VERSION ""

NS_ :

BS_:

BU_: L_3HKBD L_FHPTC L_ATCU L_2HKBD L_PCM L_ATCU_vMON L_EVNT L_HKBD L_RHPTC

BO_ 859 L_ATCU_Lib_11: 8 L_ATCU
 SG_ L_ATCU_Lib_Opt2LHModSwTyp : 0|2@1+ (1,0) [0|3] ""  L_ATCU_vMON
 SG_ L_ATCU_Lib_Opt2ndModBtn : 10|2@1+ (1,0) [0|3] ""  L_ATCU_vMON
 SG_ L_ATCU_Lib_Opt2ndOffSwTyp : 12|2@1+ (1,0) [0|3] ""  L_ATCU_vMON
 SG_ L_ATCU_Lib_Opt2ndTmpBtn : 14|2@1+ (1,0) [0|3] ""  L_ATCU_vMON
 SG_ L_ATCU_Lib_OptADS : 16|1@1+ (1,0) [0|1] ""  L_ATCU_vMON
 SG_ L_ATCU_Lib_OptAfterBlow : 17|1@1+ (1,0) [0|1] ""  L_ATCU_vMON
 SG_ L_ATCU_Lib_OptAutoStep : 18|2@1+ (1,0) [0|3] ""  L_ATCU_vMON
 SG_ L_ATCU_Lib_Opt2ndAutoBtn : 2|2@1+ (1,0) [0|3] ""  L_ATCU_vMON
 SG_ L_ATCU_Lib_OptAutoSwTyp : 20|1@1+ (1,0) [0|1] ""  L_ATCU_vMON
 SG_ L_ATCU_Lib_OptBATCoolingTyp : 21|2@1+ (1,0) [0|3] ""  L_ATCU_vMON
 SG_ L_ATCU_Lib_OptBlrSwKnob : 23|1@1+ (1,0) [0|1] ""  L_ATCU_vMON
 SG_ L_ATCU_Lib_OptComp : 24|3@1+ (1,0) [0|7] ""  L_ATCU_vMON
 SG_ L_ATCU_Lib_OptDrvHndSide : 27|1@1+ (1,0) [0|1] ""  L_ATCU_vMON
 SG_ L_ATCU_Lib_OptDrvOnly : 28|1@1+ (1,0) [0|1] ""  L_ATCU_vMON
 SG_ L_ATCU_Lib_OptFineDust : 29|1@1+ (1,0) [0|1] ""  L_ATCU_vMON
 SG_ L_ATCU_Lib_OptCoolHeatSeat : 30|2@1+ (1,0) [0|3] ""  L_ATCU_vMON
 SG_ L_ATCU_Lib_OptPTCTyp : 32|2@1+ (1,0) [0|3] ""  L_ATCU_vMON
 SG_ L_ATCU_Lib_OptLCDDisp : 34|2@1+ (1,0) [0|3] ""  L_ATCU_vMON
 SG_ L_ATCU_Lib_OptModSwTyp : 36|2@1+ (1,0) [0|3] ""  L_ATCU_vMON
 SG_ L_ATCU_Lib_OptOffSwTyp : 38|2@1+ (1,0) [0|3] ""  L_ATCU_vMON
 SG_ L_ATCU_Lib_Opt2ndAutoStep : 4|2@1+ (1,0) [0|3] ""  L_ATCU_vMON
 SG_ L_ATCU_Lib_OptNetworkTyp : 40|3@1+ (1,0) [0|7] ""  L_ATCU_vMON
 SG_ L_ATCU_Lib_OptPTCStep : 43|2@1+ (1,0) [0|3] ""  L_ATCU_vMON
 SG_ L_ATCU_Lib_OptPTG : 45|1@1+ (1,0) [0|1] ""  L_ATCU_vMON
 SG_ L_ATCU_Lib_OptROATyp : 46|1@1+ (1,0) [0|1] ""  L_ATCU_vMON
 SG_ L_ATCU_Lib_OptVRLED : 47|1@1+ (1,0) [0|1] ""  L_ATCU_vMON
 SG_ L_ATCU_Lib_OptRgn : 48|4@1+ (1,0) [0|15] ""  L_ATCU_vMON
 SG_ L_ATCU_Lib_OptSchdldVent : 52|1@1+ (1,0) [0|1] ""  L_ATCU_vMON
 SG_ L_ATCU_Lib_OptIntakeSwTyp : 53|1@1+ (1,0) [0|1] ""  L_ATCU_vMON
 SG_ L_ATCU_Lib_OptStrHeat : 54|2@1+ (1,0) [0|3] ""  L_ATCU_vMON
 SG_ L_ATCU_Lib_OptSync : 56|1@1+ (1,0) [0|1] ""  L_ATCU_vMON
 SG_ L_ATCU_Lib_OptTempSwKnob : 57|1@1+ (1,0) [0|1] ""  L_ATCU_vMON
 SG_ L_ATCU_Lib_OptThermostat : 58|1@1+ (1,0) [0|1] ""  L_ATCU_vMON
 SG_ L_ATCU_Lib_OptVehTyp : 59|3@1+ (1,0) [0|7] ""  L_ATCU_vMON
 SG_ L_ATCU_Lib_Opt2ndAutoSwTyp : 6|1@1+ (1,0) [0|1] ""  L_ATCU_vMON
 SG_ L_ATCU_Lib_OptWheelDrivePos : 62|2@1+ (1,0) [0|3] ""  L_ATCU_vMON
 SG_ L_ATCU_Lib_Opt2ndTempSwKnob : 7|1@1+ (1,0) [0|1] ""  L_ATCU_vMON
 SG_ L_ATCU_Lib_Opt2ndBlrBtn : 8|2@1+ (1,0) [0|3] ""  L_ATCU_vMON

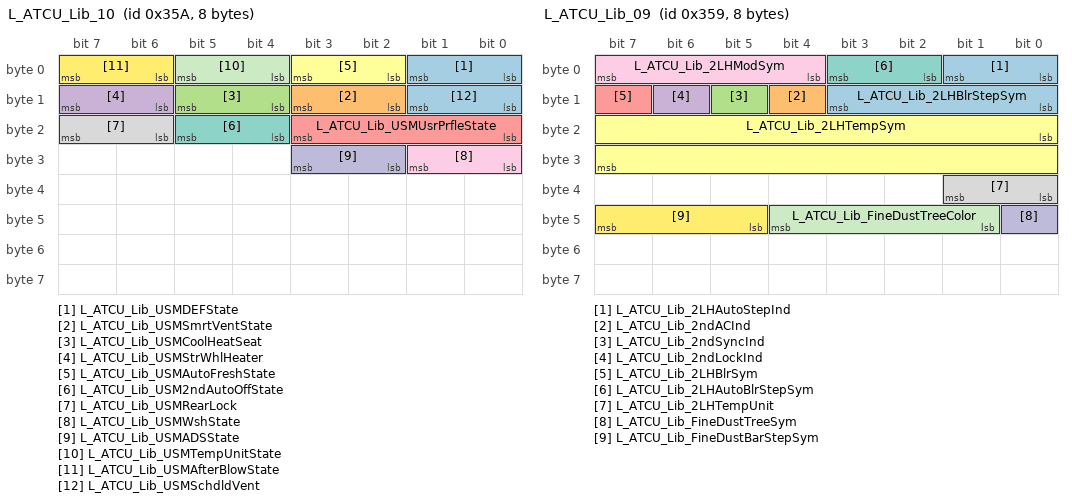
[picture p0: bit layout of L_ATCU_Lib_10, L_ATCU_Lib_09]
BO_ 858 L_ATCU_Lib_10: 8 L_ATCU
 SG_ L_ATCU_Lib_USMDEFState : 0|2@1+ (1,0) [0|1] ""  L_ATCU_vMON
 SG_ L_ATCU_Lib_USMSmrtVentState : 10|2@1+ (1,0) [0|3] ""  L_ATCU_vMON
 SG_ L_ATCU_Lib_USMCoolHeatSeat : 12|2@1+ (1,0) [0|3] ""  L_ATCU_vMON
 SG_ L_ATCU_Lib_USMStrWhlHeater : 14|2@1+ (1,0) [0|3] ""  L_ATCU_vMON
 SG_ L_ATCU_Lib_USMUsrPrfleState : 16|4@1+ (1,0) [0|15] ""  L_ATCU_vMON
 SG_ L_ATCU_Lib_USMAutoFreshState : 2|2@1+ (1,0) [0|1] ""  L_ATCU_vMON
 SG_ L_ATCU_Lib_USM2ndAutoOffState : 20|2@1+ (1,0) [0|3] ""  L_ATCU_vMON
 SG_ L_ATCU_Lib_USMRearLock : 22|2@1+ (1,0) [0|3] ""  L_ATCU_vMON
 SG_ L_ATCU_Lib_USMWshState : 24|2@1+ (1,0) [0|1] ""  L_ATCU_vMON
 SG_ L_ATCU_Lib_USMADSState : 26|2@1+ (1,0) [0|1] ""  L_ATCU_vMON
 SG_ L_ATCU_Lib_USMTempUnitState : 4|2@1+ (1,0) [0|3] ""  L_ATCU_vMON
 SG_ L_ATCU_Lib_USMAfterBlowState : 6|2@1+ (1,0) [0|3] ""  L_ATCU_vMON
 SG_ L_ATCU_Lib_USMSchdldVent : 8|2@1+ (1,0) [0|3] ""  L_ATCU_vMON

BO_ 857 L_ATCU_Lib_09: 8 L_ATCU
 SG_ L_ATCU_Lib_2LHAutoStepInd : 0|2@1+ (1,0) [0|3] ""  L_ATCU_vMON
 SG_ L_ATCU_Lib_2ndACInd : 12|1@1+ (1,0) [0|1] ""  L_ATCU_vMON
 SG_ L_ATCU_Lib_2ndSyncInd : 13|1@1+ (1,0) [0|1] ""  L_ATCU_vMON
 SG_ L_ATCU_Lib_2ndLockInd : 14|1@1+ (1,0) [0|1] ""  L_ATCU_vMON
 SG_ L_ATCU_Lib_2LHBlrSym : 15|1@1+ (1,0) [0|1] ""  L_ATCU_vMON
 SG_ L_ATCU_Lib_2LHTempSym : 16|16@1+ (1,0) [0|65535] ""  L_ATCU_vMON
 SG_ L_ATCU_Lib_2LHAutoBlrStepSym : 2|2@1+ (1,0) [0|3] ""  L_ATCU_vMON
 SG_ L_ATCU_Lib_2LHTempUnit : 32|2@1+ (1,0) [0|3] ""  L_ATCU_vMON
 SG_ L_ATCU_Lib_2LHModSym : 4|4@1+ (1,0) [0|15] ""  L_ATCU_vMON
 SG_ L_ATCU_Lib_FineDustTreeSym : 40|1@1+ (1,0) [0|1] ""  L_ATCU_vMON
 SG_ L_ATCU_Lib_FineDustTreeColor : 41|4@1+ (1,0) [0|15] ""  L_ATCU_vMON
 SG_ L_ATCU_Lib_FineDustBarStepSym : 45|3@1+ (1,0) [0|7] ""  L_ATCU_vMON
 SG_ L_ATCU_Lib_2LHBlrStepSym : 8|4@1+ (1,0) [0|15] ""  L_ATCU_vMON

BO_ 856 L_ATCU_Lib_08: 8 L_ATCU
 SG_ L_ATCU_Lib_AutoStepInd : 0|2@1+ (1,0) [0|3] ""  L_ATCU_vMON
 SG_ L_ATCU_Lib_BlrSym : 10|1@1+ (1,0) [0|1] ""  L_ATCU_vMON
 SG_ L_ATCU_Lib_BlrStepSym : 11|4@1+ (1,0) [0|15] ""  L_ATCU_vMON
 SG_ L_ATCU_Lib_IntakeRECInd : 15|1@1+ (1,0) [0|1] ""  L_ATCU_vMON
 SG_ L_ATCU_Lib_IntakeFREInd : 16|1@1+ (1,0) [0|1] ""  L_ATCU_vMON
 SG_ L_ATCU_Lib_ACInd : 17|1@1+ (1,0) [0|1] ""  L_ATCU_vMON
 SG_ L_ATCU_Lib_DEFInd : 18|1@1+ (1,0) [0|1] ""  L_ATCU_vMON
 SG_ L_ATCU_Lib_SyncInd : 19|1@1+ (1,0) [0|1] ""  L_ATCU_vMON
 SG_ L_ATCU_Lib_AutoBlrStepSym : 2|2@1+ (1,0) [0|3] ""  L_ATCU_vMON
 SG_ L_ATCU_Lib_DrvOnly : 20|1@1+ (1,0) [0|1] ""  L_ATCU_vMON
 SG_ L_ATCU_Lib_ADSSym : 21|1@1+ (1,0) [0|1] ""  L_ATCU_vMON
 SG_ L_ATCU_Lib_ModVentInd : 22|1@1+ (1,0) [0|1] ""  L_ATCU_vMON
 SG_ L_ATCU_Lib_DrvTempSym : 24|16@1+ (1,0) [0|65535] ""  L_ATCU_vMON
 SG_ L_ATCU_Lib_ModSym : 4|4@1+ (1,0) [0|15] ""  L_ATCU_vMON
 SG_ L_ATCU_Lib_AstTempSym : 40|16@1+ (1,0) [0|65535] ""  L_ATCU_vMON
 SG_ L_ATCU_Lib_DrvTempUnitSym : 56|2@1+ (1,0) [0|3] ""  L_ATCU_vMON
 SG_ L_ATCU_Lib_ModFloorInd : 8|1@1+ (1,0) [0|1] ""  L_ATCU_vMON
 SG_ L_ATCU_Lib_ModDEFInd : 9|1@1+ (1,0) [0|1] ""  L_ATCU_vMON

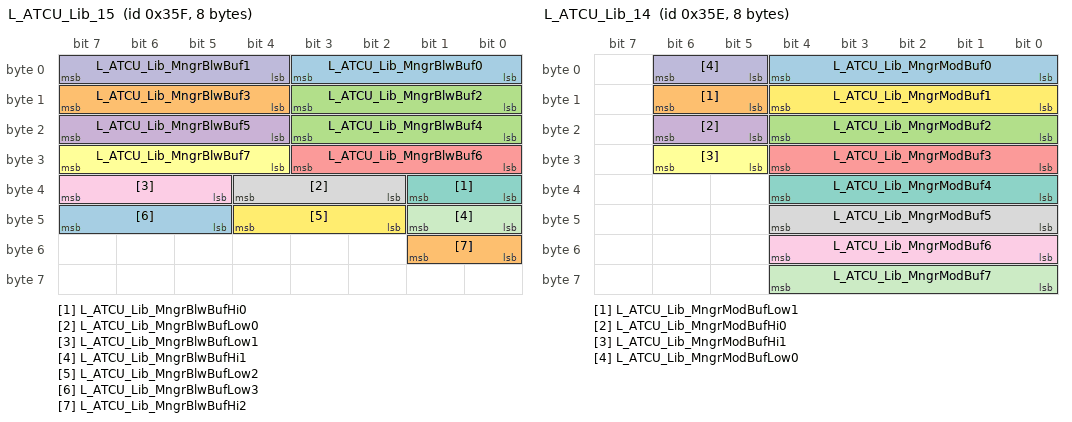
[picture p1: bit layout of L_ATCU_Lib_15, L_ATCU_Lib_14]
BO_ 863 L_ATCU_Lib_15: 8 L_ATCU
 SG_ L_ATCU_Lib_MngrBlwBuf0 : 0|4@1+ (1,0) [0|15] ""  L_ATCU_vMON
 SG_ L_ATCU_Lib_MngrBlwBuf3 : 12|4@1+ (1,0) [0|15] ""  L_ATCU_vMON
 SG_ L_ATCU_Lib_MngrBlwBuf4 : 16|4@1+ (1,0) [0|15] ""  L_ATCU_vMON
 SG_ L_ATCU_Lib_MngrBlwBuf5 : 20|4@1+ (1,0) [0|15] ""  L_ATCU_vMON
 SG_ L_ATCU_Lib_MngrBlwBuf6 : 24|4@1+ (1,0) [0|15] ""  L_ATCU_vMON
 SG_ L_ATCU_Lib_MngrBlwBuf7 : 28|4@1+ (1,0) [0|15] ""  L_ATCU_vMON
 SG_ L_ATCU_Lib_MngrBlwBufHi0 : 32|2@1+ (1,0) [0|3] ""  L_ATCU_vMON
 SG_ L_ATCU_Lib_MngrBlwBufLow0 : 34|3@1+ (1,0) [0|7] ""  L_ATCU_vMON
 SG_ L_ATCU_Lib_MngrBlwBufLow1 : 37|3@1+ (1,0) [0|7] ""  L_ATCU_vMON
 SG_ L_ATCU_Lib_MngrBlwBuf1 : 4|4@1+ (1,0) [0|15] ""  L_ATCU_vMON
 SG_ L_ATCU_Lib_MngrBlwBufHi1 : 40|2@1+ (1,0) [0|3] ""  L_ATCU_vMON
 SG_ L_ATCU_Lib_MngrBlwBufLow2 : 42|3@1+ (1,0) [0|7] ""  L_ATCU_vMON
 SG_ L_ATCU_Lib_MngrBlwBufLow3 : 45|3@1+ (1,0) [0|7] ""  L_ATCU_vMON
 SG_ L_ATCU_Lib_MngrBlwBufHi2 : 48|2@1+ (1,0) [0|3] ""  L_ATCU_vMON
 SG_ L_ATCU_Lib_MngrBlwBuf2 : 8|4@1+ (1,0) [0|15] ""  L_ATCU_vMON

BO_ 862 L_ATCU_Lib_14: 8 L_ATCU
 SG_ L_ATCU_Lib_MngrModBuf0 : 0|5@1+ (1,0) [0|31] ""  L_ATCU_vMON
 SG_ L_ATCU_Lib_MngrModBufLow1 : 13|2@1+ (1,0) [0|3] ""  L_ATCU_vMON
 SG_ L_ATCU_Lib_MngrModBuf2 : 16|5@1+ (1,0) [0|31] ""  L_ATCU_vMON
 SG_ L_ATCU_Lib_MngrModBufHi0 : 21|2@1+ (1,0) [0|3] ""  L_ATCU_vMON
 SG_ L_ATCU_Lib_MngrModBuf3 : 24|5@1+ (1,0) [0|31] ""  L_ATCU_vMON
 SG_ L_ATCU_Lib_MngrModBufHi1 : 29|2@1+ (1,0) [0|3] ""  L_ATCU_vMON
 SG_ L_ATCU_Lib_MngrModBuf4 : 32|5@1+ (1,0) [0|31] ""  L_ATCU_vMON
 SG_ L_ATCU_Lib_MngrModBuf5 : 40|5@1+ (1,0) [0|31] ""  L_ATCU_vMON
 SG_ L_ATCU_Lib_MngrModBuf6 : 48|5@1+ (1,0) [0|31] ""  L_ATCU_vMON
 SG_ L_ATCU_Lib_MngrModBufLow0 : 5|2@1+ (1,0) [0|3] ""  L_ATCU_vMON
 SG_ L_ATCU_Lib_MngrModBuf7 : 56|5@1+ (1,0) [0|31] ""  L_ATCU_vMON
 SG_ L_ATCU_Lib_MngrModBuf1 : 8|5@1+ (1,0) [0|31] ""  L_ATCU_vMON

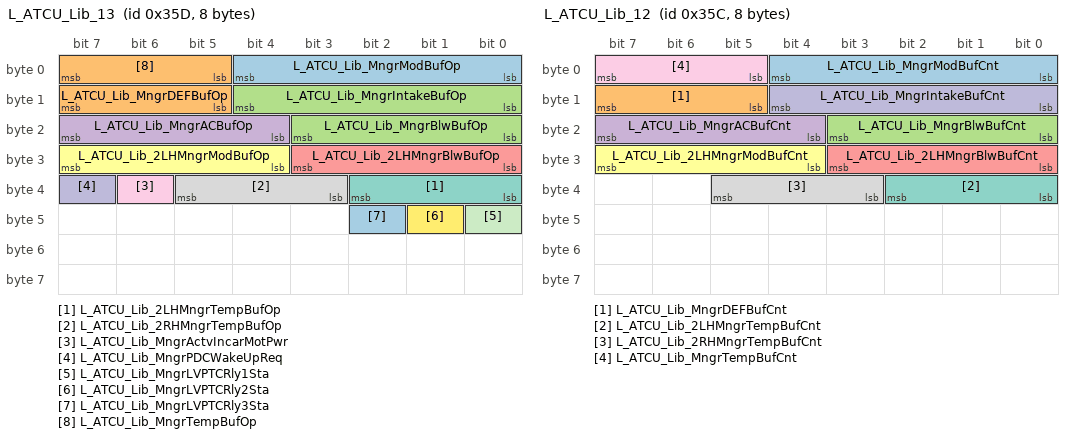
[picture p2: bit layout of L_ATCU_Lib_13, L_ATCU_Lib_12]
BO_ 861 L_ATCU_Lib_13: 8 L_ATCU
 SG_ L_ATCU_Lib_MngrModBufOp : 0|5@1+ (1,0) [0|31] ""  L_ATCU_vMON
 SG_ L_ATCU_Lib_MngrDEFBufOp : 13|3@1+ (1,0) [0|7] ""  L_ATCU_vMON
 SG_ L_ATCU_Lib_MngrBlwBufOp : 16|4@1+ (1,0) [0|15] ""  L_ATCU_vMON
 SG_ L_ATCU_Lib_MngrACBufOp : 20|4@1+ (1,0) [0|15] ""  L_ATCU_vMON
 SG_ L_ATCU_Lib_2LHMngrBlwBufOp : 24|4@1+ (1,0) [0|15] ""  L_ATCU_vMON
 SG_ L_ATCU_Lib_2LHMngrModBufOp : 28|4@1+ (1,0) [0|15] ""  L_ATCU_vMON
 SG_ L_ATCU_Lib_2LHMngrTempBufOp : 32|3@1+ (1,0) [0|7] ""  L_ATCU_vMON
 SG_ L_ATCU_Lib_2RHMngrTempBufOp : 35|3@1+ (1,0) [0|7] ""  L_ATCU_vMON
 SG_ L_ATCU_Lib_MngrActvIncarMotPwr : 38|1@1+ (1,0) [0|1] ""  L_ATCU_vMON
 SG_ L_ATCU_Lib_MngrPDCWakeUpReq : 39|1@1+ (1,0) [0|1] ""  L_ATCU_vMON
 SG_ L_ATCU_Lib_MngrLVPTCRly1Sta : 40|1@1+ (1,0) [0|1] ""  L_ATCU_vMON
 SG_ L_ATCU_Lib_MngrLVPTCRly2Sta : 41|1@1+ (1,0) [0|1] ""  L_ATCU_vMON
 SG_ L_ATCU_Lib_MngrLVPTCRly3Sta : 42|1@1+ (1,0) [0|1] ""  L_ATCU_vMON
 SG_ L_ATCU_Lib_MngrTempBufOp : 5|3@1+ (1,0) [0|7] ""  L_ATCU_vMON
 SG_ L_ATCU_Lib_MngrIntakeBufOp : 8|5@1+ (1,0) [0|31] ""  L_ATCU_vMON

BO_ 860 L_ATCU_Lib_12: 8 L_ATCU
 SG_ L_ATCU_Lib_MngrModBufCnt : 0|5@1+ (1,0) [0|31] ""  L_ATCU_vMON
 SG_ L_ATCU_Lib_MngrDEFBufCnt : 13|3@1+ (1,0) [0|7] ""  L_ATCU_vMON
 SG_ L_ATCU_Lib_MngrBlwBufCnt : 16|4@1+ (1,0) [0|15] ""  L_ATCU_vMON
 SG_ L_ATCU_Lib_MngrACBufCnt : 20|4@1+ (1,0) [0|15] ""  L_ATCU_vMON
 SG_ L_ATCU_Lib_2LHMngrBlwBufCnt : 24|4@1+ (1,0) [0|15] ""  L_ATCU_vMON
 SG_ L_ATCU_Lib_2LHMngrModBufCnt : 28|4@1+ (1,0) [0|15] ""  L_ATCU_vMON
 SG_ L_ATCU_Lib_2LHMngrTempBufCnt : 32|3@1+ (1,0) [0|7] ""  L_ATCU_vMON
 SG_ L_ATCU_Lib_2RHMngrTempBufCnt : 35|3@1+ (1,0) [0|7] ""  L_ATCU_vMON
 SG_ L_ATCU_Lib_MngrTempBufCnt : 5|3@1+ (1,0) [0|7] ""  L_ATCU_vMON
 SG_ L_ATCU_Lib_MngrIntakeBufCnt : 8|5@1+ (1,0) [0|31] ""  L_ATCU_vMON

BO_ 834 L_ATCU_MON_49: 8 L_ATCU_vMON
 SG_ MON_DiagCOM_AcnOpPerm : 0|2@1+ (1,0) [0|0] ""  L_ATCU
 SG_ MON_DiagCOM_BMSTmout : 10|2@1+ (1,0) [0|0] ""  L_ATCU
 SG_ MON_DiagCOM_DrvClHtStOpt : 12|2@1+ (1,0) [0|0] ""  L_ATCU
 SG_ MON_DiagCOM_AstClHtStOpt : 14|2@1+ (1,0) [0|0] ""  L_ATCU
 SG_ MON_DiagCOM_EcoModSw : 16|2@1+ (1,0) [0|0] ""  L_ATCU
 SG_ MON_DiagCOM_EcompTmout : 18|2@1+ (1,0) [0|0] ""  L_ATCU
 SG_ MON_DiagCOM_APT : 2|2@1+ (1,0) [0|0] ""  L_ATCU
 SG_ MON_DiagCOM_EMSVehSpd : 20|2@1+ (1,0) [0|0] ""  L_ATCU
 SG_ MON_DiagCOM_EngCool : 22|2@1+ (1,0) [0|0] ""  L_ATCU
 SG_ MON_DiagCOM_EngOpMod : 24|2@1+ (1,0) [0|0] ""  L_ATCU
 SG_ MON_DiagCOM_HEVRdy : 26|2@1+ (1,0) [0|0] ""  L_ATCU
 SG_ MON_DiagCOM_HVPTCTmout : 28|2@1+ (1,0) [0|0] ""  L_ATCU
 SG_ MON_DiagCOM_LDCWatt : 30|2@1+ (1,0) [0|0] ""  L_ATCU
 SG_ MON_DiagCOM_LHPhoto : 32|2@1+ (1,0) [0|0] ""  L_ATCU
 SG_ MON_DiagCOM_MainRlyOnSta : 34|2@1+ (1,0) [0|0] ""  L_ATCU
 SG_ MON_DiagCOM_MCUTmout : 36|2@1+ (1,0) [0|0] ""  L_ATCU
 SG_ MON_DiagCOM_PMSnsr : 38|2@1+ (1,0) [0|0] ""  L_ATCU
 SG_ MON_DiagCOM_BatChlrEXVDiag : 4|2@1+ (1,0) [0|0] ""  L_ATCU
 SG_ MON_DiagCOM_PnlBusOff : 40|2@1+ (1,0) [0|0] ""  L_ATCU
 SG_ MON_DiagCOM_PTGOpt : 42|2@1+ (1,0) [0|0] ""  L_ATCU
 SG_ MON_DiagCOM_RHPhoto : 44|2@1+ (1,0) [0|0] ""  L_ATCU
 SG_ MON_DiagCOM_RPM : 46|2@1+ (1,0) [0|0] ""  L_ATCU
 SG_ MON_DiagCOM_SideMirAmb : 48|2@1+ (1,0) [0|0] ""  L_ATCU
 SG_ MON_DiagCOM_ServiceMod : 50|2@1+ (1,0) [0|0] ""  L_ATCU
 SG_ MON_DiagCOM_StrHtOpt : 52|2@1+ (1,0) [0|0] ""  L_ATCU
 SG_ MON_DiagCOM_TCUVehSpd : 54|2@1+ (1,0) [0|0] ""  L_ATCU
 SG_ MON_DiagCOM_Torque : 56|2@1+ (1,0) [0|0] ""  L_ATCU
 SG_ MON_DiagCOM_VehBusOff : 58|2@1+ (1,0) [0|0] ""  L_ATCU
 SG_ MON_DiagCOM_BATSoc : 6|2@1+ (1,0) [0|0] ""  L_ATCU
 SG_ MON_DiagCOM_WhlSpd : 60|2@1+ (1,0) [0|0] ""  L_ATCU
 SG_ MON_DiagCOM_ClmtBusOff : 62|2@1+ (1,0) [0|0] ""  L_ATCU
 SG_ MON_DiagCOM_BMSIntakeReq : 8|2@1+ (1,0) [0|0] ""  L_ATCU

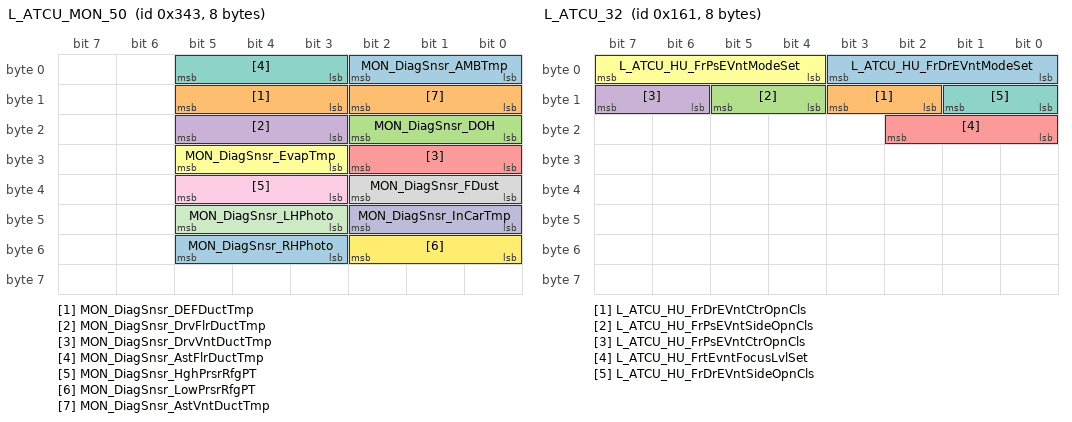
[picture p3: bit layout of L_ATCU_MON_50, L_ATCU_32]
BO_ 835 L_ATCU_MON_50: 8 L_ATCU_vMON
 SG_ MON_DiagSnsr_AMBTmp : 0|3@1+ (1,0) [0|0] ""  L_ATCU
 SG_ MON_DiagSnsr_DEFDuctTmp : 11|3@1+ (1,0) [0|0] ""  L_ATCU
 SG_ MON_DiagSnsr_DOH : 16|3@1+ (1,0) [0|0] ""  L_ATCU
 SG_ MON_DiagSnsr_DrvFlrDuctTmp : 19|3@1+ (1,0) [0|0] ""  L_ATCU
 SG_ MON_DiagSnsr_DrvVntDuctTmp : 24|3@1+ (1,0) [0|0] ""  L_ATCU
 SG_ MON_DiagSnsr_EvapTmp : 27|3@1+ (1,0) [0|0] ""  L_ATCU
 SG_ MON_DiagSnsr_AstFlrDuctTmp : 3|3@1+ (1,0) [0|0] ""  L_ATCU
 SG_ MON_DiagSnsr_FDust : 32|3@1+ (1,0) [0|0] ""  L_ATCU
 SG_ MON_DiagSnsr_HghPrsrRfgPT : 35|3@1+ (1,0) [0|0] ""  L_ATCU
 SG_ MON_DiagSnsr_InCarTmp : 40|3@1+ (1,0) [0|0] ""  L_ATCU
 SG_ MON_DiagSnsr_LHPhoto : 43|3@1+ (1,0) [0|0] ""  L_ATCU
 SG_ MON_DiagSnsr_LowPrsrRfgPT : 48|3@1+ (1,0) [0|0] ""  L_ATCU
 SG_ MON_DiagSnsr_RHPhoto : 51|3@1+ (1,0) [0|0] ""  L_ATCU
 SG_ MON_DiagSnsr_AstVntDuctTmp : 8|3@1+ (1,0) [0|0] ""  L_ATCU

BO_ 833 L_ATCU_MON_48: 8 L_ATCU_vMON
 SG_ MON_DiagAct_DrvModDrLck : 0|2@1+ (1,0) [0|0] ""  L_ATCU
 SG_ MON_DiagAct_AstModDrOpnSrt : 10|3@1+ (1,0) [0|0] ""  L_ATCU
 SG_ MON_DiagAct_AstTmpDrOpnSrt : 13|3@1+ (1,0) [0|0] ""  L_ATCU
 SG_ MON_DiagAct_DrvTmpDrLck : 16|2@1+ (1,0) [0|0] ""  L_ATCU
 SG_ MON_DiagAct_AstTmpDrLck : 18|2@1+ (1,0) [0|0] ""  L_ATCU
 SG_ MON_DiagAct_DrvModDrOpnSrt : 2|3@1+ (1,0) [0|0] ""  L_ATCU
 SG_ MON_DiagAct_DEFDrLck : 20|2@1+ (1,0) [0|0] ""  L_ATCU
 SG_ MON_DiagAct_IntakeDrLck : 22|2@1+ (1,0) [0|0] ""  L_ATCU
 SG_ MON_DiagAct_IntakeDrOpnSrt : 24|3@1+ (1,0) [0|0] ""  L_ATCU
 SG_ MON_DiagAct_DEFDrOpnSrt : 27|3@1+ (1,0) [0|0] ""  L_ATCU
 SG_ MON_DiagAct_ECompIntlck : 30|2@1+ (1,0) [0|0] ""  L_ATCU
 SG_ MON_DiagAct_HVPTCIntlck : 32|2@1+ (1,0) [0|0] ""  L_ATCU
 SG_ MON_DiagAct_BatChlrEXVOpnSrt : 34|3@1+ (1,0) [0|0] ""  L_ATCU
 SG_ MON_DiagAct_EvapTXVOpnSrt : 37|3@1+ (1,0) [0|0] ""  L_ATCU
 SG_ MON_DiagAct_FrtPWMBlr : 40|4@1+ (1,0) [0|0] ""  L_ATCU
 SG_ MON_DiagAct_ECV : 44|3@1+ (1,0) [0|0] ""  L_ATCU
 SG_ MON_DiagAct_Rfgrant : 48|3@1+ (1,0) [0|0] ""  L_ATCU
 SG_ MON_DiagAct_DrvTmpDrOpnSrt : 5|3@1+ (1,0) [0|0] ""  L_ATCU
 SG_ MON_DiagAct_VRLed : 52|3@1+ (1,0) [0|0] ""  L_ATCU
 SG_ MON_DiagAct_AstModDrLck : 8|2@1+ (1,0) [0|0] ""  L_ATCU

BO_ 353 L_ATCU_32: 8 L_ATCU
 SG_ L_ATCU_HU_FrDrEVntModeSet : 0|4@1+ (1,0) [0|0] ""  L_EVNT
 SG_ L_ATCU_HU_FrDrEVntCtrOpnCls : 10|2@1+ (1,0) [0|0] ""  L_EVNT
 SG_ L_ATCU_HU_FrPsEVntSideOpnCls : 12|2@1+ (1,0) [0|0] ""  L_EVNT
 SG_ L_ATCU_HU_FrPsEVntCtrOpnCls : 14|2@1+ (1,0) [0|0] ""  L_EVNT
 SG_ L_ATCU_HU_FrtEvntFocusLvlSet : 16|3@1+ (1,0) [0|0] ""  L_EVNT
 SG_ L_ATCU_HU_FrPsEVntModeSet : 4|4@1+ (1,0) [0|0] ""  L_EVNT
 SG_ L_ATCU_HU_FrDrEVntSideOpnCls : 8|2@1+ (1,0) [0|0] ""  L_EVNT

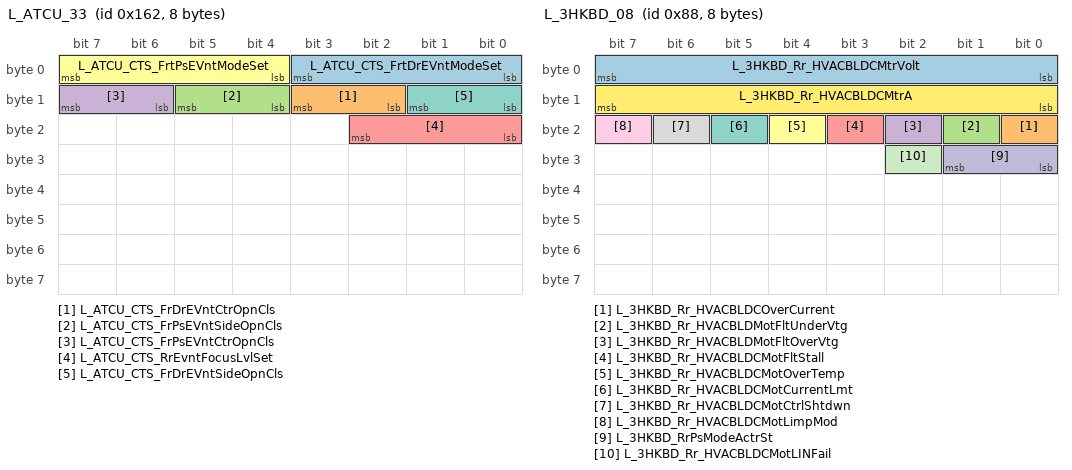
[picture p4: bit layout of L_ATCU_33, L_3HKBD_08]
BO_ 354 L_ATCU_33: 8 L_ATCU
 SG_ L_ATCU_CTS_FrtDrEVntModeSet : 0|4@1+ (1,0) [0|0] ""  L_EVNT
 SG_ L_ATCU_CTS_FrDrEVntCtrOpnCls : 10|2@1+ (1,0) [0|0] ""  L_EVNT
 SG_ L_ATCU_CTS_FrPsEVntSideOpnCls : 12|2@1+ (1,0) [0|0] ""  L_EVNT
 SG_ L_ATCU_CTS_FrPsEVntCtrOpnCls : 14|2@1+ (1,0) [0|0] ""  L_EVNT
 SG_ L_ATCU_CTS_RrEvntFocusLvlSet : 16|3@1+ (1,0) [0|0] ""  L_EVNT
 SG_ L_ATCU_CTS_FrtPsEVntModeSet : 4|4@1+ (1,0) [0|0] ""  L_EVNT
 SG_ L_ATCU_CTS_FrDrEVntSideOpnCls : 8|2@1+ (1,0) [0|0] ""  L_EVNT

BO_ 136 L_3HKBD_08: 8 L_3HKBD
 SG_ L_3HKBD_Rr_HVACBLDCMtrVolt : 0|8@1+ (0.1,0) [0|0] "V"  L_ATCU
 SG_ L_3HKBD_Rr_HVACBLDCOverCurrent : 16|1@1+ (1,0) [0|0] ""  L_ATCU
 SG_ L_3HKBD_Rr_HVACBLDMotFltUnderVtg : 17|1@1+ (1,0) [0|0] ""  L_ATCU
 SG_ L_3HKBD_Rr_HVACBLDMotFltOverVtg : 18|1@1+ (1,0) [0|0] ""  L_ATCU
 SG_ L_3HKBD_Rr_HVACBLDCMotFltStall : 19|1@1+ (1,0) [0|0] ""  L_ATCU
 SG_ L_3HKBD_Rr_HVACBLDCMotOverTemp : 20|1@1+ (1,0) [0|0] ""  L_ATCU
 SG_ L_3HKBD_Rr_HVACBLDCMotCurrentLmt : 21|1@1+ (1,0) [0|0] ""  L_ATCU
 SG_ L_3HKBD_Rr_HVACBLDCMotCtrlShtdwn : 22|1@1+ (1,0) [0|0] ""  L_ATCU
 SG_ L_3HKBD_Rr_HVACBLDCMotLimpMod : 23|1@1+ (1,0) [0|0] ""  L_ATCU
 SG_ L_3HKBD_RrPsModeActrSt : 24|2@1+ (1,0) [0|0] ""  L_ATCU
 SG_ L_3HKBD_Rr_HVACBLDCMotLINFail : 26|1@1+ (1,0) [0|0] ""  L_ATCU
 SG_ L_3HKBD_Rr_HVACBLDCMtrA : 8|8@1+ (0.2,0) [0|0] "A"  L_ATCU

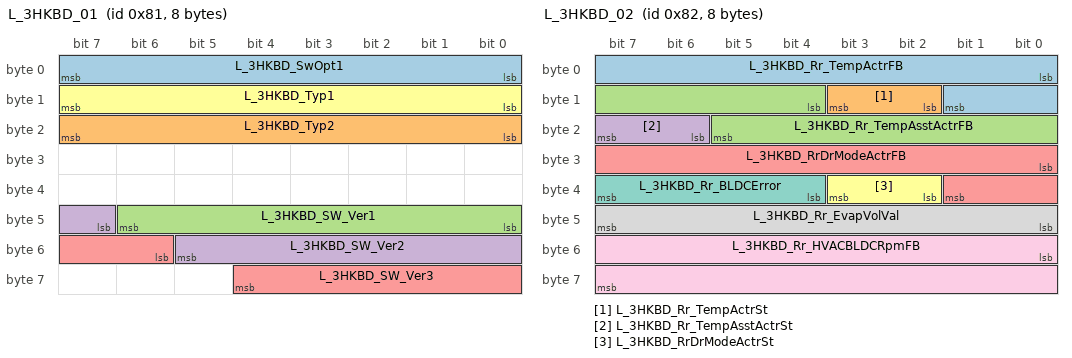
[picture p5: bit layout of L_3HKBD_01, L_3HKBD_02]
BO_ 129 L_3HKBD_01: 8 L_3HKBD
 SG_ L_3HKBD_SwOpt1 : 0|8@1+ (1,1) [0|0] ""  L_ATCU
 SG_ L_3HKBD_Typ2 : 16|8@1+ (1,0) [0|0] ""  L_ATCU
 SG_ L_3HKBD_SW_Ver1 : 40|7@1+ (1,0) [0|0] ""  L_ATCU_vMON
 SG_ L_3HKBD_SW_Ver2 : 47|7@1+ (1,0) [0|0] ""  L_ATCU_vMON
 SG_ L_3HKBD_SW_Ver3 : 54|7@1+ (1,0) [0|0] ""  L_ATCU_vMON
 SG_ L_3HKBD_Typ1 : 8|8@1+ (1,0) [0|0] ""  L_ATCU

BO_ 131 L_3HKBD_03: 8 L_3HKBD
 SG_ L_3HKBD_SwBtnTyp : 0|40@1+ (1,0) [0|0] ""  L_ATCU
 SG_ L_3HKBD_ResetOpSta : 62|2@1+ (1,0) [0|0] ""  L_ATCU

BO_ 130 L_3HKBD_02: 8 L_3HKBD
 SG_ L_3HKBD_Rr_TempActrFB : 0|10@1+ (1,0) [0|0] "AD"  L_ATCU
 SG_ L_3HKBD_Rr_TempActrSt : 10|2@1+ (1,0) [0|0] ""  L_ATCU
 SG_ L_3HKBD_Rr_TempAsstActrFB : 12|10@1+ (1,0) [0|0] "AD"  L_ATCU
 SG_ L_3HKBD_Rr_TempAsstActrSt : 22|2@1+ (1,0) [0|0] ""  L_ATCU
 SG_ L_3HKBD_RrDrModeActrFB : 24|10@1+ (1,0) [0|0] "AD"  L_ATCU
 SG_ L_3HKBD_RrDrModeActrSt : 34|2@1+ (1,0) [0|0] ""  L_ATCU
 SG_ L_3HKBD_Rr_BLDCError : 36|4@1+ (1,0) [0|0] ""  L_ATCU
 SG_ L_3HKBD_Rr_EvapVolVal : 40|8@1+ (0.02,0) [0|0] "V"  L_ATCU
 SG_ L_3HKBD_Rr_HVACBLDCRpmFB : 48|16@1+ (5,0) [0|0] "RPM"  L_ATCU

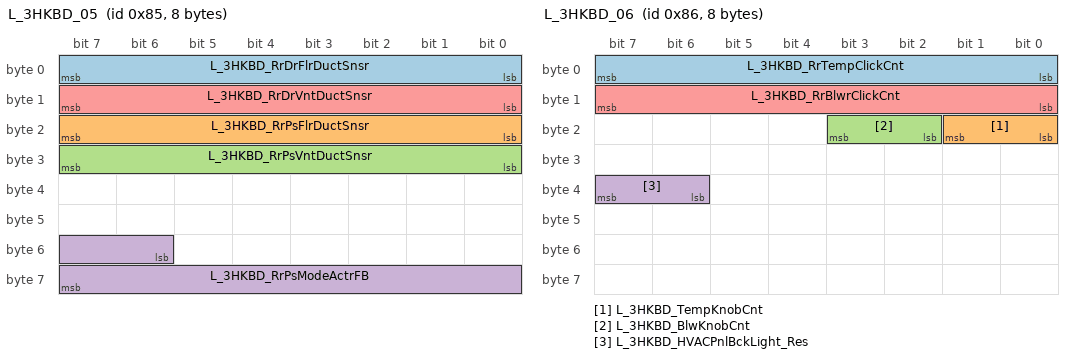
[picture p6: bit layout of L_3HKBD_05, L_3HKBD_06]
BO_ 133 L_3HKBD_05: 8 L_3HKBD
 SG_ L_3HKBD_RrDrFlrDuctSnsr : 0|8@1+ (0.02,0) [0|0] "V"  L_ATCU
 SG_ L_3HKBD_RrPsFlrDuctSnsr : 16|8@1+ (0.02,0) [0|0] ""  L_ATCU
 SG_ L_3HKBD_RrPsVntDuctSnsr : 24|8@1+ (0.02,0) [0|0] ""  L_ATCU
 SG_ L_3HKBD_RrPsModeActrFB : 54|10@1+ (1,0) [0|0] ""  L_ATCU
 SG_ L_3HKBD_RrDrVntDuctSnsr : 8|8@1+ (0.02,0) [0|0] "V"  L_ATCU

BO_ 132 L_3HKBD_04: 8 L_3HKBD
 SG_ L_3HKBD_RrTempDnSw : 0|1@1+ (1,1) [0|0] ""  L_ATCU
 SG_ L_3HKBD_RrTempUpSw : 1|1@1+ (1,1) [0|0] ""  L_ATCU
 SG_ L_3HKBD_RrAutoSw : 10|1@1+ (1,0) [0|0] ""  L_ATCU
 SG_ L_3HKBD_RrOffSw : 11|1@1+ (1,0) [0|0] ""  L_ATCU
 SG_ L_3HKBD_RrSyncSw : 12|1@1+ (1,0) [0|0] ""  L_ATCU
 SG_ L_3HKBD_RLStHtrSwReq : 13|1@1+ (1,0) [0|0] ""  L_ATCU
 SG_ L_3HKBD_RLStVentSwReq : 14|1@1+ (1,0) [0|0] ""  L_ATCU
 SG_ L_3HKBD_RRStHtrSwReq : 15|1@1+ (1,0) [0|0] ""  L_ATCU
 SG_ L_3HKBD_RRStVentSwReq : 16|1@1+ (1,0) [0|0] ""  L_ATCU
 SG_ L_3HKBD_RrBlwDnOffSw : 17|1@1+ (1,0) [0|0] ""  L_ATCU
 SG_ L_3HKBD_RrOnOffSet : 18|2@1+ (1,0) [0|0] ""  L_ATCU
 SG_ L_3HKBD_RrBlwDnSw : 2|1@1+ (1,0) [0|0] ""  L_ATCU
 SG_ L_3HKBD_RrblwUpMaxSw : 20|1@1+ (1,0) [0|0] ""  L_ATCU
 SG_ L_3HKBD_RrBlwUpSw : 3|1@1+ (1,0) [0|0] ""  L_ATCU
 SG_ L_3HKBD_RrModeDnSw : 4|1@1+ (1,0) [0|0] ""  L_ATCU
 SG_ L_3HKBD_RrModeUpSw : 5|1@1+ (1,0) [0|0] ""  L_ATCU
 SG_ L_3HKBD_RrModeSw : 6|1@1+ (1,0) [0|0] ""  L_ATCU
 SG_ L_3HKBD_RrModeVentSw : 7|1@1+ (1,0) [0|0] ""  L_ATCU
 SG_ L_3HKBD_RrModeFloorSw : 8|1@1+ (1,0) [0|0] ""  L_ATCU
 SG_ L_3HKBD_RrModeBiLvlSw : 9|1@1+ (1,0) [0|0] ""  L_ATCU

BO_ 134 L_3HKBD_06: 8 L_3HKBD
 SG_ L_3HKBD_RrTempClickCnt : 0|8@1+ (1,1) [0|0] ""  L_ATCU
 SG_ L_3HKBD_TempKnobCnt : 16|2@1+ (1,1) [0|0] ""  L_ATCU
 SG_ L_3HKBD_BlwKnobCnt : 18|2@1+ (1,1) [0|0] ""  L_ATCU
 SG_ L_3HKBD_HVACPnlBckLight_Res : 38|2@1+ (1,0) [0|0] ""  L_ATCU
 SG_ L_3HKBD_RrBlwrClickCnt : 8|8@1+ (1,1) [0|0] ""  L_ATCU

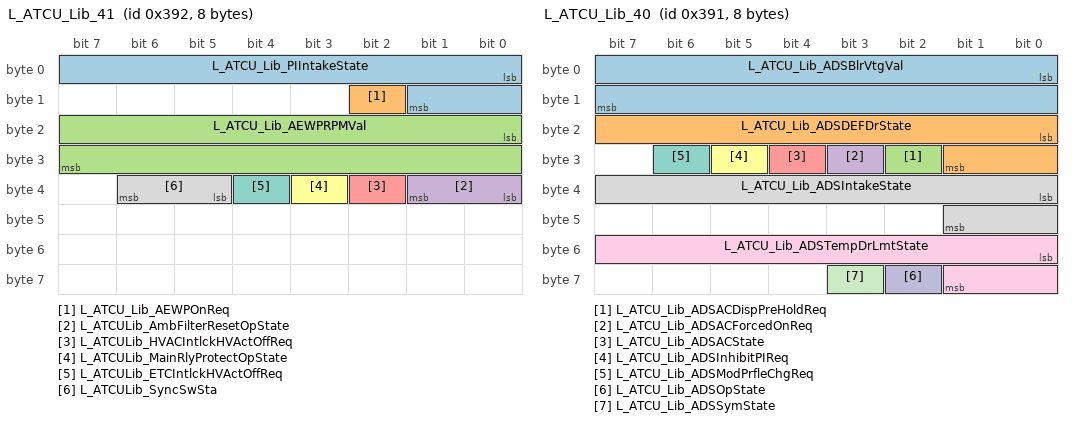
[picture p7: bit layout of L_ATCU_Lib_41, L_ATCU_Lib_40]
BO_ 914 L_ATCU_Lib_41: 8 L_ATCU
 SG_ L_ATCU_Lib_PIIntakeState : 0|10@1+ (1,0) [0|1023] ""  L_ATCU_vMON
 SG_ L_ATCU_Lib_AEWPOnReq : 10|1@1+ (1,0) [0|1] ""  L_ATCU_vMON
 SG_ L_ATCU_Lib_AEWPRPMVal : 16|16@1+ (1,0) [0|65535] ""  L_ATCU_vMON
 SG_ L_ATCULib_AmbFilterResetOpState : 32|2@1+ (1,0) [0|0] ""  L_ATCU_vMON
 SG_ L_ATCULib_HVACIntlckHVActOffReq : 34|1@1+ (1,0) [0|0] ""  L_ATCU_vMON
 SG_ L_ATCULib_MainRlyProtectOpState : 35|1@1+ (1,0) [0|0] ""  L_ATCU_vMON
 SG_ L_ATCULib_ETCIntlckHVActOffReq : 36|1@1+ (1,0) [0|0] ""  L_ATCU_vMON
 SG_ L_ATCULib_SyncSwSta : 37|2@1+ (1,0) [0|0] ""  L_ATCU_vMON

BO_ 913 L_ATCU_Lib_40: 8 L_ATCU
 SG_ L_ATCU_Lib_ADSBlrVtgVal : 0|16@1+ (1,0) [0|65535] ""  L_ATCU_vMON
 SG_ L_ATCU_Lib_ADSDEFDrState : 16|10@1+ (1,0) [0|1023] ""  L_ATCU_vMON
 SG_ L_ATCU_Lib_ADSACDispPreHoldReq : 26|1@1+ (1,0) [0|1] ""  L_ATCU_vMON
 SG_ L_ATCU_Lib_ADSACForcedOnReq : 27|1@1+ (1,0) [0|1] ""  L_ATCU_vMON
 SG_ L_ATCU_Lib_ADSACState : 28|1@1+ (1,0) [0|1] ""  L_ATCU_vMON
 SG_ L_ATCU_Lib_ADSInhibitPIReq : 29|1@1+ (1,0) [0|1] ""  L_ATCU_vMON
 SG_ L_ATCU_Lib_ADSModPrfleChgReq : 30|1@1+ (1,0) [0|1] ""  L_ATCU_vMON
 SG_ L_ATCU_Lib_ADSIntakeState : 32|10@1+ (1,0) [0|1023] ""  L_ATCU_vMON
 SG_ L_ATCU_Lib_ADSTempDrLmtState : 48|10@1+ (1,0) [0|1023] ""  L_ATCU_vMON
 SG_ L_ATCU_Lib_ADSOpState : 58|1@1+ (1,0) [0|1] ""  L_ATCU_vMON
 SG_ L_ATCU_Lib_ADSSymState : 59|1@1+ (1,0) [0|1] ""  L_ATCU_vMON

CM_ BO_ 129 "[PE] Periodic and On Event";
CM_ SG_ 129 L_3HKBD_SwOpt1 "3HKBD_SwitchOption1";
CM_ SG_ 129 L_3HKBD_Typ2 "3HKBD_Type2";
CM_ SG_ 129 L_3HKBD_SW_Ver1 "3HKBD_SoftWare_Version1";
CM_ SG_ 129 L_3HKBD_SW_Ver2 "3HKBD_SoftWare_Version2";
CM_ SG_ 129 L_3HKBD_SW_Ver3 "3HKBD_SoftWare_Version3";
CM_ SG_ 129 L_3HKBD_Typ1 "3HKBD_Type1";
CM_ BO_ 130 "[P] Periodic";
CM_ SG_ 130 L_3HKBD_Rr_TempActrFB "3HKBD_Rear_TempActuatorFeedback";
CM_ SG_ 130 L_3HKBD_Rr_TempActrSt "3HKBD_Rear_TempActuatorStatus";
CM_ SG_ 130 L_3HKBD_Rr_TempAsstActrFB "3HKBD_Rear_TempAssistActuatorFeedback";
CM_ SG_ 130 L_3HKBD_Rr_TempAsstActrSt "3HKBD_Rear_TempAssistActuatorStatus";
CM_ SG_ 130 L_3HKBD_RrDrModeActrFB "3HKBD_RearDriverModeActuatorFeedback";
CM_ SG_ 130 L_3HKBD_RrDrModeActrSt "3HKBD_RearDriverModeActuatorStatus";
CM_ SG_ 130 L_3HKBD_Rr_BLDCError "3HKBD_Rear_BLDCError";
CM_ SG_ 130 L_3HKBD_Rr_EvapVolVal "3HKBD_Rear_EvaporatorVoltageValue";
CM_ SG_ 130 L_3HKBD_Rr_HVACBLDCRpmFB "3HKBD_Rear_HVACBLDCRpmFeedBack";
CM_ BO_ 131 "[PE] Periodic and On Event";
CM_ SG_ 131 L_3HKBD_SwBtnTyp "3HKBD_SwitchButtonType";
CM_ SG_ 131 L_3HKBD_ResetOpSta "This signal indicates whether the reset operation has been completed or not";
CM_ BO_ 132 "[PE] Periodic and On Event";
CM_ SG_ 132 L_3HKBD_RrTempDnSw "3HKBD_RearTemperatureDownSwitch";
CM_ SG_ 132 L_3HKBD_RrTempUpSw "3HKBD_RearTemperatureUpSwitch";
CM_ SG_ 132 L_3HKBD_RrAutoSw "3HKBD_RearAutoSwitch";
CM_ SG_ 132 L_3HKBD_RrOffSw "3HKBD_RearOffSwitch";
CM_ SG_ 132 L_3HKBD_RrSyncSw "3HKBD_RearSyncSwitch";
CM_ SG_ 132 L_3HKBD_RLStHtrSwReq "3HKBD_RearLeftSeatHeaterSwitchRequest";
CM_ SG_ 132 L_3HKBD_RLStVentSwReq "3HKBD_RearLeftSeatVentSwitchRequest";
CM_ SG_ 132 L_3HKBD_RRStHtrSwReq "3HKBD_RearRightSeatHeaterSwitchRequest";
CM_ SG_ 132 L_3HKBD_RRStVentSwReq "3HKBD_RearRightSeatVentSwitchRequest";
CM_ SG_ 132 L_3HKBD_RrBlwDnOffSw "3HKBD_RearBlowerDownOffSwitch";
CM_ SG_ 132 L_3HKBD_RrOnOffSet "3HKBD_RearOnOffSet";
CM_ SG_ 132 L_3HKBD_RrBlwDnSw "3HKBD_RearBlowerDownSwitch";
CM_ SG_ 132 L_3HKBD_RrblwUpMaxSw "L_3HKBD_RrblwUpMaxSw";
CM_ SG_ 132 L_3HKBD_RrBlwUpSw "3HKBD_RearBlowerUpSwitch";
CM_ SG_ 132 L_3HKBD_RrModeDnSw "3HKBD_RearModeDownSwitch";
CM_ SG_ 132 L_3HKBD_RrModeUpSw "3HKBD_RearModeUpSwitch";
CM_ SG_ 132 L_3HKBD_RrModeSw "3HKBD_RearModeSwitch";
CM_ SG_ 132 L_3HKBD_RrModeVentSw "3HKBD_RearModeVentSwitch";
CM_ SG_ 132 L_3HKBD_RrModeFloorSw "3HKBD_RearModeFloorSwitch";
CM_ SG_ 132 L_3HKBD_RrModeBiLvlSw "3HKBD_RearModeBiLevelSwitch";
CM_ BO_ 133 "[PE] Periodic and On Event";
CM_ SG_ 133 L_3HKBD_RrDrFlrDuctSnsr "3HKBD_RearDriverFloorDuctSensor";
CM_ SG_ 133 L_3HKBD_RrPsFlrDuctSnsr "L_3HKBD_RearPassengerFloorDuctSensor";
CM_ SG_ 133 L_3HKBD_RrPsVntDuctSnsr "L_3HKBD_RearPassengerVentDuctSensor";
CM_ SG_ 133 L_3HKBD_RrPsModeActrFB "L_3HKBD_RearPassengerModeActuatorFeedback";
CM_ SG_ 133 L_3HKBD_RrDrVntDuctSnsr "3HKBD_RearDriverVentDuctSensor";
CM_ BO_ 134 "[EC] On Event and On Change";
CM_ SG_ 134 L_3HKBD_RrTempClickCnt "3HKBD_RearTemperatureClickCount";
CM_ SG_ 134 L_3HKBD_TempKnobCnt "3HKBD_TempKnobCount (for knobs rotate count)";
CM_ SG_ 134 L_3HKBD_BlwKnobCnt "3HKBD_BlowerKnobCount (for knobs rotate count)";
CM_ SG_ 134 L_3HKBD_HVACPnlBckLight_Res "Vehicle API HVAC Control Panel BackLight Response";
CM_ SG_ 134 L_3HKBD_RrBlwrClickCnt "3HKBD_RearBlowerClickCount";
CM_ BO_ 136 "[P] Periodic";
CM_ SG_ 136 L_3HKBD_Rr_HVACBLDCMtrVolt "3HKBD Rear HVAC BLDC Motor Voltage";
CM_ SG_ 136 L_3HKBD_Rr_HVACBLDCOverCurrent "3HKBD Rear HVAC BLDC Motor Over Current";
CM_ SG_ 136 L_3HKBD_Rr_HVACBLDMotFltUnderVtg "3HKBD Rear HVAC BLDC Motor Fault Under Voltage";
CM_ SG_ 136 L_3HKBD_Rr_HVACBLDMotFltOverVtg "3HKBD Rear HVAC BLDC Motor Fault Over Voltage";
CM_ SG_ 136 L_3HKBD_Rr_HVACBLDCMotFltStall "3HKBD Rear HVAC BLDC Motor Fault Stall";
CM_ SG_ 136 L_3HKBD_Rr_HVACBLDCMotOverTemp "3HKBD Rear HVAC BLDC Motor Over Temperature";
CM_ SG_ 136 L_3HKBD_Rr_HVACBLDCMotCurrentLmt "3HKBD Rear HVAC BLDC Motor Current Limitation";
CM_ SG_ 136 L_3HKBD_Rr_HVACBLDCMotCtrlShtdwn "3HKBD Rear HVAC BLDC Motor Control Shut Down";
CM_ SG_ 136 L_3HKBD_Rr_HVACBLDCMotLimpMod "3HKBD Rear HVAC BLDC Motor Limit Mod";
CM_ SG_ 136 L_3HKBD_RrPsModeActrSt "3HKBD_RearPassengerModeActuatorStatus";
CM_ SG_ 136 L_3HKBD_Rr_HVACBLDCMotLINFail "3HKBD Rear HVAC BLDC Motor LIN Communication Fail";
CM_ SG_ 136 L_3HKBD_Rr_HVACBLDCMtrA "3HKBD Rear HVAC BLDC Motor Ampere";
CM_ BO_ 353 "[EC] On Event and On Change";
CM_ SG_ 353 L_ATCU_HU_FrDrEVntModeSet "Front Driver Electric Vent Mode Set";
CM_ SG_ 353 L_ATCU_HU_FrDrEVntCtrOpnCls "Front Driver Electric Vent Center Open Close Signal";
CM_ SG_ 353 L_ATCU_HU_FrPsEVntSideOpnCls "Front Passenger Electric Vent Side Open Close Signal";
CM_ SG_ 353 L_ATCU_HU_FrPsEVntCtrOpnCls "Front Passenger Electric Vent Center Open Close Signal";
CM_ SG_ 353 L_ATCU_HU_FrtEvntFocusLvlSet "status setting of front Electric Vent focus mode height level";
CM_ SG_ 353 L_ATCU_HU_FrPsEVntModeSet "Front Passenger Electric Vent Mode Set";
CM_ SG_ 353 L_ATCU_HU_FrDrEVntSideOpnCls "Front Driver Electric Vent Side Open Close Signal";
CM_ BO_ 354 "[EC] On Event and On Change";
CM_ SG_ 354 L_ATCU_CTS_FrtDrEVntModeSet "Front Driver Electric Vent Mode Set";
CM_ SG_ 354 L_ATCU_CTS_FrDrEVntCtrOpnCls "Front Driver Electric Vent Center Open Close Signal";
CM_ SG_ 354 L_ATCU_CTS_FrPsEVntSideOpnCls "Front Passenger Electric Vent Side Open Close Signal";
CM_ SG_ 354 L_ATCU_CTS_FrPsEVntCtrOpnCls "Front Passenger Electric Vent Center Open Close Signal";
CM_ SG_ 354 L_ATCU_CTS_RrEvntFocusLvlSet "status setting of Rear Electric Vent focus mode height level";
CM_ SG_ 354 L_ATCU_CTS_FrtPsEVntModeSet "Front Passenger Electric Vent Mode Set";
CM_ SG_ 354 L_ATCU_CTS_FrDrEVntSideOpnCls "Front Driver Electric Vent Side Open Close Signal";
CM_ BO_ 856 "[PE] Periodic and On Event";
CM_ SG_ 856 L_ATCU_Lib_AutoStepInd "ATCU Library Auto Step Indicator";
CM_ SG_ 856 L_ATCU_Lib_BlrSym "ATCU Library Blower Symbol";
CM_ SG_ 856 L_ATCU_Lib_BlrStepSym "ATCU Library Blower Step Symbol";
CM_ SG_ 856 L_ATCU_Lib_IntakeRECInd "ATCU Library Intake REC Indicator";
CM_ SG_ 856 L_ATCU_Lib_IntakeFREInd "ATCU Library Intake FRE Indicator";
CM_ SG_ 856 L_ATCU_Lib_ACInd "ATCU Library AC Indicator";
CM_ SG_ 856 L_ATCU_Lib_DEFInd "ATCU Library DEF Indicator";
CM_ SG_ 856 L_ATCU_Lib_SyncInd "ATCU Library Sync Indicator";
CM_ SG_ 856 L_ATCU_Lib_AutoBlrStepSym "ATCU Library Auto Blower Step Text Symbol";
CM_ SG_ 856 L_ATCU_Lib_DrvOnly "ATCU Library DriverOnly Indicator";
CM_ SG_ 856 L_ATCU_Lib_ADSSym "ATCU Library ADS Symbol";
CM_ SG_ 856 L_ATCU_Lib_ModVentInd "ATCU Library Mode Vent Indicator";
CM_ SG_ 856 L_ATCU_Lib_DrvTempSym "ATCU Library Driverside Temp Symbol";
CM_ SG_ 856 L_ATCU_Lib_ModSym "ATCU Library Mode Symbol";
CM_ SG_ 856 L_ATCU_Lib_AstTempSym "ATCU Library Assistside Temp Symbol";
CM_ SG_ 856 L_ATCU_Lib_DrvTempUnitSym "ATCU Library TempUnit Symbol";
CM_ SG_ 856 L_ATCU_Lib_ModFloorInd "ATCU Library Mode Floor Indicator";
CM_ SG_ 856 L_ATCU_Lib_ModDEFInd "ATCU Library Mode DEF Indicator";
CM_ BO_ 857 "[PE] Periodic and On Event";
CM_ SG_ 857 L_ATCU_Lib_2LHAutoStepInd "ATCU Library 2nd Auto Step Indicator";
CM_ SG_ 857 L_ATCU_Lib_2ndACInd "ATCU Library 2nd AC Indicator";
CM_ SG_ 857 L_ATCU_Lib_2ndSyncInd "ATCU Library 2nd Sync Indicator";
CM_ SG_ 857 L_ATCU_Lib_2ndLockInd "ATCU Library 2nd Lock Indicator";
CM_ SG_ 857 L_ATCU_Lib_2LHBlrSym "ATCU Library 2nd Blower Symbol";
CM_ SG_ 857 L_ATCU_Lib_2LHTempSym "ATCU Library 2nd Leftside Temp Symbol";
CM_ SG_ 857 L_ATCU_Lib_2LHAutoBlrStepSym "ATCU Library 2nd Auto Blower Step Text Symbol";
CM_ SG_ 857 L_ATCU_Lib_2LHTempUnit "ATCU Library 2nd TempUnit Symbol";
CM_ SG_ 857 L_ATCU_Lib_2LHModSym "ATCU Library 2nd Mode Symbol";
CM_ SG_ 857 L_ATCU_Lib_FineDustTreeSym "ATCU Library FineDust Tree Symbol";
CM_ SG_ 857 L_ATCU_Lib_FineDustTreeColor "ATCU Library FineDust Tree Color";
CM_ SG_ 857 L_ATCU_Lib_FineDustBarStepSym "ATCU Library FineDust Bar Step";
CM_ SG_ 857 L_ATCU_Lib_2LHBlrStepSym "ATCU Library 2nd Blower Step Symbol";
CM_ BO_ 858 "[PE] Periodic and On Event";
CM_ SG_ 858 L_ATCU_Lib_USMDEFState "ATCU Library DEF USM";
CM_ SG_ 858 L_ATCU_Lib_USMSmrtVentState "ATCU Library SmartVent USM";
CM_ SG_ 858 L_ATCU_Lib_USMCoolHeatSeat "ATCU Library CoolHeatSeat USM";
CM_ SG_ 858 L_ATCU_Lib_USMStrWhlHeater "ATCU Library SteeringWheel Heater USM";
CM_ SG_ 858 L_ATCU_Lib_USMUsrPrfleState "ATCU Library UserProfile USM";
CM_ SG_ 858 L_ATCU_Lib_USMAutoFreshState "ATCU Library AutoFresh USM";
CM_ SG_ 858 L_ATCU_Lib_USM2ndAutoOffState "ATCU Library 2nd AutoOff USM";
CM_ SG_ 858 L_ATCU_Lib_USMRearLock "ATCU Library RearLock USM";
CM_ SG_ 858 L_ATCU_Lib_USMWshState "ATCU Library Washer USM";
CM_ SG_ 858 L_ATCU_Lib_USMADSState "ATCU Library ADS USM";
CM_ SG_ 858 L_ATCU_Lib_USMTempUnitState "ATCU Library TempUnit USM";
CM_ SG_ 858 L_ATCU_Lib_USMAfterBlowState "ATCU Library AfterBlow USM";
CM_ SG_ 858 L_ATCU_Lib_USMSchdldVent "ATCU Library SchdldVent USM";
CM_ BO_ 859 "[PE] Periodic and On Event";
CM_ SG_ 859 L_ATCU_Lib_Opt2LHModSwTyp "ATCU Library 2nd Leftside Mode Switch Type(1/2/3 button)";
CM_ SG_ 859 L_ATCU_Lib_Opt2ndModBtn "ATCU Library 2nd Mode Type (Single/Dual)";
CM_ SG_ 859 L_ATCU_Lib_Opt2ndOffSwTyp "ATCU Library 2nd Off Switch Type(Off/DownOff)";
CM_ SG_ 859 L_ATCU_Lib_Opt2ndTmpBtn "ATCU Library 2nd Temp Type (Single/Dual)";
CM_ SG_ 859 L_ATCU_Lib_OptADS "ATCU Library ADS Option";
CM_ SG_ 859 L_ATCU_Lib_OptAfterBlow "ATCU Library AfterBlow Option";
CM_ SG_ 859 L_ATCU_Lib_OptAutoStep "ATCU Library Auto Step Option";
CM_ SG_ 859 L_ATCU_Lib_Opt2ndAutoBtn "ATCU Library 2nd Auto Type (Single/Dual)";
CM_ SG_ 859 L_ATCU_Lib_OptAutoSwTyp "ATCU Library Auto Switch Type(1/2 button)";
CM_ SG_ 859 L_ATCU_Lib_OptBATCoolingTyp "ATCU Library Battery Cooling Type";
CM_ SG_ 859 L_ATCU_Lib_OptBlrSwKnob "ATCU Library Blower Knob Option";
CM_ SG_ 859 L_ATCU_Lib_OptComp "ATCU Library Compressor Type";
CM_ SG_ 859 L_ATCU_Lib_OptDrvHndSide "ATCU Library Driver Handel Side Type";
CM_ SG_ 859 L_ATCU_Lib_OptDrvOnly "ATCU Library DriverOnly Option";
CM_ SG_ 859 L_ATCU_Lib_OptFineDust "ATCU Library FineDust Option";
CM_ SG_ 859 L_ATCU_Lib_OptCoolHeatSeat "ATCU Library CoolHeatSeat Option";
CM_ SG_ 859 L_ATCU_Lib_OptPTCTyp "ATCU Library PTC Type";
CM_ SG_ 859 L_ATCU_Lib_OptLCDDisp "ATCU Library LCD Display Type";
CM_ SG_ 859 L_ATCU_Lib_OptModSwTyp "ATCU Library Mode Switch Type(1/2/3 button) Option";
CM_ SG_ 859 L_ATCU_Lib_OptOffSwTyp "ATCU Library Off Switch Type(Off/DownOff) Option";
CM_ SG_ 859 L_ATCU_Lib_Opt2ndAutoStep "ATCU Library 2nd Auto Step Option";
CM_ SG_ 859 L_ATCU_Lib_OptNetworkTyp "ATCU Library Network Type";
CM_ SG_ 859 L_ATCU_Lib_OptPTCStep "ATCU Library PTC Step Option";
CM_ SG_ 859 L_ATCU_Lib_OptPTG "ATCU Library PTG Option";
CM_ SG_ 859 L_ATCU_Lib_OptROATyp "ATCU Library ROA Option";
CM_ SG_ 859 L_ATCU_Lib_OptVRLED "ATCU Library VRLED Option";
CM_ SG_ 859 L_ATCU_Lib_OptRgn "ATCU Library Region Type";
CM_ SG_ 859 L_ATCU_Lib_OptSchdldVent "ATCU Library Schduled Ventilation Option";
CM_ SG_ 859 L_ATCU_Lib_OptIntakeSwTyp "ATCU Library Intake Switch Type(1/2 button) Option";
CM_ SG_ 859 L_ATCU_Lib_OptStrHeat "ATCU Library SteeringWheel Heater Option";
CM_ SG_ 859 L_ATCU_Lib_OptSync "ATCU Library Sync Option";
CM_ SG_ 859 L_ATCU_Lib_OptTempSwKnob "ATCU Library Temp Knob Option";
CM_ SG_ 859 L_ATCU_Lib_OptThermostat "ATCU Library Thermostat Option";
CM_ SG_ 859 L_ATCU_Lib_OptVehTyp "ATCU Library Vehicle Type (ICE/HEV/EV)";
CM_ SG_ 859 L_ATCU_Lib_Opt2ndAutoSwTyp "ATCU Library 2nd Auto Switch Type(1/2 button)";
CM_ SG_ 859 L_ATCU_Lib_OptWheelDrivePos "ATCU Library Drive Wheel Position Type";
CM_ SG_ 859 L_ATCU_Lib_Opt2ndTempSwKnob "ATCU Library 2nd Temp Knob Option";
CM_ SG_ 859 L_ATCU_Lib_Opt2ndBlrBtn "ATCU Library 2nd Blower Type (Single/Dual)";
CM_ BO_ 860 "[PE] Periodic and On Event";
CM_ SG_ 860 L_ATCU_Lib_MngrModBufCnt "ATCU Library Mode Manager Buffer Count";
CM_ SG_ 860 L_ATCU_Lib_MngrDEFBufCnt "ATCU Library DEF Manager Buffer Count";
CM_ SG_ 860 L_ATCU_Lib_MngrBlwBufCnt "ATCU Library Blower Manager Buffer Count";
CM_ SG_ 860 L_ATCU_Lib_MngrACBufCnt "ATCU Library AC Manager Buffer Count";
CM_ SG_ 860 L_ATCU_Lib_2LHMngrBlwBufCnt "ATCU Library 2nd Leftside Blower Manager Buffer Count";
CM_ SG_ 860 L_ATCU_Lib_2LHMngrModBufCnt "ATCU Library 2nd Leftside Mode Manager Buffer Count";
CM_ SG_ 860 L_ATCU_Lib_2LHMngrTempBufCnt "ATCU Library 2nd Leftside Temp Manager Buffer Count";
CM_ SG_ 860 L_ATCU_Lib_2RHMngrTempBufCnt "ATCU Library 2nd Rightside Temp Manager Buffer Count";
CM_ SG_ 860 L_ATCU_Lib_MngrTempBufCnt "ATCU Library Temp Manager Buffer Count";
CM_ SG_ 860 L_ATCU_Lib_MngrIntakeBufCnt "ATCU Library Intake Manager Buffer Count";
CM_ BO_ 861 "[PE] Periodic and On Event";
CM_ SG_ 861 L_ATCU_Lib_MngrModBufOp "ATCU Library Mode Manager Buffer Operating Function";
CM_ SG_ 861 L_ATCU_Lib_MngrDEFBufOp "ATCU Library DEF Manager Buffer Operating Function";
CM_ SG_ 861 L_ATCU_Lib_MngrBlwBufOp "ATCU Library Blower Manager Buffer Operating Function";
CM_ SG_ 861 L_ATCU_Lib_MngrACBufOp "ATCU Library AC Manager Buffer Operating Function";
CM_ SG_ 861 L_ATCU_Lib_2LHMngrBlwBufOp "ATCU Library 2nd Leftside Blower Manager Buffer Operating Function";
CM_ SG_ 861 L_ATCU_Lib_2LHMngrModBufOp "ATCU Library 2nd Leftside Mode Manager Buffer Operating Function";
CM_ SG_ 861 L_ATCU_Lib_2LHMngrTempBufOp "ATCU Library 2nd Leftside Temp Manager Buffer Operating Function";
CM_ SG_ 861 L_ATCU_Lib_2RHMngrTempBufOp "ATCU Library 2nd Rightside Temp Manager Buffer Operating Function";
CM_ SG_ 861 L_ATCU_Lib_MngrActvIncarMotPwr "ATCU Library Other Manager Active Type Incar Sensor Motor On Req";
CM_ SG_ 861 L_ATCU_Lib_MngrPDCWakeUpReq "ATCU Library Other Manager PDC Wake Up (Active Low) Req";
CM_ SG_ 861 L_ATCU_Lib_MngrLVPTCRly1Sta "ATCU Library Other Manager Low Voltage PTC Rly1 On Req";
CM_ SG_ 861 L_ATCU_Lib_MngrLVPTCRly2Sta "ATCU Library Other Manager Low Voltage PTC Rly2 On Req";
CM_ SG_ 861 L_ATCU_Lib_MngrLVPTCRly3Sta "ATCU Library Other Manager Low Voltage PTC Rly3 On Req";
CM_ SG_ 861 L_ATCU_Lib_MngrTempBufOp "ATCU Library Temp Manager Buffer Operating Function";
CM_ SG_ 861 L_ATCU_Lib_MngrIntakeBufOp "ATCU Library Intake Manager Buffer Operating Function";
CM_ BO_ 862 "[PE] Periodic and On Event";
CM_ SG_ 862 L_ATCU_Lib_MngrModBuf0 "ATCU Library Mode Manager Buffer 0";
CM_ SG_ 862 L_ATCU_Lib_MngrModBufLow1 "ATCU Library Mode Manager Lower Limit Buffer 1";
CM_ SG_ 862 L_ATCU_Lib_MngrModBuf2 "ATCU Library Mode Manager Buffer 2";
CM_ SG_ 862 L_ATCU_Lib_MngrModBufHi0 "ATCU Library Mode Manager Upper Limit Buffer 0";
CM_ SG_ 862 L_ATCU_Lib_MngrModBuf3 "ATCU Library Mode Manager Buffer 3";
CM_ SG_ 862 L_ATCU_Lib_MngrModBufHi1 "ATCU Library Mode Manager Upper Limit Buffer 1";
CM_ SG_ 862 L_ATCU_Lib_MngrModBuf4 "ATCU Library Mode Manager Buffer 4";
CM_ SG_ 862 L_ATCU_Lib_MngrModBuf5 "ATCU Library Mode Manager Buffer 5";
CM_ SG_ 862 L_ATCU_Lib_MngrModBuf6 "ATCU Library Mode Manager Buffer 6";
CM_ SG_ 862 L_ATCU_Lib_MngrModBufLow0 "ATCU Library Mode Manager Lower Limit Buffer 0";
CM_ SG_ 862 L_ATCU_Lib_MngrModBuf7 "ATCU Library Mode Manager Buffer 7";
CM_ SG_ 862 L_ATCU_Lib_MngrModBuf1 "ATCU Library Mode Manager Buffer 1";
CM_ BO_ 863 "[PE] Periodic and On Event";
CM_ SG_ 863 L_ATCU_Lib_MngrBlwBuf0 "ATCU Library Blower Manager Buffer 0";
CM_ SG_ 863 L_ATCU_Lib_MngrBlwBuf3 "ATCU Library Blower Manager Buffer 3";
CM_ SG_ 863 L_ATCU_Lib_MngrBlwBuf4 "ATCU Library Blower Manager Buffer 4";
CM_ SG_ 863 L_ATCU_Lib_MngrBlwBuf5 "ATCU Library Blower Manager Buffer 5";
CM_ SG_ 863 L_ATCU_Lib_MngrBlwBuf6 "ATCU Library Blower Manager Buffer 6";
CM_ SG_ 863 L_ATCU_Lib_MngrBlwBuf7 "ATCU Library Blower Manager Buffer 7";
CM_ SG_ 863 L_ATCU_Lib_MngrBlwBufHi0 "ATCU Library Blower Manager Upper Limit Buffer 0";
CM_ SG_ 863 L_ATCU_Lib_MngrBlwBufLow0 "ATCU Library Blower Manager Lower Limit Buffer 0";
CM_ SG_ 863 L_ATCU_Lib_MngrBlwBufLow1 "ATCU Library Blower Manager Lower Limit Buffer 1";
CM_ SG_ 863 L_ATCU_Lib_MngrBlwBuf1 "ATCU Library Blower Manager Buffer 1";
CM_ SG_ 863 L_ATCU_Lib_MngrBlwBufHi1 "ATCU Library Blower Manager Upper Limit Buffer 1";
CM_ SG_ 863 L_ATCU_Lib_MngrBlwBufLow2 "ATCU Library Blower Manager Lower Limit Buffer 2";
CM_ SG_ 863 L_ATCU_Lib_MngrBlwBufLow3 "ATCU Library Blower Manager Lower Limit Buffer 3";
CM_ SG_ 863 L_ATCU_Lib_MngrBlwBufHi2 "ATCU Library Blower Manager Upper Limit Buffer 2";
CM_ SG_ 863 L_ATCU_Lib_MngrBlwBuf2 "ATCU Library Blower Manager Buffer 2";
CM_ BO_ 913 "[PE] Periodic and On Event";
CM_ SG_ 913 L_ATCU_Lib_ADSBlrVtgVal "ATCU Library ADS Function Blower Voltage Value";
CM_ SG_ 913 L_ATCU_Lib_ADSDEFDrState "ATCU Library ADS Function DEF Door";
CM_ SG_ 913 L_ATCU_Lib_ADSACDispPreHoldReq "ATCU Library ADS Function AC Indicator Hold Req";
CM_ SG_ 913 L_ATCU_Lib_ADSACForcedOnReq "ATCU Library ADS Function AC Forced On Req";
CM_ SG_ 913 L_ATCU_Lib_ADSACState "ATCU Library ADS Function AC";
CM_ SG_ 913 L_ATCU_Lib_ADSInhibitPIReq "ATCU Library ADS Function Partial Intake Inhibit";
CM_ SG_ 913 L_ATCU_Lib_ADSModPrfleChgReq "ATCU Library ADS Function Mode Profile Change Req";
CM_ SG_ 913 L_ATCU_Lib_ADSIntakeState "ATCU Library ADS Function Intake";
CM_ SG_ 913 L_ATCU_Lib_ADSTempDrLmtState "ATCU Library ADS Function Temp Door Limit";
CM_ SG_ 913 L_ATCU_Lib_ADSOpState "ATCU Library ADS Function Operating State";
CM_ SG_ 913 L_ATCU_Lib_ADSSymState "ATCU Library ADS Function Symbol";
CM_ BO_ 914 "[PE] Periodic and On Event";
CM_ SG_ 914 L_ATCU_Lib_PIIntakeState "ATCU Library Partial Intake Function";
CM_ SG_ 914 L_ATCU_Lib_AEWPOnReq "ATCU Library AEWP Function AEWP On Req";
CM_ SG_ 914 L_ATCU_Lib_AEWPRPMVal "ATCU Library AEWP Function AEWP RPM";
CM_ SG_ 914 L_ATCULib_AmbFilterResetOpState "ATCU Library Amb FilterReset Operation State";
CM_ SG_ 914 L_ATCULib_HVACIntlckHVActOffReq "ATCU Library HVAC Interlock HVAct Off Request";
CM_ SG_ 914 L_ATCULib_MainRlyProtectOpState "ATCU Library MainRelay Protect Operation State";
CM_ SG_ 914 L_ATCULib_ETCIntlckHVActOffReq "ATCU Library ETC Interlock HVAct Off Request";
CM_ SG_ 914 L_ATCULib_SyncSwSta "ATCU Library SyncSW State";
CM_ BO_ 833 "[PE] Periodic and On Event";
CM_ SG_ 833 MON_DiagAct_DrvModDrLck "ATCU Monitoring Test mode Driver Mode Door Lock Diagnostic";
CM_ SG_ 833 MON_DiagAct_AstModDrOpnSrt "ATCU Monitoring Test mode Assist Mode Door Open Short Diagnostic";
CM_ SG_ 833 MON_DiagAct_AstTmpDrOpnSrt "ATCU Monitoring Test mode Assist Temp Door Open Short  Diagnostic";
CM_ SG_ 833 MON_DiagAct_DrvTmpDrLck "ATCU Monitoring Test mode Driver Temp Door Lock Diagnostic";
CM_ SG_ 833 MON_DiagAct_AstTmpDrLck "ATCU Monitoring Test mode Assist Temp Door Lock Diagnostic";
CM_ SG_ 833 MON_DiagAct_DrvModDrOpnSrt "ATCU Monitoring Test mode Driver Mode Door Open Short Diagnostic";
CM_ SG_ 833 MON_DiagAct_DEFDrLck "ATCU Monitoring Test mode Def Door Lock Diagnostic";
CM_ SG_ 833 MON_DiagAct_IntakeDrLck "ATCU Monitoring Test mode Intake Door Lock Diagnostic";
CM_ SG_ 833 MON_DiagAct_IntakeDrOpnSrt "ATCU Monitoring Test mode Intake Door Open Short Diagnostic";
CM_ SG_ 833 MON_DiagAct_DEFDrOpnSrt "ATCU Monitoring Test mode Def Door Open Short Diagnostic";
CM_ SG_ 833 MON_DiagAct_ECompIntlck "ATCU Monitoring Test mode Electric Comprossor Interlock Diagnostic";
CM_ SG_ 833 MON_DiagAct_HVPTCIntlck "ATCU Monitoring Test mode HVPTC Interlock Diagnostic";
CM_ SG_ 833 MON_DiagAct_BatChlrEXVOpnSrt "ATCU Monitoring Test mode BatChlrEXVOpnSrt Diagnostic";
CM_ SG_ 833 MON_DiagAct_EvapTXVOpnSrt "ATCU Monitoring Test mode EvapTXVOpnSrt Diagnostic";
CM_ SG_ 833 MON_DiagAct_FrtPWMBlr "ATCU Monitoring Test mode FrtPWMBlr Diagnostic";
CM_ SG_ 833 MON_DiagAct_ECV "ATCU Monitoring Test mode ECV Diagnostic";
CM_ SG_ 833 MON_DiagAct_Rfgrant "ATCU Monitoring Test mode Rfgrant Diagnostic";
CM_ SG_ 833 MON_DiagAct_DrvTmpDrOpnSrt "ATCU Monitoring Test mode Driver Temp Door Open Short  Diagnostic";
CM_ SG_ 833 MON_DiagAct_VRLed "ATCU Monitoring Test mode VRLed Diagnostic";
CM_ SG_ 833 MON_DiagAct_AstModDrLck "ATCU Monitoring Test mode Assist Mode Door Lock Diagnostic";
CM_ BO_ 834 "[PE] Periodic and On Event";
CM_ SG_ 834 MON_DiagCOM_AcnOpPerm "ATCU Monitoring Test mode AcnOpPerm Diagnostic";
CM_ SG_ 834 MON_DiagCOM_BMSTmout "ATCU Monitoring Test mode BMSTmout Diagnostic";
CM_ SG_ 834 MON_DiagCOM_DrvClHtStOpt "ATCU Monitoring Test mode DrvClHtStOpt Diagnostic";
CM_ SG_ 834 MON_DiagCOM_AstClHtStOpt "ATCU Monitoring Test mode AstClHtStOpt Diagnostic";
CM_ SG_ 834 MON_DiagCOM_EcoModSw "ATCU Monitoring Test mode EcoModSw Diagnostic";
CM_ SG_ 834 MON_DiagCOM_EcompTmout "ATCU Monitoring Test mode EcompTmout Diagnostic";
CM_ SG_ 834 MON_DiagCOM_APT "ATCU Monitoring Test mode APT Diagnostic";
CM_ SG_ 834 MON_DiagCOM_EMSVehSpd "ATCU Monitoring Test mode EMSVehSpd Diagnostic";
CM_ SG_ 834 MON_DiagCOM_EngCool "ATCU Monitoring Test mode EngCool Diagnostic";
CM_ SG_ 834 MON_DiagCOM_EngOpMod "ATCU Monitoring Test mode EngOpMod Diagnostic";
CM_ SG_ 834 MON_DiagCOM_HEVRdy "ATCU Monitoring Test mode HEVRdy Diagnostic";
CM_ SG_ 834 MON_DiagCOM_HVPTCTmout "ATCU Monitoring Test mode HVPTCTmout Diagnostic";
CM_ SG_ 834 MON_DiagCOM_LDCWatt "ATCU Monitoring Test mode LDCWatt Diagnostic";
CM_ SG_ 834 MON_DiagCOM_LHPhoto "ATCU Monitoring Test mode LHPhoto Diagnostic";
CM_ SG_ 834 MON_DiagCOM_MainRlyOnSta "ATCU Monitoring Test mode MainRlyOnSta Diagnostic";
CM_ SG_ 834 MON_DiagCOM_MCUTmout "ATCU Monitoring Test mode MCUTmout Diagnostic";
CM_ SG_ 834 MON_DiagCOM_PMSnsr "ATCU Monitoring Test mode PMSnsr Diagnostic";
CM_ SG_ 834 MON_DiagCOM_BatChlrEXVDiag "ATCU Monitoring Test mode BatChlrEXVDiag Diagnostic";
CM_ SG_ 834 MON_DiagCOM_PnlBusOff "ATCU Monitoring Test mode PnlBusOff Diagnostic";
CM_ SG_ 834 MON_DiagCOM_PTGOpt "ATCU Monitoring Test mode PTGOpt Diagnostic";
CM_ SG_ 834 MON_DiagCOM_RHPhoto "ATCU Monitoring Test mode RHPhoto Diagnostic";
CM_ SG_ 834 MON_DiagCOM_RPM "ATCU Monitoring Test mode RPM Diagnostic";
CM_ SG_ 834 MON_DiagCOM_SideMirAmb "ATCU Monitoring Test mode SideMirAmb Diagnostic";
CM_ SG_ 834 MON_DiagCOM_ServiceMod "ATCU Monitoring Test mode ServiceMod Diagnostic";
CM_ SG_ 834 MON_DiagCOM_StrHtOpt "ATCU Monitoring Test mode StrHtOpt Diagnostic";
CM_ SG_ 834 MON_DiagCOM_TCUVehSpd "ATCU Monitoring Test mode TCUVehSpd Diagnostic";
CM_ SG_ 834 MON_DiagCOM_Torque "ATCU Monitoring Test mode Torque Diagnostic";
CM_ SG_ 834 MON_DiagCOM_VehBusOff "ATCU Monitoring Test mode VehBusOff Diagnostic";
CM_ SG_ 834 MON_DiagCOM_BATSoc "ATCU Monitoring Test mode BATSoc Diagnostic";
CM_ SG_ 834 MON_DiagCOM_WhlSpd "ATCU Monitoring Test mode WhlSpd Diagnostic";
CM_ SG_ 834 MON_DiagCOM_ClmtBusOff "ATCU Monitoring Test mode lmtBusOff Diagnostic";
CM_ SG_ 834 MON_DiagCOM_BMSIntakeReq "ATCU Monitoring Test mode BMSIntakeReq Diagnostic";
CM_ BO_ 835 "[PE] Periodic and On Event";
CM_ SG_ 835 MON_DiagSnsr_AMBTmp "ATCU Monitoring Test mode AMBTmp Diagnostic";
CM_ SG_ 835 MON_DiagSnsr_DEFDuctTmp "ATCU Monitoring Test mode DEFDuctTmp Diagnostic";
CM_ SG_ 835 MON_DiagSnsr_DOH "ATCU Monitoring Test mode DOH Diagnostic";
CM_ SG_ 835 MON_DiagSnsr_DrvFlrDuctTmp "ATCU Monitoring Test mode DrvFlrDuctTmp Diagnostic";
CM_ SG_ 835 MON_DiagSnsr_DrvVntDuctTmp "ATCU Monitoring Test mode DrvVntDuctTmp Diagnostic";
CM_ SG_ 835 MON_DiagSnsr_EvapTmp "ATCU Monitoring Test mode EvapTmp Diagnostic";
CM_ SG_ 835 MON_DiagSnsr_AstFlrDuctTmp "ATCU Monitoring Test mode AstFlrDuctTmp Diagnostic";
CM_ SG_ 835 MON_DiagSnsr_FDust "ATCU Monitoring Test mode FDust Diagnostic";
CM_ SG_ 835 MON_DiagSnsr_HghPrsrRfgPT "ATCU Monitoring Test mode HghPrsrRfgPT Diagnostic";
CM_ SG_ 835 MON_DiagSnsr_InCarTmp "ATCU Monitoring Test mode InCarTmp Diagnostic";
CM_ SG_ 835 MON_DiagSnsr_LHPhoto "ATCU Monitoring Test mode LHPhoto Diagnostic";
CM_ SG_ 835 MON_DiagSnsr_LowPrsrRfgPT "ATCU Monitoring Test mode LowPrsrRfgPT Diagnostic";
CM_ SG_ 835 MON_DiagSnsr_RHPhoto "ATCU Monitoring Test mode RHPhoto Diagnostic";
CM_ SG_ 835 MON_DiagSnsr_AstVntDuctTmp "ATCU Monitoring Test mode AstVntDuctTmp Diagnostic";
BA_DEF_ BO_ "UsrMsgIDSforwardDeviation" INT 0 100 ;
BA_DEF_ BO_ "UsrMsgIDSbackwardDeviation" INT 50 1000 ;
BA_DEF_ BO_ "GenMsgCycleTime" INT 0 2000 ;
BA_DEF_ BO_ "GenMsgStartDelayTime" INT 0 2000 ;
BA_DEF_ BO_ "GenMsgSendType" ENUM "Cyclic","NoMsgSendType" ;
BA_DEF_ BO_ "GenMsgCycleTimeFast" INT 0 500 ;
BA_DEF_ BO_ "GenMsgDelayTime" INT 0 20 ;
BA_DEF_ BO_ "GenMsgILSupport" ENUM "No","Yes" ;
BA_DEF_ BO_ "GenMsgNrOfRepetition" INT 0 3 ;
BA_DEF_ BO_ "VFrameFormat" ENUM "StandardCAN","ExtendedCAN","reserved","reserved","reserved","reserved","reserved","reserved","reserved","reserved","reserved","reserved","reserved","reserved","StandardCAN_FD","ExtendedCAN_FD" ;
BA_DEF_ SG_ "UserSigValidity" ENUM "B+","ACC","IG","IG1","IG2","IG3","IG1 or IG2","IG1 or IG3","Undef" ;
BA_DEF_ SG_ "UsrSigPurpose" ENUM "Undef","FN","DIAG","DIAG(Req)","DIAG(Res)","DIAG(Phy)","DEV","CCP(Req)","CCP(Res)","NM","TP" ;
BA_DEF_ SG_ "GenSigStartValue" INT 0 1215752192 ;
BA_DEF_ SG_ "NetworkRequestHoldingTime" INT 0 65535 ;
BA_DEF_ SG_ "Description" STRING ;
BA_DEF_ SG_ "Version" STRING ;
BA_DEF_ SG_ "GenSigEnvVarType" ENUM "Int","Float","Undef" ;
BA_DEF_ SG_ "GenSigSendType" ENUM "Cyclic","OnWrite","OnWriteWithRepetition","OnChange","OnChangeWithRepetition","IfActive","IfActiveWithRepetition","NoSigSendType","OnChangeAndIfActive","OnChangeAndIfActiveWithRepetition" ;
BA_DEF_ SG_ "GwSigLatencyTime" INT 0 65536 ;
BA_DEF_ SG_ "GwSigMissingSourceType" ENUM "Undef","OldValue","DefaultValue","InitialValue" ;
BA_DEF_ SG_ "NWM-WakeupAllowed" ENUM "<n.a.>" ;
BA_DEF_ SG_ "RoutingFactor" INT 1 1215752192 ;
BA_DEF_REL_ BU_SG_REL_ "GenSigTimeoutTime" INT 0 7000 ;
BA_DEF_DEF_ "UsrMsgIDSforwardDeviation" 10 ;
BA_DEF_DEF_ "UsrMsgIDSbackwardDeviation" 100 ;
BA_DEF_DEF_ "GenMsgCycleTime" 200 ;
BA_DEF_DEF_ "GenMsgStartDelayTime" 0 ;
BA_DEF_DEF_ "GenMsgSendType" "NoMsgSendType" ;
BA_DEF_DEF_ "GenMsgCycleTimeFast" 40 ;
BA_DEF_DEF_ "GenMsgDelayTime" 20 ;
BA_DEF_DEF_ "GenMsgILSupport" "Yes" ;
BA_DEF_DEF_ "GenMsgNrOfRepetition" 3 ;
BA_DEF_DEF_ "VFrameFormat" "StandardCAN" ;
BA_DEF_DEF_ "UserSigValidity" "IG" ;
BA_DEF_DEF_ "UsrSigPurpose" "FN" ;
BA_DEF_DEF_ "GenSigStartValue" 0 ;
BA_DEF_DEF_ "NetworkRequestHoldingTime" 0 ;
BA_DEF_DEF_ "Description" "" ;
BA_DEF_DEF_ "Version" "" ;
BA_DEF_DEF_ "GenSigEnvVarType" "Undef" ;
BA_DEF_DEF_ "GenSigSendType" "NoSigSendType" ;
BA_DEF_DEF_ "GwSigLatencyTime" 40 ;
BA_DEF_DEF_ "GwSigMissingSourceType" "Undef" ;
BA_DEF_DEF_ "NWM-WakeupAllowed" "<n.a.>" ;
BA_DEF_DEF_ "RoutingFactor" 1 ;
BA_DEF_DEF_REL_ "GenSigTimeoutTime" 500 ;
BA_ "GenMsgSendType" BO_ 129 0;
BA_ "GenMsgCycleTime" BO_ 129 500;
BA_ "Description" SG_ 129 L_3HKBD_SwOpt1 "Bit0~2:RESERVED

Bit3~4:(Type):0 - None/1 - ATC/2 - MTC 

Bit5~7:RESERVED";
BA_ "GenSigSendType" SG_ 129 L_3HKBD_SwOpt1 4;
BA_ "UserSigValidity" SG_ 129 L_3HKBD_SwOpt1 7;
BA_REL_ "GenSigTimeoutTime" BU_SG_REL_ L_ATCU SG_ 129 L_3HKBD_SwOpt1 5000;
BA_ "Version" SG_ 129 L_3HKBD_SwOpt1 "23.11.09";
BA_ "Description" SG_ 129 L_3HKBD_Typ2 "Bit 0 : 3rd ROOF DR DUCT Snsr : 0 ? Not Apply / 1 ? Apply

Bit 1 : 3rd ROOF Ast DUCT Snsr : 0 ? Not Apply / 1 ? Apply

Bit 2 : 3rd FLOOR DR DUCT Snsr : 0 ? Not Apply / 1 ? Apply

Bit 3 : 3rd FLOOR Ast DUCT Snsr : 0 ? Not Apply / 1 - Apply

Bit 4 : RESERVED

Bit 5~6 (3rd Multi Auto Text):0 - Multi Auto State Text Not Applied/1 - Multi Auto State Text Display Only Applied/2 - Multi Auto State Text Display & Control Applied/3 ? RESERVED

Bit7:(3rd REAR LOCK):0 ? NON REAR LOCK/1 ? REAR LOCK";
BA_ "GenSigSendType" SG_ 129 L_3HKBD_Typ2 4;
BA_ "UserSigValidity" SG_ 129 L_3HKBD_Typ2 7;
BA_REL_ "GenSigTimeoutTime" BU_SG_REL_ L_ATCU SG_ 129 L_3HKBD_Typ2 5000;
BA_ "Version" SG_ 129 L_3HKBD_Typ2 "24.11.00";
BA_ "GenSigSendType" SG_ 129 L_3HKBD_SW_Ver1 4;
BA_ "UserSigValidity" SG_ 129 L_3HKBD_SW_Ver1 7;
BA_REL_ "GenSigTimeoutTime" BU_SG_REL_ L_ATCU_vMON SG_ 129 L_3HKBD_SW_Ver1 5000;
BA_ "Version" SG_ 129 L_3HKBD_SW_Ver1 "25.05.04";
BA_ "GenSigSendType" SG_ 129 L_3HKBD_SW_Ver2 4;
BA_ "UserSigValidity" SG_ 129 L_3HKBD_SW_Ver2 7;
BA_REL_ "GenSigTimeoutTime" BU_SG_REL_ L_ATCU_vMON SG_ 129 L_3HKBD_SW_Ver2 5000;
BA_ "Version" SG_ 129 L_3HKBD_SW_Ver2 "25.05.04";
BA_ "GenSigSendType" SG_ 129 L_3HKBD_SW_Ver3 4;
BA_ "UserSigValidity" SG_ 129 L_3HKBD_SW_Ver3 7;
BA_REL_ "GenSigTimeoutTime" BU_SG_REL_ L_ATCU_vMON SG_ 129 L_3HKBD_SW_Ver3 5000;
BA_ "Version" SG_ 129 L_3HKBD_SW_Ver3 "25.05.04";
BA_ "Description" SG_ 129 L_3HKBD_Typ1 "Bit 0~7 : RESERVED";
BA_ "GenSigSendType" SG_ 129 L_3HKBD_Typ1 4;
BA_ "UserSigValidity" SG_ 129 L_3HKBD_Typ1 7;
BA_REL_ "GenSigTimeoutTime" BU_SG_REL_ L_ATCU SG_ 129 L_3HKBD_Typ1 5000;
BA_ "Version" SG_ 129 L_3HKBD_Typ1 "24.02.01";
BA_ "GenMsgSendType" BO_ 130 0;
BA_ "GenMsgCycleTime" BO_ 130 20;
BA_ "GenMsgCycleTimeFast" BO_ 130 0;
BA_ "GenMsgNrOfRepetition" BO_ 130 0;
BA_ "GenMsgDelayTime" BO_ 130 0;
BA_ "UserSigValidity" SG_ 130 L_3HKBD_Rr_TempActrFB 7;
BA_ "Version" SG_ 130 L_3HKBD_Rr_TempActrFB "23.09.05";
BA_ "UserSigValidity" SG_ 130 L_3HKBD_Rr_TempActrSt 7;
BA_ "Version" SG_ 130 L_3HKBD_Rr_TempActrSt "23.09.01";
BA_ "UserSigValidity" SG_ 130 L_3HKBD_Rr_TempAsstActrFB 7;
BA_ "Version" SG_ 130 L_3HKBD_Rr_TempAsstActrFB "23.09.05";
BA_ "UserSigValidity" SG_ 130 L_3HKBD_Rr_TempAsstActrSt 7;
BA_ "Version" SG_ 130 L_3HKBD_Rr_TempAsstActrSt "23.09.01";
BA_ "UserSigValidity" SG_ 130 L_3HKBD_RrDrModeActrFB 7;
BA_ "Version" SG_ 130 L_3HKBD_RrDrModeActrFB "24.02.08";
BA_ "UserSigValidity" SG_ 130 L_3HKBD_RrDrModeActrSt 7;
BA_ "Version" SG_ 130 L_3HKBD_RrDrModeActrSt "24.02.08";
BA_ "UserSigValidity" SG_ 130 L_3HKBD_Rr_BLDCError 7;
BA_ "Version" SG_ 130 L_3HKBD_Rr_BLDCError "23.09.01";
BA_ "UserSigValidity" SG_ 130 L_3HKBD_Rr_EvapVolVal 7;
BA_ "Version" SG_ 130 L_3HKBD_Rr_EvapVolVal "23.09.05";
BA_ "Description" SG_ 130 L_3HKBD_Rr_HVACBLDCRpmFB "00H~3E8H:RPM = Factor * Hex + Offset/3E9H ~ FFFFH:RESERVED";
BA_ "UserSigValidity" SG_ 130 L_3HKBD_Rr_HVACBLDCRpmFB 7;
BA_ "Version" SG_ 130 L_3HKBD_Rr_HVACBLDCRpmFB "23.09.05";
BA_ "GenMsgSendType" BO_ 131 0;
BA_ "GenMsgCycleTime" BO_ 131 500;
BA_ "Description" SG_ 131 L_3HKBD_SwBtnTyp "Each bit for button type is defined as

0-None/1-Hardkey/2-Touch(Used Beep)/3-Touch(Not Used Beep)

Bit 0~1 : 3rd Temp Button / Bit 2~3 : 3rd Blower Button / Bit 4~5 : 3rd Mode Button / Bit 6~7 : 3rd Auto Button / Bit 8~9 : 3rd A/C Button / Bit 10~11 : 3rd Sync Button / Bit 12~13 : 3rd StHeatVnt Button / Bit 14~15 : OFF / 16~19 : Reserved";
BA_ "GenSigSendType" SG_ 131 L_3HKBD_SwBtnTyp 4;
BA_ "UserSigValidity" SG_ 131 L_3HKBD_SwBtnTyp 7;
BA_REL_ "GenSigTimeoutTime" BU_SG_REL_ L_ATCU SG_ 131 L_3HKBD_SwBtnTyp 5000;
BA_ "Version" SG_ 131 L_3HKBD_SwBtnTyp "23.11.09";
BA_ "Description" SG_ 131 L_3HKBD_ResetOpSta "This signal indicates whether the reset operation has been completed or not";
BA_ "GenSigSendType" SG_ 131 L_3HKBD_ResetOpSta 4;
BA_ "UserSigValidity" SG_ 131 L_3HKBD_ResetOpSta 0;
BA_REL_ "GenSigTimeoutTime" BU_SG_REL_ L_ATCU SG_ 131 L_3HKBD_ResetOpSta 1000;
BA_ "Version" SG_ 131 L_3HKBD_ResetOpSta "24.10.05";
BA_ "GenMsgSendType" BO_ 132 0;
BA_ "GenSigSendType" SG_ 132 L_3HKBD_RrTempDnSw 4;
BA_ "UserSigValidity" SG_ 132 L_3HKBD_RrTempDnSw 7;
BA_REL_ "GenSigTimeoutTime" BU_SG_REL_ L_ATCU SG_ 132 L_3HKBD_RrTempDnSw 1500;
BA_ "Version" SG_ 132 L_3HKBD_RrTempDnSw "23.09.01";
BA_ "GenSigSendType" SG_ 132 L_3HKBD_RrTempUpSw 4;
BA_ "UserSigValidity" SG_ 132 L_3HKBD_RrTempUpSw 7;
BA_REL_ "GenSigTimeoutTime" BU_SG_REL_ L_ATCU SG_ 132 L_3HKBD_RrTempUpSw 1500;
BA_ "Version" SG_ 132 L_3HKBD_RrTempUpSw "23.09.01";
BA_ "GenSigSendType" SG_ 132 L_3HKBD_RrAutoSw 4;
BA_ "UserSigValidity" SG_ 132 L_3HKBD_RrAutoSw 7;
BA_REL_ "GenSigTimeoutTime" BU_SG_REL_ L_ATCU SG_ 132 L_3HKBD_RrAutoSw 1500;
BA_ "Version" SG_ 132 L_3HKBD_RrAutoSw "23.09.01";
BA_ "GenSigSendType" SG_ 132 L_3HKBD_RrOffSw 4;
BA_ "UserSigValidity" SG_ 132 L_3HKBD_RrOffSw 7;
BA_REL_ "GenSigTimeoutTime" BU_SG_REL_ L_ATCU SG_ 132 L_3HKBD_RrOffSw 1500;
BA_ "Version" SG_ 132 L_3HKBD_RrOffSw "23.09.01";
BA_ "GenSigSendType" SG_ 132 L_3HKBD_RrSyncSw 4;
BA_ "UserSigValidity" SG_ 132 L_3HKBD_RrSyncSw 7;
BA_REL_ "GenSigTimeoutTime" BU_SG_REL_ L_ATCU SG_ 132 L_3HKBD_RrSyncSw 1500;
BA_ "Version" SG_ 132 L_3HKBD_RrSyncSw "23.09.01";
BA_ "GenSigSendType" SG_ 132 L_3HKBD_RLStHtrSwReq 4;
BA_ "UserSigValidity" SG_ 132 L_3HKBD_RLStHtrSwReq 7;
BA_REL_ "GenSigTimeoutTime" BU_SG_REL_ L_ATCU SG_ 132 L_3HKBD_RLStHtrSwReq 1500;
BA_ "Version" SG_ 132 L_3HKBD_RLStHtrSwReq "23.09.01";
BA_ "GenSigSendType" SG_ 132 L_3HKBD_RLStVentSwReq 4;
BA_ "UserSigValidity" SG_ 132 L_3HKBD_RLStVentSwReq 7;
BA_REL_ "GenSigTimeoutTime" BU_SG_REL_ L_ATCU SG_ 132 L_3HKBD_RLStVentSwReq 1500;
BA_ "Version" SG_ 132 L_3HKBD_RLStVentSwReq "23.09.01";
BA_ "GenSigSendType" SG_ 132 L_3HKBD_RRStHtrSwReq 4;
BA_ "UserSigValidity" SG_ 132 L_3HKBD_RRStHtrSwReq 7;
BA_REL_ "GenSigTimeoutTime" BU_SG_REL_ L_ATCU SG_ 132 L_3HKBD_RRStHtrSwReq 1500;
BA_ "Version" SG_ 132 L_3HKBD_RRStHtrSwReq "23.09.01";
BA_ "GenSigSendType" SG_ 132 L_3HKBD_RRStVentSwReq 4;
BA_ "UserSigValidity" SG_ 132 L_3HKBD_RRStVentSwReq 7;
BA_REL_ "GenSigTimeoutTime" BU_SG_REL_ L_ATCU SG_ 132 L_3HKBD_RRStVentSwReq 1500;
BA_ "Version" SG_ 132 L_3HKBD_RRStVentSwReq "23.09.01";
BA_ "GenSigSendType" SG_ 132 L_3HKBD_RrBlwDnOffSw 4;
BA_ "UserSigValidity" SG_ 132 L_3HKBD_RrBlwDnOffSw 7;
BA_REL_ "GenSigTimeoutTime" BU_SG_REL_ L_ATCU SG_ 132 L_3HKBD_RrBlwDnOffSw 1500;
BA_ "Version" SG_ 132 L_3HKBD_RrBlwDnOffSw "23.09.01";
BA_ "GenSigSendType" SG_ 132 L_3HKBD_RrOnOffSet 4;
BA_ "GenSigStartValue" SG_ 132 L_3HKBD_RrOnOffSet 3;
BA_ "UserSigValidity" SG_ 132 L_3HKBD_RrOnOffSet 7;
BA_REL_ "GenSigTimeoutTime" BU_SG_REL_ L_ATCU SG_ 132 L_3HKBD_RrOnOffSet 1500;
BA_ "Version" SG_ 132 L_3HKBD_RrOnOffSet "24.01.00";
BA_ "GenSigSendType" SG_ 132 L_3HKBD_RrBlwDnSw 4;
BA_ "UserSigValidity" SG_ 132 L_3HKBD_RrBlwDnSw 7;
BA_REL_ "GenSigTimeoutTime" BU_SG_REL_ L_ATCU SG_ 132 L_3HKBD_RrBlwDnSw 1500;
BA_ "Version" SG_ 132 L_3HKBD_RrBlwDnSw "23.09.01";
BA_ "GenSigSendType" SG_ 132 L_3HKBD_RrblwUpMaxSw 4;
BA_ "UserSigValidity" SG_ 132 L_3HKBD_RrblwUpMaxSw 7;
BA_REL_ "GenSigTimeoutTime" BU_SG_REL_ L_ATCU SG_ 132 L_3HKBD_RrblwUpMaxSw 1500;
BA_ "Version" SG_ 132 L_3HKBD_RrblwUpMaxSw "25.05.04";
BA_ "GenSigSendType" SG_ 132 L_3HKBD_RrBlwUpSw 4;
BA_ "UserSigValidity" SG_ 132 L_3HKBD_RrBlwUpSw 7;
BA_REL_ "GenSigTimeoutTime" BU_SG_REL_ L_ATCU SG_ 132 L_3HKBD_RrBlwUpSw 1500;
BA_ "Version" SG_ 132 L_3HKBD_RrBlwUpSw "23.09.01";
BA_ "GenSigSendType" SG_ 132 L_3HKBD_RrModeDnSw 4;
BA_ "UserSigValidity" SG_ 132 L_3HKBD_RrModeDnSw 7;
BA_REL_ "GenSigTimeoutTime" BU_SG_REL_ L_ATCU SG_ 132 L_3HKBD_RrModeDnSw 1500;
BA_ "Version" SG_ 132 L_3HKBD_RrModeDnSw "23.09.01";
BA_ "GenSigSendType" SG_ 132 L_3HKBD_RrModeUpSw 4;
BA_ "UserSigValidity" SG_ 132 L_3HKBD_RrModeUpSw 7;
BA_REL_ "GenSigTimeoutTime" BU_SG_REL_ L_ATCU SG_ 132 L_3HKBD_RrModeUpSw 1500;
BA_ "Version" SG_ 132 L_3HKBD_RrModeUpSw "23.09.01";
BA_ "GenSigSendType" SG_ 132 L_3HKBD_RrModeSw 4;
BA_ "UserSigValidity" SG_ 132 L_3HKBD_RrModeSw 7;
BA_REL_ "GenSigTimeoutTime" BU_SG_REL_ L_ATCU SG_ 132 L_3HKBD_RrModeSw 1500;
BA_ "Version" SG_ 132 L_3HKBD_RrModeSw "23.09.01";
BA_ "GenSigSendType" SG_ 132 L_3HKBD_RrModeVentSw 4;
BA_ "UserSigValidity" SG_ 132 L_3HKBD_RrModeVentSw 7;
BA_REL_ "GenSigTimeoutTime" BU_SG_REL_ L_ATCU SG_ 132 L_3HKBD_RrModeVentSw 1500;
BA_ "Version" SG_ 132 L_3HKBD_RrModeVentSw "23.09.01";
BA_ "GenSigSendType" SG_ 132 L_3HKBD_RrModeFloorSw 4;
BA_ "UserSigValidity" SG_ 132 L_3HKBD_RrModeFloorSw 7;
BA_REL_ "GenSigTimeoutTime" BU_SG_REL_ L_ATCU SG_ 132 L_3HKBD_RrModeFloorSw 1500;
BA_ "Version" SG_ 132 L_3HKBD_RrModeFloorSw "23.09.01";
BA_ "GenSigSendType" SG_ 132 L_3HKBD_RrModeBiLvlSw 4;
BA_ "UserSigValidity" SG_ 132 L_3HKBD_RrModeBiLvlSw 7;
BA_REL_ "GenSigTimeoutTime" BU_SG_REL_ L_ATCU SG_ 132 L_3HKBD_RrModeBiLvlSw 1500;
BA_ "Version" SG_ 132 L_3HKBD_RrModeBiLvlSw "23.09.01";
BA_ "GenMsgSendType" BO_ 133 0;
BA_ "GenSigSendType" SG_ 133 L_3HKBD_RrDrFlrDuctSnsr 4;
BA_ "UserSigValidity" SG_ 133 L_3HKBD_RrDrFlrDuctSnsr 7;
BA_REL_ "GenSigTimeoutTime" BU_SG_REL_ L_ATCU SG_ 133 L_3HKBD_RrDrFlrDuctSnsr 1500;
BA_ "Version" SG_ 133 L_3HKBD_RrDrFlrDuctSnsr "24.02.01";
BA_ "GenSigSendType" SG_ 133 L_3HKBD_RrPsFlrDuctSnsr 4;
BA_ "UserSigValidity" SG_ 133 L_3HKBD_RrPsFlrDuctSnsr 7;
BA_REL_ "GenSigTimeoutTime" BU_SG_REL_ L_ATCU SG_ 133 L_3HKBD_RrPsFlrDuctSnsr 1500;
BA_ "Version" SG_ 133 L_3HKBD_RrPsFlrDuctSnsr "24.02.08";
BA_ "GenSigSendType" SG_ 133 L_3HKBD_RrPsVntDuctSnsr 4;
BA_ "UserSigValidity" SG_ 133 L_3HKBD_RrPsVntDuctSnsr 7;
BA_REL_ "GenSigTimeoutTime" BU_SG_REL_ L_ATCU SG_ 133 L_3HKBD_RrPsVntDuctSnsr 1500;
BA_ "Version" SG_ 133 L_3HKBD_RrPsVntDuctSnsr "24.02.01";
BA_ "GenSigSendType" SG_ 133 L_3HKBD_RrPsModeActrFB 4;
BA_ "UserSigValidity" SG_ 133 L_3HKBD_RrPsModeActrFB 7;
BA_REL_ "GenSigTimeoutTime" BU_SG_REL_ L_ATCU SG_ 133 L_3HKBD_RrPsModeActrFB 1500;
BA_ "Version" SG_ 133 L_3HKBD_RrPsModeActrFB "24.02.08";
BA_ "GenSigSendType" SG_ 133 L_3HKBD_RrDrVntDuctSnsr 4;
BA_ "UserSigValidity" SG_ 133 L_3HKBD_RrDrVntDuctSnsr 7;
BA_REL_ "GenSigTimeoutTime" BU_SG_REL_ L_ATCU SG_ 133 L_3HKBD_RrDrVntDuctSnsr 1500;
BA_ "Version" SG_ 133 L_3HKBD_RrDrVntDuctSnsr "24.02.01";
BA_ "GenMsgCycleTime" BO_ 134 0;
BA_ "GenSigSendType" SG_ 134 L_3HKBD_RrTempClickCnt 4;
BA_ "GenSigStartValue" SG_ 134 L_3HKBD_RrTempClickCnt 255;
BA_ "UserSigValidity" SG_ 134 L_3HKBD_RrTempClickCnt 7;
BA_REL_ "GenSigTimeoutTime" BU_SG_REL_ L_ATCU SG_ 134 L_3HKBD_RrTempClickCnt 0;
BA_ "Version" SG_ 134 L_3HKBD_RrTempClickCnt "24.01.00";
BA_ "GenSigSendType" SG_ 134 L_3HKBD_TempKnobCnt 4;
BA_ "GenSigStartValue" SG_ 134 L_3HKBD_TempKnobCnt 3;
BA_ "UserSigValidity" SG_ 134 L_3HKBD_TempKnobCnt 7;
BA_REL_ "GenSigTimeoutTime" BU_SG_REL_ L_ATCU SG_ 134 L_3HKBD_TempKnobCnt 0;
BA_ "Version" SG_ 134 L_3HKBD_TempKnobCnt "24.01.00";
BA_ "GenSigSendType" SG_ 134 L_3HKBD_BlwKnobCnt 4;
BA_ "GenSigStartValue" SG_ 134 L_3HKBD_BlwKnobCnt 3;
BA_ "UserSigValidity" SG_ 134 L_3HKBD_BlwKnobCnt 7;
BA_REL_ "GenSigTimeoutTime" BU_SG_REL_ L_ATCU SG_ 134 L_3HKBD_BlwKnobCnt 0;
BA_ "Version" SG_ 134 L_3HKBD_BlwKnobCnt "24.01.00";
BA_ "Description" SG_ 134 L_3HKBD_HVACPnlBckLight_Res "Vehicle API HVAC Control Panel BackLight Response";
BA_ "GenSigSendType" SG_ 134 L_3HKBD_HVACPnlBckLight_Res 4;
BA_ "UserSigValidity" SG_ 134 L_3HKBD_HVACPnlBckLight_Res 7;
BA_REL_ "GenSigTimeoutTime" BU_SG_REL_ L_ATCU SG_ 134 L_3HKBD_HVACPnlBckLight_Res 0;
BA_ "Version" SG_ 134 L_3HKBD_HVACPnlBckLight_Res "25.08.06";
BA_ "GenSigSendType" SG_ 134 L_3HKBD_RrBlwrClickCnt 4;
BA_ "GenSigStartValue" SG_ 134 L_3HKBD_RrBlwrClickCnt 255;
BA_ "UserSigValidity" SG_ 134 L_3HKBD_RrBlwrClickCnt 7;
BA_REL_ "GenSigTimeoutTime" BU_SG_REL_ L_ATCU SG_ 134 L_3HKBD_RrBlwrClickCnt 0;
BA_ "Version" SG_ 134 L_3HKBD_RrBlwrClickCnt "24.01.00";
BA_ "GenMsgSendType" BO_ 136 0;
BA_ "GenMsgCycleTime" BO_ 136 20;
BA_ "GenMsgCycleTimeFast" BO_ 136 0;
BA_ "GenMsgNrOfRepetition" BO_ 136 0;
BA_ "GenMsgDelayTime" BO_ 136 0;
BA_ "UserSigValidity" SG_ 136 L_3HKBD_Rr_HVACBLDCMtrVolt 7;
BA_ "Version" SG_ 136 L_3HKBD_Rr_HVACBLDCMtrVolt "24.02.06";
BA_ "UserSigValidity" SG_ 136 L_3HKBD_Rr_HVACBLDCOverCurrent 7;
BA_ "Version" SG_ 136 L_3HKBD_Rr_HVACBLDCOverCurrent "24.02.06";
BA_ "UserSigValidity" SG_ 136 L_3HKBD_Rr_HVACBLDMotFltUnderVtg 7;
BA_ "Version" SG_ 136 L_3HKBD_Rr_HVACBLDMotFltUnderVtg "24.02.06";
BA_ "UserSigValidity" SG_ 136 L_3HKBD_Rr_HVACBLDMotFltOverVtg 7;
BA_ "Version" SG_ 136 L_3HKBD_Rr_HVACBLDMotFltOverVtg "24.02.06";
BA_ "UserSigValidity" SG_ 136 L_3HKBD_Rr_HVACBLDCMotFltStall 7;
BA_ "Version" SG_ 136 L_3HKBD_Rr_HVACBLDCMotFltStall "24.02.06";
BA_ "UserSigValidity" SG_ 136 L_3HKBD_Rr_HVACBLDCMotOverTemp 7;
BA_ "Version" SG_ 136 L_3HKBD_Rr_HVACBLDCMotOverTemp "24.02.06";
BA_ "UserSigValidity" SG_ 136 L_3HKBD_Rr_HVACBLDCMotCurrentLmt 7;
BA_ "Version" SG_ 136 L_3HKBD_Rr_HVACBLDCMotCurrentLmt "24.02.06";
BA_ "UserSigValidity" SG_ 136 L_3HKBD_Rr_HVACBLDCMotCtrlShtdwn 7;
BA_ "Version" SG_ 136 L_3HKBD_Rr_HVACBLDCMotCtrlShtdwn "24.02.06";
BA_ "UserSigValidity" SG_ 136 L_3HKBD_Rr_HVACBLDCMotLimpMod 7;
BA_ "Version" SG_ 136 L_3HKBD_Rr_HVACBLDCMotLimpMod "24.02.06";
BA_ "UserSigValidity" SG_ 136 L_3HKBD_RrPsModeActrSt 7;
BA_ "Version" SG_ 136 L_3HKBD_RrPsModeActrSt "24.02.08";
BA_ "UserSigValidity" SG_ 136 L_3HKBD_Rr_HVACBLDCMotLINFail 7;
BA_ "Version" SG_ 136 L_3HKBD_Rr_HVACBLDCMotLINFail "24.05.08";
BA_ "UserSigValidity" SG_ 136 L_3HKBD_Rr_HVACBLDCMtrA 7;
BA_ "Version" SG_ 136 L_3HKBD_Rr_HVACBLDCMtrA "24.02.06";
BA_ "GenMsgCycleTime" BO_ 353 0;
BA_ "Description" SG_ 353 L_ATCU_HU_FrDrEVntModeSet "Electric Vent Frt Driver Mode Signal";
BA_ "GenSigSendType" SG_ 353 L_ATCU_HU_FrDrEVntModeSet 4;
BA_ "UserSigValidity" SG_ 353 L_ATCU_HU_FrDrEVntModeSet 7;
BA_REL_ "GenSigTimeoutTime" BU_SG_REL_ L_EVNT SG_ 353 L_ATCU_HU_FrDrEVntModeSet 0;
BA_ "Version" SG_ 353 L_ATCU_HU_FrDrEVntModeSet "25.04.02";
BA_ "Description" SG_ 353 L_ATCU_HU_FrDrEVntCtrOpnCls "Electric Vent Frt Driver Center Vent Open/Close Signal";
BA_ "GenSigSendType" SG_ 353 L_ATCU_HU_FrDrEVntCtrOpnCls 4;
BA_ "UserSigValidity" SG_ 353 L_ATCU_HU_FrDrEVntCtrOpnCls 7;
BA_REL_ "GenSigTimeoutTime" BU_SG_REL_ L_EVNT SG_ 353 L_ATCU_HU_FrDrEVntCtrOpnCls 0;
BA_ "Version" SG_ 353 L_ATCU_HU_FrDrEVntCtrOpnCls "24.05.11";
BA_ "Description" SG_ 353 L_ATCU_HU_FrPsEVntSideOpnCls "Electric Vent Frt Passenger Side Vent Open/Close Signal";
BA_ "GenSigSendType" SG_ 353 L_ATCU_HU_FrPsEVntSideOpnCls 4;
BA_ "UserSigValidity" SG_ 353 L_ATCU_HU_FrPsEVntSideOpnCls 7;
BA_REL_ "GenSigTimeoutTime" BU_SG_REL_ L_EVNT SG_ 353 L_ATCU_HU_FrPsEVntSideOpnCls 0;
BA_ "Version" SG_ 353 L_ATCU_HU_FrPsEVntSideOpnCls "24.05.11";
BA_ "Description" SG_ 353 L_ATCU_HU_FrPsEVntCtrOpnCls "Electric Vent Frt Passenger Center Vent Open/Close Signal";
BA_ "GenSigSendType" SG_ 353 L_ATCU_HU_FrPsEVntCtrOpnCls 4;
BA_ "UserSigValidity" SG_ 353 L_ATCU_HU_FrPsEVntCtrOpnCls 7;
BA_REL_ "GenSigTimeoutTime" BU_SG_REL_ L_EVNT SG_ 353 L_ATCU_HU_FrPsEVntCtrOpnCls 0;
BA_ "Version" SG_ 353 L_ATCU_HU_FrPsEVntCtrOpnCls "24.05.11";
BA_ "GenSigSendType" SG_ 353 L_ATCU_HU_FrtEvntFocusLvlSet 4;
BA_ "UserSigValidity" SG_ 353 L_ATCU_HU_FrtEvntFocusLvlSet 7;
BA_REL_ "GenSigTimeoutTime" BU_SG_REL_ L_EVNT SG_ 353 L_ATCU_HU_FrtEvntFocusLvlSet 0;
BA_ "Version" SG_ 353 L_ATCU_HU_FrtEvntFocusLvlSet "25.05.04";
BA_ "Description" SG_ 353 L_ATCU_HU_FrPsEVntModeSet "Electric Vent Frt Passenger Mode Signal";
BA_ "GenSigSendType" SG_ 353 L_ATCU_HU_FrPsEVntModeSet 4;
BA_ "UserSigValidity" SG_ 353 L_ATCU_HU_FrPsEVntModeSet 7;
BA_REL_ "GenSigTimeoutTime" BU_SG_REL_ L_EVNT SG_ 353 L_ATCU_HU_FrPsEVntModeSet 0;
BA_ "Version" SG_ 353 L_ATCU_HU_FrPsEVntModeSet "25.04.02";
BA_ "Description" SG_ 353 L_ATCU_HU_FrDrEVntSideOpnCls "Electric Vent Frt Driver Side Vent Open/Close Signal";
BA_ "GenSigSendType" SG_ 353 L_ATCU_HU_FrDrEVntSideOpnCls 4;
BA_ "UserSigValidity" SG_ 353 L_ATCU_HU_FrDrEVntSideOpnCls 7;
BA_REL_ "GenSigTimeoutTime" BU_SG_REL_ L_EVNT SG_ 353 L_ATCU_HU_FrDrEVntSideOpnCls 0;
BA_ "Version" SG_ 353 L_ATCU_HU_FrDrEVntSideOpnCls "24.05.11";
BA_ "GenMsgCycleTime" BO_ 354 0;
BA_ "Description" SG_ 354 L_ATCU_CTS_FrtDrEVntModeSet "Electric Vent Mode_Frt Dr";
BA_ "GenSigSendType" SG_ 354 L_ATCU_CTS_FrtDrEVntModeSet 4;
BA_ "UserSigValidity" SG_ 354 L_ATCU_CTS_FrtDrEVntModeSet 7;
BA_REL_ "GenSigTimeoutTime" BU_SG_REL_ L_EVNT SG_ 354 L_ATCU_CTS_FrtDrEVntModeSet 0;
BA_ "Version" SG_ 354 L_ATCU_CTS_FrtDrEVntModeSet "25.04.02";
BA_ "Description" SG_ 354 L_ATCU_CTS_FrDrEVntCtrOpnCls "Electric Vent FRT Dr Center Vent Open/Close Signal";
BA_ "GenSigSendType" SG_ 354 L_ATCU_CTS_FrDrEVntCtrOpnCls 4;
BA_ "UserSigValidity" SG_ 354 L_ATCU_CTS_FrDrEVntCtrOpnCls 7;
BA_REL_ "GenSigTimeoutTime" BU_SG_REL_ L_EVNT SG_ 354 L_ATCU_CTS_FrDrEVntCtrOpnCls 0;
BA_ "Version" SG_ 354 L_ATCU_CTS_FrDrEVntCtrOpnCls "24.08.00";
BA_ "Description" SG_ 354 L_ATCU_CTS_FrPsEVntSideOpnCls "Electric Vent FRT Ps Side Vent Open/Close Signal";
BA_ "GenSigSendType" SG_ 354 L_ATCU_CTS_FrPsEVntSideOpnCls 4;
BA_ "UserSigValidity" SG_ 354 L_ATCU_CTS_FrPsEVntSideOpnCls 7;
BA_REL_ "GenSigTimeoutTime" BU_SG_REL_ L_EVNT SG_ 354 L_ATCU_CTS_FrPsEVntSideOpnCls 0;
BA_ "Version" SG_ 354 L_ATCU_CTS_FrPsEVntSideOpnCls "24.08.00";
BA_ "Description" SG_ 354 L_ATCU_CTS_FrPsEVntCtrOpnCls "Electric Vent FRT Ps Center Vent Open/Close Signal";
BA_ "GenSigSendType" SG_ 354 L_ATCU_CTS_FrPsEVntCtrOpnCls 4;
BA_ "UserSigValidity" SG_ 354 L_ATCU_CTS_FrPsEVntCtrOpnCls 7;
BA_REL_ "GenSigTimeoutTime" BU_SG_REL_ L_EVNT SG_ 354 L_ATCU_CTS_FrPsEVntCtrOpnCls 0;
BA_ "Version" SG_ 354 L_ATCU_CTS_FrPsEVntCtrOpnCls "24.08.00";
BA_ "GenSigSendType" SG_ 354 L_ATCU_CTS_RrEvntFocusLvlSet 4;
BA_ "UserSigValidity" SG_ 354 L_ATCU_CTS_RrEvntFocusLvlSet 7;
BA_REL_ "GenSigTimeoutTime" BU_SG_REL_ L_EVNT SG_ 354 L_ATCU_CTS_RrEvntFocusLvlSet 0;
BA_ "Version" SG_ 354 L_ATCU_CTS_RrEvntFocusLvlSet "25.05.04";
BA_ "Description" SG_ 354 L_ATCU_CTS_FrtPsEVntModeSet "Electric Vent Mode_Frt Ps";
BA_ "GenSigSendType" SG_ 354 L_ATCU_CTS_FrtPsEVntModeSet 4;
BA_ "UserSigValidity" SG_ 354 L_ATCU_CTS_FrtPsEVntModeSet 7;
BA_REL_ "GenSigTimeoutTime" BU_SG_REL_ L_EVNT SG_ 354 L_ATCU_CTS_FrtPsEVntModeSet 0;
BA_ "Version" SG_ 354 L_ATCU_CTS_FrtPsEVntModeSet "25.04.02";
BA_ "Description" SG_ 354 L_ATCU_CTS_FrDrEVntSideOpnCls "Electric Vent FRT Dr Side Vent Open/Close Signal";
BA_ "GenSigSendType" SG_ 354 L_ATCU_CTS_FrDrEVntSideOpnCls 4;
BA_ "UserSigValidity" SG_ 354 L_ATCU_CTS_FrDrEVntSideOpnCls 7;
BA_REL_ "GenSigTimeoutTime" BU_SG_REL_ L_EVNT SG_ 354 L_ATCU_CTS_FrDrEVntSideOpnCls 0;
BA_ "Version" SG_ 354 L_ATCU_CTS_FrDrEVntSideOpnCls "24.08.00";
BA_ "GenMsgSendType" BO_ 856 0;
BA_ "GenMsgCycleTime" BO_ 856 500;
BA_ "Description" SG_ 856 L_ATCU_Lib_AutoStepInd "This value only use for ATCU Library data monitoring (Only use before SOP)";
BA_ "GenSigSendType" SG_ 856 L_ATCU_Lib_AutoStepInd 4;
BA_ "UserSigValidity" SG_ 856 L_ATCU_Lib_AutoStepInd 0;
BA_REL_ "GenSigTimeoutTime" BU_SG_REL_ L_ATCU_vMON SG_ 856 L_ATCU_Lib_AutoStepInd 5000;
BA_ "Version" SG_ 856 L_ATCU_Lib_AutoStepInd "23.11.10";
BA_ "Description" SG_ 856 L_ATCU_Lib_BlrSym "This value only use for ATCU Library data monitoring (Only use before SOP)";
BA_ "GenSigSendType" SG_ 856 L_ATCU_Lib_BlrSym 4;
BA_ "UserSigValidity" SG_ 856 L_ATCU_Lib_BlrSym 0;
BA_REL_ "GenSigTimeoutTime" BU_SG_REL_ L_ATCU_vMON SG_ 856 L_ATCU_Lib_BlrSym 5000;
BA_ "Version" SG_ 856 L_ATCU_Lib_BlrSym "23.11.10";
BA_ "Description" SG_ 856 L_ATCU_Lib_BlrStepSym "This value only use for ATCU Library data monitoring (Only use before SOP)";
BA_ "GenSigSendType" SG_ 856 L_ATCU_Lib_BlrStepSym 4;
BA_ "UserSigValidity" SG_ 856 L_ATCU_Lib_BlrStepSym 0;
BA_REL_ "GenSigTimeoutTime" BU_SG_REL_ L_ATCU_vMON SG_ 856 L_ATCU_Lib_BlrStepSym 5000;
BA_ "Version" SG_ 856 L_ATCU_Lib_BlrStepSym "23.11.10";
BA_ "Description" SG_ 856 L_ATCU_Lib_IntakeRECInd "This value only use for ATCU Library data monitoring (Only use before SOP)";
BA_ "GenSigSendType" SG_ 856 L_ATCU_Lib_IntakeRECInd 4;
BA_ "UserSigValidity" SG_ 856 L_ATCU_Lib_IntakeRECInd 0;
BA_REL_ "GenSigTimeoutTime" BU_SG_REL_ L_ATCU_vMON SG_ 856 L_ATCU_Lib_IntakeRECInd 5000;
BA_ "Version" SG_ 856 L_ATCU_Lib_IntakeRECInd "23.11.10";
BA_ "Description" SG_ 856 L_ATCU_Lib_IntakeFREInd "This value only use for ATCU Library data monitoring (Only use before SOP)";
BA_ "GenSigSendType" SG_ 856 L_ATCU_Lib_IntakeFREInd 4;
BA_ "UserSigValidity" SG_ 856 L_ATCU_Lib_IntakeFREInd 0;
BA_REL_ "GenSigTimeoutTime" BU_SG_REL_ L_ATCU_vMON SG_ 856 L_ATCU_Lib_IntakeFREInd 5000;
BA_ "Version" SG_ 856 L_ATCU_Lib_IntakeFREInd "23.11.10";
BA_ "Description" SG_ 856 L_ATCU_Lib_ACInd "This value only use for ATCU Library data monitoring (Only use before SOP)";
BA_ "GenSigSendType" SG_ 856 L_ATCU_Lib_ACInd 4;
BA_ "UserSigValidity" SG_ 856 L_ATCU_Lib_ACInd 0;
BA_REL_ "GenSigTimeoutTime" BU_SG_REL_ L_ATCU_vMON SG_ 856 L_ATCU_Lib_ACInd 5000;
BA_ "Version" SG_ 856 L_ATCU_Lib_ACInd "23.11.10";
BA_ "Description" SG_ 856 L_ATCU_Lib_DEFInd "This value only use for ATCU Library data monitoring (Only use before SOP)";
BA_ "GenSigSendType" SG_ 856 L_ATCU_Lib_DEFInd 4;
BA_ "UserSigValidity" SG_ 856 L_ATCU_Lib_DEFInd 0;
BA_REL_ "GenSigTimeoutTime" BU_SG_REL_ L_ATCU_vMON SG_ 856 L_ATCU_Lib_DEFInd 5000;
BA_ "Version" SG_ 856 L_ATCU_Lib_DEFInd "23.11.10";
BA_ "Description" SG_ 856 L_ATCU_Lib_SyncInd "This value only use for ATCU Library data monitoring (Only use before SOP)";
BA_ "GenSigSendType" SG_ 856 L_ATCU_Lib_SyncInd 4;
BA_ "UserSigValidity" SG_ 856 L_ATCU_Lib_SyncInd 0;
BA_REL_ "GenSigTimeoutTime" BU_SG_REL_ L_ATCU_vMON SG_ 856 L_ATCU_Lib_SyncInd 5000;
BA_ "Version" SG_ 856 L_ATCU_Lib_SyncInd "23.11.10";
BA_ "Description" SG_ 856 L_ATCU_Lib_AutoBlrStepSym "This value only use for ATCU Library data monitoring (Only use before SOP)";
BA_ "GenSigSendType" SG_ 856 L_ATCU_Lib_AutoBlrStepSym 4;
BA_ "UserSigValidity" SG_ 856 L_ATCU_Lib_AutoBlrStepSym 0;
BA_REL_ "GenSigTimeoutTime" BU_SG_REL_ L_ATCU_vMON SG_ 856 L_ATCU_Lib_AutoBlrStepSym 5000;
BA_ "Version" SG_ 856 L_ATCU_Lib_AutoBlrStepSym "23.11.10";
BA_ "Description" SG_ 856 L_ATCU_Lib_DrvOnly "This value only use for ATCU Library data monitoring (Only use before SOP)";
BA_ "GenSigSendType" SG_ 856 L_ATCU_Lib_DrvOnly 4;
BA_ "UserSigValidity" SG_ 856 L_ATCU_Lib_DrvOnly 0;
BA_REL_ "GenSigTimeoutTime" BU_SG_REL_ L_ATCU_vMON SG_ 856 L_ATCU_Lib_DrvOnly 5000;
BA_ "Version" SG_ 856 L_ATCU_Lib_DrvOnly "23.11.10";
BA_ "Description" SG_ 856 L_ATCU_Lib_ADSSym "This value only use for ATCU Library data monitoring (Only use before SOP)";
BA_ "GenSigSendType" SG_ 856 L_ATCU_Lib_ADSSym 4;
BA_ "UserSigValidity" SG_ 856 L_ATCU_Lib_ADSSym 0;
BA_REL_ "GenSigTimeoutTime" BU_SG_REL_ L_ATCU_vMON SG_ 856 L_ATCU_Lib_ADSSym 5000;
BA_ "Version" SG_ 856 L_ATCU_Lib_ADSSym "23.11.10";
BA_ "Description" SG_ 856 L_ATCU_Lib_ModVentInd "This value only use for ATCU Library data monitoring (Only use before SOP)";
BA_ "GenSigSendType" SG_ 856 L_ATCU_Lib_ModVentInd 4;
BA_ "UserSigValidity" SG_ 856 L_ATCU_Lib_ModVentInd 0;
BA_REL_ "GenSigTimeoutTime" BU_SG_REL_ L_ATCU_vMON SG_ 856 L_ATCU_Lib_ModVentInd 5000;
BA_ "Version" SG_ 856 L_ATCU_Lib_ModVentInd "23.11.10";
BA_ "Description" SG_ 856 L_ATCU_Lib_DrvTempSym "This value only use for ATCU Library data monitoring (Only use before SOP)";
BA_ "GenSigSendType" SG_ 856 L_ATCU_Lib_DrvTempSym 4;
BA_ "UserSigValidity" SG_ 856 L_ATCU_Lib_DrvTempSym 0;
BA_REL_ "GenSigTimeoutTime" BU_SG_REL_ L_ATCU_vMON SG_ 856 L_ATCU_Lib_DrvTempSym 5000;
BA_ "Version" SG_ 856 L_ATCU_Lib_DrvTempSym "23.11.10";
BA_ "Description" SG_ 856 L_ATCU_Lib_ModSym "This value only use for ATCU Library data monitoring (Only use before SOP)";
BA_ "GenSigSendType" SG_ 856 L_ATCU_Lib_ModSym 4;
BA_ "UserSigValidity" SG_ 856 L_ATCU_Lib_ModSym 0;
BA_REL_ "GenSigTimeoutTime" BU_SG_REL_ L_ATCU_vMON SG_ 856 L_ATCU_Lib_ModSym 5000;
BA_ "Version" SG_ 856 L_ATCU_Lib_ModSym "23.11.10";
BA_ "Description" SG_ 856 L_ATCU_Lib_AstTempSym "This value only use for ATCU Library data monitoring (Only use before SOP)";
BA_ "GenSigSendType" SG_ 856 L_ATCU_Lib_AstTempSym 4;
BA_ "UserSigValidity" SG_ 856 L_ATCU_Lib_AstTempSym 0;
BA_REL_ "GenSigTimeoutTime" BU_SG_REL_ L_ATCU_vMON SG_ 856 L_ATCU_Lib_AstTempSym 5000;
BA_ "Version" SG_ 856 L_ATCU_Lib_AstTempSym "23.11.10";
BA_ "Description" SG_ 856 L_ATCU_Lib_DrvTempUnitSym "This value only use for ATCU Library data monitoring (Only use before SOP)";
BA_ "GenSigSendType" SG_ 856 L_ATCU_Lib_DrvTempUnitSym 4;
BA_ "UserSigValidity" SG_ 856 L_ATCU_Lib_DrvTempUnitSym 0;
BA_REL_ "GenSigTimeoutTime" BU_SG_REL_ L_ATCU_vMON SG_ 856 L_ATCU_Lib_DrvTempUnitSym 5000;
BA_ "Version" SG_ 856 L_ATCU_Lib_DrvTempUnitSym "23.11.10";
BA_ "Description" SG_ 856 L_ATCU_Lib_ModFloorInd "This value only use for ATCU Library data monitoring (Only use before SOP)";
BA_ "GenSigSendType" SG_ 856 L_ATCU_Lib_ModFloorInd 4;
BA_ "UserSigValidity" SG_ 856 L_ATCU_Lib_ModFloorInd 0;
BA_REL_ "GenSigTimeoutTime" BU_SG_REL_ L_ATCU_vMON SG_ 856 L_ATCU_Lib_ModFloorInd 5000;
BA_ "Version" SG_ 856 L_ATCU_Lib_ModFloorInd "23.11.10";
BA_ "Description" SG_ 856 L_ATCU_Lib_ModDEFInd "This value only use for ATCU Library data monitoring (Only use before SOP)";
BA_ "GenSigSendType" SG_ 856 L_ATCU_Lib_ModDEFInd 4;
BA_ "UserSigValidity" SG_ 856 L_ATCU_Lib_ModDEFInd 0;
BA_REL_ "GenSigTimeoutTime" BU_SG_REL_ L_ATCU_vMON SG_ 856 L_ATCU_Lib_ModDEFInd 5000;
BA_ "Version" SG_ 856 L_ATCU_Lib_ModDEFInd "23.11.10";
BA_ "GenMsgSendType" BO_ 857 0;
BA_ "GenMsgCycleTime" BO_ 857 500;
BA_ "Description" SG_ 857 L_ATCU_Lib_2LHAutoStepInd "This value only use for ATCU Library data monitoring (Only use before SOP)";
BA_ "GenSigSendType" SG_ 857 L_ATCU_Lib_2LHAutoStepInd 4;
BA_ "UserSigValidity" SG_ 857 L_ATCU_Lib_2LHAutoStepInd 0;
BA_REL_ "GenSigTimeoutTime" BU_SG_REL_ L_ATCU_vMON SG_ 857 L_ATCU_Lib_2LHAutoStepInd 5000;
BA_ "Version" SG_ 857 L_ATCU_Lib_2LHAutoStepInd "23.11.10";
BA_ "Description" SG_ 857 L_ATCU_Lib_2ndACInd "This value only use for ATCU Library data monitoring (Only use before SOP)";
BA_ "GenSigSendType" SG_ 857 L_ATCU_Lib_2ndACInd 4;
BA_ "UserSigValidity" SG_ 857 L_ATCU_Lib_2ndACInd 0;
BA_REL_ "GenSigTimeoutTime" BU_SG_REL_ L_ATCU_vMON SG_ 857 L_ATCU_Lib_2ndACInd 5000;
BA_ "Version" SG_ 857 L_ATCU_Lib_2ndACInd "23.11.10";
BA_ "Description" SG_ 857 L_ATCU_Lib_2ndSyncInd "This value only use for ATCU Library data monitoring (Only use before SOP)";
BA_ "GenSigSendType" SG_ 857 L_ATCU_Lib_2ndSyncInd 4;
BA_ "UserSigValidity" SG_ 857 L_ATCU_Lib_2ndSyncInd 0;
BA_REL_ "GenSigTimeoutTime" BU_SG_REL_ L_ATCU_vMON SG_ 857 L_ATCU_Lib_2ndSyncInd 5000;
BA_ "Version" SG_ 857 L_ATCU_Lib_2ndSyncInd "23.11.10";
BA_ "Description" SG_ 857 L_ATCU_Lib_2ndLockInd "This value only use for ATCU Library data monitoring (Only use before SOP)";
BA_ "GenSigSendType" SG_ 857 L_ATCU_Lib_2ndLockInd 4;
BA_ "UserSigValidity" SG_ 857 L_ATCU_Lib_2ndLockInd 0;
BA_REL_ "GenSigTimeoutTime" BU_SG_REL_ L_ATCU_vMON SG_ 857 L_ATCU_Lib_2ndLockInd 5000;
BA_ "Version" SG_ 857 L_ATCU_Lib_2ndLockInd "23.11.10";
BA_ "Description" SG_ 857 L_ATCU_Lib_2LHBlrSym "This value only use for ATCU Library data monitoring (Only use before SOP)";
BA_ "GenSigSendType" SG_ 857 L_ATCU_Lib_2LHBlrSym 4;
BA_ "UserSigValidity" SG_ 857 L_ATCU_Lib_2LHBlrSym 0;
BA_REL_ "GenSigTimeoutTime" BU_SG_REL_ L_ATCU_vMON SG_ 857 L_ATCU_Lib_2LHBlrSym 5000;
BA_ "Version" SG_ 857 L_ATCU_Lib_2LHBlrSym "23.11.10";
BA_ "Description" SG_ 857 L_ATCU_Lib_2LHTempSym "This value only use for ATCU Library data monitoring (Only use before SOP)";
BA_ "GenSigSendType" SG_ 857 L_ATCU_Lib_2LHTempSym 4;
BA_ "UserSigValidity" SG_ 857 L_ATCU_Lib_2LHTempSym 0;
BA_REL_ "GenSigTimeoutTime" BU_SG_REL_ L_ATCU_vMON SG_ 857 L_ATCU_Lib_2LHTempSym 5000;
BA_ "Version" SG_ 857 L_ATCU_Lib_2LHTempSym "23.11.10";
BA_ "Description" SG_ 857 L_ATCU_Lib_2LHAutoBlrStepSym "This value only use for ATCU Library data monitoring (Only use before SOP)";
BA_ "GenSigSendType" SG_ 857 L_ATCU_Lib_2LHAutoBlrStepSym 4;
BA_ "UserSigValidity" SG_ 857 L_ATCU_Lib_2LHAutoBlrStepSym 0;
BA_REL_ "GenSigTimeoutTime" BU_SG_REL_ L_ATCU_vMON SG_ 857 L_ATCU_Lib_2LHAutoBlrStepSym 5000;
BA_ "Version" SG_ 857 L_ATCU_Lib_2LHAutoBlrStepSym "23.11.10";
BA_ "Description" SG_ 857 L_ATCU_Lib_2LHTempUnit "This value only use for ATCU Library data monitoring (Only use before SOP)";
BA_ "GenSigSendType" SG_ 857 L_ATCU_Lib_2LHTempUnit 4;
BA_ "UserSigValidity" SG_ 857 L_ATCU_Lib_2LHTempUnit 0;
BA_REL_ "GenSigTimeoutTime" BU_SG_REL_ L_ATCU_vMON SG_ 857 L_ATCU_Lib_2LHTempUnit 5000;
BA_ "Version" SG_ 857 L_ATCU_Lib_2LHTempUnit "23.11.10";
BA_ "Description" SG_ 857 L_ATCU_Lib_2LHModSym "This value only use for ATCU Library data monitoring (Only use before SOP)";
BA_ "GenSigSendType" SG_ 857 L_ATCU_Lib_2LHModSym 4;
BA_ "UserSigValidity" SG_ 857 L_ATCU_Lib_2LHModSym 0;
BA_REL_ "GenSigTimeoutTime" BU_SG_REL_ L_ATCU_vMON SG_ 857 L_ATCU_Lib_2LHModSym 5000;
BA_ "Version" SG_ 857 L_ATCU_Lib_2LHModSym "23.11.10";
BA_ "Description" SG_ 857 L_ATCU_Lib_FineDustTreeSym "This value only use for ATCU Library data monitoring (Only use before SOP)";
BA_ "GenSigSendType" SG_ 857 L_ATCU_Lib_FineDustTreeSym 4;
BA_ "UserSigValidity" SG_ 857 L_ATCU_Lib_FineDustTreeSym 0;
BA_REL_ "GenSigTimeoutTime" BU_SG_REL_ L_ATCU_vMON SG_ 857 L_ATCU_Lib_FineDustTreeSym 5000;
BA_ "Version" SG_ 857 L_ATCU_Lib_FineDustTreeSym "24.01.09";
BA_ "Description" SG_ 857 L_ATCU_Lib_FineDustTreeColor "This value only use for ATCU Library data monitoring (Only use before SOP)";
BA_ "GenSigSendType" SG_ 857 L_ATCU_Lib_FineDustTreeColor 4;
BA_ "UserSigValidity" SG_ 857 L_ATCU_Lib_FineDustTreeColor 0;
BA_REL_ "GenSigTimeoutTime" BU_SG_REL_ L_ATCU_vMON SG_ 857 L_ATCU_Lib_FineDustTreeColor 5000;
BA_ "Version" SG_ 857 L_ATCU_Lib_FineDustTreeColor "24.01.09";
BA_ "Description" SG_ 857 L_ATCU_Lib_FineDustBarStepSym "This value only use for ATCU Library data monitoring (Only use before SOP)";
BA_ "GenSigSendType" SG_ 857 L_ATCU_Lib_FineDustBarStepSym 4;
BA_ "UserSigValidity" SG_ 857 L_ATCU_Lib_FineDustBarStepSym 0;
BA_REL_ "GenSigTimeoutTime" BU_SG_REL_ L_ATCU_vMON SG_ 857 L_ATCU_Lib_FineDustBarStepSym 5000;
BA_ "Version" SG_ 857 L_ATCU_Lib_FineDustBarStepSym "24.01.08";
BA_ "Description" SG_ 857 L_ATCU_Lib_2LHBlrStepSym "This value only use for ATCU Library data monitoring (Only use before SOP)";
BA_ "GenSigSendType" SG_ 857 L_ATCU_Lib_2LHBlrStepSym 4;
BA_ "UserSigValidity" SG_ 857 L_ATCU_Lib_2LHBlrStepSym 0;
BA_REL_ "GenSigTimeoutTime" BU_SG_REL_ L_ATCU_vMON SG_ 857 L_ATCU_Lib_2LHBlrStepSym 5000;
BA_ "Version" SG_ 857 L_ATCU_Lib_2LHBlrStepSym "23.11.10";
BA_ "GenMsgSendType" BO_ 858 0;
BA_ "GenMsgCycleTime" BO_ 858 500;
BA_ "Description" SG_ 858 L_ATCU_Lib_USMDEFState "This value only use for ATCU Library data monitoring (Only use before SOP)";
BA_ "GenSigSendType" SG_ 858 L_ATCU_Lib_USMDEFState 4;
BA_ "UserSigValidity" SG_ 858 L_ATCU_Lib_USMDEFState 0;
BA_REL_ "GenSigTimeoutTime" BU_SG_REL_ L_ATCU_vMON SG_ 858 L_ATCU_Lib_USMDEFState 5000;
BA_ "Version" SG_ 858 L_ATCU_Lib_USMDEFState "24.09.00";
BA_ "Description" SG_ 858 L_ATCU_Lib_USMSmrtVentState "This value only use for ATCU Library data monitoring (Only use before SOP)";
BA_ "GenSigSendType" SG_ 858 L_ATCU_Lib_USMSmrtVentState 4;
BA_ "UserSigValidity" SG_ 858 L_ATCU_Lib_USMSmrtVentState 0;
BA_REL_ "GenSigTimeoutTime" BU_SG_REL_ L_ATCU_vMON SG_ 858 L_ATCU_Lib_USMSmrtVentState 5000;
BA_ "Version" SG_ 858 L_ATCU_Lib_USMSmrtVentState "23.11.10";
BA_ "Description" SG_ 858 L_ATCU_Lib_USMCoolHeatSeat "This value only use for ATCU Library data monitoring (Only use before SOP)";
BA_ "GenSigSendType" SG_ 858 L_ATCU_Lib_USMCoolHeatSeat 4;
BA_ "UserSigValidity" SG_ 858 L_ATCU_Lib_USMCoolHeatSeat 0;
BA_REL_ "GenSigTimeoutTime" BU_SG_REL_ L_ATCU_vMON SG_ 858 L_ATCU_Lib_USMCoolHeatSeat 5000;
BA_ "Version" SG_ 858 L_ATCU_Lib_USMCoolHeatSeat "23.11.10";
BA_ "Description" SG_ 858 L_ATCU_Lib_USMStrWhlHeater "This value only use for ATCU Library data monitoring (Only use before SOP)";
BA_ "GenSigSendType" SG_ 858 L_ATCU_Lib_USMStrWhlHeater 4;
BA_ "UserSigValidity" SG_ 858 L_ATCU_Lib_USMStrWhlHeater 0;
BA_REL_ "GenSigTimeoutTime" BU_SG_REL_ L_ATCU_vMON SG_ 858 L_ATCU_Lib_USMStrWhlHeater 5000;
BA_ "Version" SG_ 858 L_ATCU_Lib_USMStrWhlHeater "23.11.10";
BA_ "Description" SG_ 858 L_ATCU_Lib_USMUsrPrfleState "This value only use for ATCU Library data monitoring (Only use before SOP)";
BA_ "GenSigSendType" SG_ 858 L_ATCU_Lib_USMUsrPrfleState 4;
BA_ "UserSigValidity" SG_ 858 L_ATCU_Lib_USMUsrPrfleState 0;
BA_REL_ "GenSigTimeoutTime" BU_SG_REL_ L_ATCU_vMON SG_ 858 L_ATCU_Lib_USMUsrPrfleState 5000;
BA_ "Version" SG_ 858 L_ATCU_Lib_USMUsrPrfleState "23.11.10";
BA_ "Description" SG_ 858 L_ATCU_Lib_USMAutoFreshState "This value only use for ATCU Library data monitoring (Only use before SOP)";
BA_ "GenSigSendType" SG_ 858 L_ATCU_Lib_USMAutoFreshState 4;
BA_ "UserSigValidity" SG_ 858 L_ATCU_Lib_USMAutoFreshState 0;
BA_REL_ "GenSigTimeoutTime" BU_SG_REL_ L_ATCU_vMON SG_ 858 L_ATCU_Lib_USMAutoFreshState 5000;
BA_ "Version" SG_ 858 L_ATCU_Lib_USMAutoFreshState "24.09.00";
BA_ "Description" SG_ 858 L_ATCU_Lib_USM2ndAutoOffState "This value only use for ATCU Library data monitoring (Only use before SOP)";
BA_ "GenSigSendType" SG_ 858 L_ATCU_Lib_USM2ndAutoOffState 4;
BA_ "UserSigValidity" SG_ 858 L_ATCU_Lib_USM2ndAutoOffState 0;
BA_REL_ "GenSigTimeoutTime" BU_SG_REL_ L_ATCU_vMON SG_ 858 L_ATCU_Lib_USM2ndAutoOffState 5000;
BA_ "Version" SG_ 858 L_ATCU_Lib_USM2ndAutoOffState "23.11.10";
BA_ "Description" SG_ 858 L_ATCU_Lib_USMRearLock "This value only use for ATCU Library data monitoring (Only use before SOP)";
BA_ "GenSigSendType" SG_ 858 L_ATCU_Lib_USMRearLock 4;
BA_ "UserSigValidity" SG_ 858 L_ATCU_Lib_USMRearLock 0;
BA_REL_ "GenSigTimeoutTime" BU_SG_REL_ L_ATCU_vMON SG_ 858 L_ATCU_Lib_USMRearLock 5000;
BA_ "Version" SG_ 858 L_ATCU_Lib_USMRearLock "23.11.10";
BA_ "Description" SG_ 858 L_ATCU_Lib_USMWshState "This value only use for ATCU Library data monitoring (Only use before SOP)";
BA_ "GenSigSendType" SG_ 858 L_ATCU_Lib_USMWshState 4;
BA_ "UserSigValidity" SG_ 858 L_ATCU_Lib_USMWshState 0;
BA_REL_ "GenSigTimeoutTime" BU_SG_REL_ L_ATCU_vMON SG_ 858 L_ATCU_Lib_USMWshState 5000;
BA_ "Version" SG_ 858 L_ATCU_Lib_USMWshState "24.09.00";
BA_ "Description" SG_ 858 L_ATCU_Lib_USMADSState "This value only use for ATCU Library data monitoring (Only use before SOP)";
BA_ "GenSigSendType" SG_ 858 L_ATCU_Lib_USMADSState 4;
BA_ "UserSigValidity" SG_ 858 L_ATCU_Lib_USMADSState 0;
BA_REL_ "GenSigTimeoutTime" BU_SG_REL_ L_ATCU_vMON SG_ 858 L_ATCU_Lib_USMADSState 5000;
BA_ "Version" SG_ 858 L_ATCU_Lib_USMADSState "24.09.00";
BA_ "Description" SG_ 858 L_ATCU_Lib_USMTempUnitState "This value only use for ATCU Library data monitoring (Only use before SOP)";
BA_ "GenSigSendType" SG_ 858 L_ATCU_Lib_USMTempUnitState 4;
BA_ "UserSigValidity" SG_ 858 L_ATCU_Lib_USMTempUnitState 0;
BA_REL_ "GenSigTimeoutTime" BU_SG_REL_ L_ATCU_vMON SG_ 858 L_ATCU_Lib_USMTempUnitState 5000;
BA_ "Version" SG_ 858 L_ATCU_Lib_USMTempUnitState "23.11.10";
BA_ "Description" SG_ 858 L_ATCU_Lib_USMAfterBlowState "This value only use for ATCU Library data monitoring (Only use before SOP)";
BA_ "GenSigSendType" SG_ 858 L_ATCU_Lib_USMAfterBlowState 4;
BA_ "UserSigValidity" SG_ 858 L_ATCU_Lib_USMAfterBlowState 0;
BA_REL_ "GenSigTimeoutTime" BU_SG_REL_ L_ATCU_vMON SG_ 858 L_ATCU_Lib_USMAfterBlowState 5000;
BA_ "Version" SG_ 858 L_ATCU_Lib_USMAfterBlowState "23.11.10";
BA_ "Description" SG_ 858 L_ATCU_Lib_USMSchdldVent "This value only use for ATCU Library data monitoring (Only use before SOP)";
BA_ "GenSigSendType" SG_ 858 L_ATCU_Lib_USMSchdldVent 4;
BA_ "UserSigValidity" SG_ 858 L_ATCU_Lib_USMSchdldVent 0;
BA_REL_ "GenSigTimeoutTime" BU_SG_REL_ L_ATCU_vMON SG_ 858 L_ATCU_Lib_USMSchdldVent 5000;
BA_ "Version" SG_ 858 L_ATCU_Lib_USMSchdldVent "23.11.10";
BA_ "GenMsgSendType" BO_ 859 0;
BA_ "GenMsgCycleTime" BO_ 859 500;
BA_ "Description" SG_ 859 L_ATCU_Lib_Opt2LHModSwTyp "This value only use for ATCU Library data monitoring (Only use before SOP)";
BA_ "GenSigSendType" SG_ 859 L_ATCU_Lib_Opt2LHModSwTyp 4;
BA_ "UserSigValidity" SG_ 859 L_ATCU_Lib_Opt2LHModSwTyp 0;
BA_REL_ "GenSigTimeoutTime" BU_SG_REL_ L_ATCU_vMON SG_ 859 L_ATCU_Lib_Opt2LHModSwTyp 5000;
BA_ "Version" SG_ 859 L_ATCU_Lib_Opt2LHModSwTyp "23.11.10";
BA_ "Description" SG_ 859 L_ATCU_Lib_Opt2ndModBtn "This value only use for ATCU Library data monitoring (Only use before SOP)";
BA_ "GenSigSendType" SG_ 859 L_ATCU_Lib_Opt2ndModBtn 4;
BA_ "UserSigValidity" SG_ 859 L_ATCU_Lib_Opt2ndModBtn 0;
BA_REL_ "GenSigTimeoutTime" BU_SG_REL_ L_ATCU_vMON SG_ 859 L_ATCU_Lib_Opt2ndModBtn 5000;
BA_ "Version" SG_ 859 L_ATCU_Lib_Opt2ndModBtn "23.11.10";
BA_ "Description" SG_ 859 L_ATCU_Lib_Opt2ndOffSwTyp "This value only use for ATCU Library data monitoring (Only use before SOP)";
BA_ "GenSigSendType" SG_ 859 L_ATCU_Lib_Opt2ndOffSwTyp 4;
BA_ "UserSigValidity" SG_ 859 L_ATCU_Lib_Opt2ndOffSwTyp 0;
BA_REL_ "GenSigTimeoutTime" BU_SG_REL_ L_ATCU_vMON SG_ 859 L_ATCU_Lib_Opt2ndOffSwTyp 5000;
BA_ "Version" SG_ 859 L_ATCU_Lib_Opt2ndOffSwTyp "23.11.10";
BA_ "Description" SG_ 859 L_ATCU_Lib_Opt2ndTmpBtn "This value only use for ATCU Library data monitoring (Only use before SOP)";
BA_ "GenSigSendType" SG_ 859 L_ATCU_Lib_Opt2ndTmpBtn 4;
BA_ "UserSigValidity" SG_ 859 L_ATCU_Lib_Opt2ndTmpBtn 0;
BA_REL_ "GenSigTimeoutTime" BU_SG_REL_ L_ATCU_vMON SG_ 859 L_ATCU_Lib_Opt2ndTmpBtn 5000;
BA_ "Version" SG_ 859 L_ATCU_Lib_Opt2ndTmpBtn "23.11.10";
BA_ "Description" SG_ 859 L_ATCU_Lib_OptADS "This value only use for ATCU Library data monitoring (Only use before SOP)";
BA_ "GenSigSendType" SG_ 859 L_ATCU_Lib_OptADS 4;
BA_ "UserSigValidity" SG_ 859 L_ATCU_Lib_OptADS 0;
BA_REL_ "GenSigTimeoutTime" BU_SG_REL_ L_ATCU_vMON SG_ 859 L_ATCU_Lib_OptADS 5000;
BA_ "Version" SG_ 859 L_ATCU_Lib_OptADS "23.11.10";
BA_ "Description" SG_ 859 L_ATCU_Lib_OptAfterBlow "This value only use for ATCU Library data monitoring (Only use before SOP)";
BA_ "GenSigSendType" SG_ 859 L_ATCU_Lib_OptAfterBlow 4;
BA_ "UserSigValidity" SG_ 859 L_ATCU_Lib_OptAfterBlow 0;
BA_REL_ "GenSigTimeoutTime" BU_SG_REL_ L_ATCU_vMON SG_ 859 L_ATCU_Lib_OptAfterBlow 5000;
BA_ "Version" SG_ 859 L_ATCU_Lib_OptAfterBlow "23.11.10";
BA_ "Description" SG_ 859 L_ATCU_Lib_OptAutoStep "This value only use for ATCU Library data monitoring (Only use before SOP)";
BA_ "GenSigSendType" SG_ 859 L_ATCU_Lib_OptAutoStep 4;
BA_ "UserSigValidity" SG_ 859 L_ATCU_Lib_OptAutoStep 0;
BA_REL_ "GenSigTimeoutTime" BU_SG_REL_ L_ATCU_vMON SG_ 859 L_ATCU_Lib_OptAutoStep 5000;
BA_ "Version" SG_ 859 L_ATCU_Lib_OptAutoStep "23.11.10";
BA_ "Description" SG_ 859 L_ATCU_Lib_Opt2ndAutoBtn "This value only use for ATCU Library data monitoring (Only use before SOP)";
BA_ "GenSigSendType" SG_ 859 L_ATCU_Lib_Opt2ndAutoBtn 4;
BA_ "UserSigValidity" SG_ 859 L_ATCU_Lib_Opt2ndAutoBtn 0;
BA_REL_ "GenSigTimeoutTime" BU_SG_REL_ L_ATCU_vMON SG_ 859 L_ATCU_Lib_Opt2ndAutoBtn 5000;
BA_ "Version" SG_ 859 L_ATCU_Lib_Opt2ndAutoBtn "23.11.10";
BA_ "Description" SG_ 859 L_ATCU_Lib_OptAutoSwTyp "This value only use for ATCU Library data monitoring (Only use before SOP)";
BA_ "GenSigSendType" SG_ 859 L_ATCU_Lib_OptAutoSwTyp 4;
BA_ "UserSigValidity" SG_ 859 L_ATCU_Lib_OptAutoSwTyp 0;
BA_REL_ "GenSigTimeoutTime" BU_SG_REL_ L_ATCU_vMON SG_ 859 L_ATCU_Lib_OptAutoSwTyp 5000;
BA_ "Version" SG_ 859 L_ATCU_Lib_OptAutoSwTyp "23.11.10";
BA_ "Description" SG_ 859 L_ATCU_Lib_OptBATCoolingTyp "This value only use for ATCU Library data monitoring (Only use before SOP)";
BA_ "GenSigSendType" SG_ 859 L_ATCU_Lib_OptBATCoolingTyp 4;
BA_ "UserSigValidity" SG_ 859 L_ATCU_Lib_OptBATCoolingTyp 0;
BA_REL_ "GenSigTimeoutTime" BU_SG_REL_ L_ATCU_vMON SG_ 859 L_ATCU_Lib_OptBATCoolingTyp 5000;
BA_ "Version" SG_ 859 L_ATCU_Lib_OptBATCoolingTyp "23.11.10";
BA_ "Description" SG_ 859 L_ATCU_Lib_OptBlrSwKnob "This value only use for ATCU Library data monitoring (Only use before SOP)";
BA_ "GenSigSendType" SG_ 859 L_ATCU_Lib_OptBlrSwKnob 4;
BA_ "UserSigValidity" SG_ 859 L_ATCU_Lib_OptBlrSwKnob 0;
BA_REL_ "GenSigTimeoutTime" BU_SG_REL_ L_ATCU_vMON SG_ 859 L_ATCU_Lib_OptBlrSwKnob 5000;
BA_ "Version" SG_ 859 L_ATCU_Lib_OptBlrSwKnob "23.11.10";
BA_ "Description" SG_ 859 L_ATCU_Lib_OptComp "This value only use for ATCU Library data monitoring (Only use before SOP)";
BA_ "GenSigSendType" SG_ 859 L_ATCU_Lib_OptComp 4;
BA_ "UserSigValidity" SG_ 859 L_ATCU_Lib_OptComp 0;
BA_REL_ "GenSigTimeoutTime" BU_SG_REL_ L_ATCU_vMON SG_ 859 L_ATCU_Lib_OptComp 5000;
BA_ "Version" SG_ 859 L_ATCU_Lib_OptComp "23.11.10";
BA_ "Description" SG_ 859 L_ATCU_Lib_OptDrvHndSide "This value only use for ATCU Library data monitoring (Only use before SOP)";
BA_ "GenSigSendType" SG_ 859 L_ATCU_Lib_OptDrvHndSide 4;
BA_ "UserSigValidity" SG_ 859 L_ATCU_Lib_OptDrvHndSide 0;
BA_REL_ "GenSigTimeoutTime" BU_SG_REL_ L_ATCU_vMON SG_ 859 L_ATCU_Lib_OptDrvHndSide 5000;
BA_ "Version" SG_ 859 L_ATCU_Lib_OptDrvHndSide "23.11.10";
BA_ "Description" SG_ 859 L_ATCU_Lib_OptDrvOnly "This value only use for ATCU Library data monitoring (Only use before SOP)";
BA_ "GenSigSendType" SG_ 859 L_ATCU_Lib_OptDrvOnly 4;
BA_ "UserSigValidity" SG_ 859 L_ATCU_Lib_OptDrvOnly 0;
BA_REL_ "GenSigTimeoutTime" BU_SG_REL_ L_ATCU_vMON SG_ 859 L_ATCU_Lib_OptDrvOnly 5000;
BA_ "Version" SG_ 859 L_ATCU_Lib_OptDrvOnly "23.11.10";
BA_ "Description" SG_ 859 L_ATCU_Lib_OptFineDust "This value only use for ATCU Library data monitoring (Only use before SOP)";
BA_ "GenSigSendType" SG_ 859 L_ATCU_Lib_OptFineDust 4;
BA_ "UserSigValidity" SG_ 859 L_ATCU_Lib_OptFineDust 0;
BA_REL_ "GenSigTimeoutTime" BU_SG_REL_ L_ATCU_vMON SG_ 859 L_ATCU_Lib_OptFineDust 5000;
BA_ "Version" SG_ 859 L_ATCU_Lib_OptFineDust "23.11.10";
BA_ "Description" SG_ 859 L_ATCU_Lib_OptCoolHeatSeat "This value only use for ATCU Library data monitoring (Only use before SOP)";
BA_ "GenSigSendType" SG_ 859 L_ATCU_Lib_OptCoolHeatSeat 4;
BA_ "UserSigValidity" SG_ 859 L_ATCU_Lib_OptCoolHeatSeat 0;
BA_REL_ "GenSigTimeoutTime" BU_SG_REL_ L_ATCU_vMON SG_ 859 L_ATCU_Lib_OptCoolHeatSeat 5000;
BA_ "Version" SG_ 859 L_ATCU_Lib_OptCoolHeatSeat "23.11.10";
BA_ "Description" SG_ 859 L_ATCU_Lib_OptPTCTyp "This value only use for ATCU Library data monitoring (Only use before SOP)";
BA_ "GenSigSendType" SG_ 859 L_ATCU_Lib_OptPTCTyp 4;
BA_ "UserSigValidity" SG_ 859 L_ATCU_Lib_OptPTCTyp 0;
BA_REL_ "GenSigTimeoutTime" BU_SG_REL_ L_ATCU_vMON SG_ 859 L_ATCU_Lib_OptPTCTyp 5000;
BA_ "Version" SG_ 859 L_ATCU_Lib_OptPTCTyp "23.11.10";
BA_ "Description" SG_ 859 L_ATCU_Lib_OptLCDDisp "This value only use for ATCU Library data monitoring (Only use before SOP)";
BA_ "GenSigSendType" SG_ 859 L_ATCU_Lib_OptLCDDisp 4;
BA_ "UserSigValidity" SG_ 859 L_ATCU_Lib_OptLCDDisp 0;
BA_REL_ "GenSigTimeoutTime" BU_SG_REL_ L_ATCU_vMON SG_ 859 L_ATCU_Lib_OptLCDDisp 5000;
BA_ "Version" SG_ 859 L_ATCU_Lib_OptLCDDisp "23.11.10";
BA_ "Description" SG_ 859 L_ATCU_Lib_OptModSwTyp "This value only use for ATCU Library data monitoring (Only use before SOP)";
BA_ "GenSigSendType" SG_ 859 L_ATCU_Lib_OptModSwTyp 4;
BA_ "UserSigValidity" SG_ 859 L_ATCU_Lib_OptModSwTyp 0;
BA_REL_ "GenSigTimeoutTime" BU_SG_REL_ L_ATCU_vMON SG_ 859 L_ATCU_Lib_OptModSwTyp 5000;
BA_ "Version" SG_ 859 L_ATCU_Lib_OptModSwTyp "23.11.10";
BA_ "Description" SG_ 859 L_ATCU_Lib_OptOffSwTyp "This value only use for ATCU Library data monitoring (Only use before SOP)";
BA_ "GenSigSendType" SG_ 859 L_ATCU_Lib_OptOffSwTyp 4;
BA_ "UserSigValidity" SG_ 859 L_ATCU_Lib_OptOffSwTyp 0;
BA_REL_ "GenSigTimeoutTime" BU_SG_REL_ L_ATCU_vMON SG_ 859 L_ATCU_Lib_OptOffSwTyp 5000;
BA_ "Version" SG_ 859 L_ATCU_Lib_OptOffSwTyp "23.11.10";
BA_ "Description" SG_ 859 L_ATCU_Lib_Opt2ndAutoStep "This value only use for ATCU Library data monitoring (Only use before SOP)";
BA_ "GenSigSendType" SG_ 859 L_ATCU_Lib_Opt2ndAutoStep 4;
BA_ "UserSigValidity" SG_ 859 L_ATCU_Lib_Opt2ndAutoStep 0;
BA_REL_ "GenSigTimeoutTime" BU_SG_REL_ L_ATCU_vMON SG_ 859 L_ATCU_Lib_Opt2ndAutoStep 5000;
BA_ "Version" SG_ 859 L_ATCU_Lib_Opt2ndAutoStep "23.11.10";
BA_ "Description" SG_ 859 L_ATCU_Lib_OptNetworkTyp "This value only use for ATCU Library data monitoring (Only use before SOP)";
BA_ "GenSigSendType" SG_ 859 L_ATCU_Lib_OptNetworkTyp 4;
BA_ "UserSigValidity" SG_ 859 L_ATCU_Lib_OptNetworkTyp 0;
BA_REL_ "GenSigTimeoutTime" BU_SG_REL_ L_ATCU_vMON SG_ 859 L_ATCU_Lib_OptNetworkTyp 5000;
BA_ "Version" SG_ 859 L_ATCU_Lib_OptNetworkTyp "23.11.10";
BA_ "Description" SG_ 859 L_ATCU_Lib_OptPTCStep "This value only use for ATCU Library data monitoring (Only use before SOP)";
BA_ "GenSigSendType" SG_ 859 L_ATCU_Lib_OptPTCStep 4;
BA_ "UserSigValidity" SG_ 859 L_ATCU_Lib_OptPTCStep 0;
BA_REL_ "GenSigTimeoutTime" BU_SG_REL_ L_ATCU_vMON SG_ 859 L_ATCU_Lib_OptPTCStep 5000;
BA_ "Version" SG_ 859 L_ATCU_Lib_OptPTCStep "23.11.10";
BA_ "Description" SG_ 859 L_ATCU_Lib_OptPTG "This value only use for ATCU Library data monitoring (Only use before SOP)";
BA_ "GenSigSendType" SG_ 859 L_ATCU_Lib_OptPTG 4;
BA_ "UserSigValidity" SG_ 859 L_ATCU_Lib_OptPTG 0;
BA_REL_ "GenSigTimeoutTime" BU_SG_REL_ L_ATCU_vMON SG_ 859 L_ATCU_Lib_OptPTG 5000;
BA_ "Version" SG_ 859 L_ATCU_Lib_OptPTG "23.11.10";
BA_ "Description" SG_ 859 L_ATCU_Lib_OptROATyp "This value only use for ATCU Library data monitoring (Only use before SOP)";
BA_ "GenSigSendType" SG_ 859 L_ATCU_Lib_OptROATyp 4;
BA_ "UserSigValidity" SG_ 859 L_ATCU_Lib_OptROATyp 0;
BA_REL_ "GenSigTimeoutTime" BU_SG_REL_ L_ATCU_vMON SG_ 859 L_ATCU_Lib_OptROATyp 5000;
BA_ "Version" SG_ 859 L_ATCU_Lib_OptROATyp "23.11.10";
BA_ "Description" SG_ 859 L_ATCU_Lib_OptVRLED "This value only use for ATCU Library data monitoring (Only use before SOP)";
BA_ "GenSigSendType" SG_ 859 L_ATCU_Lib_OptVRLED 4;
BA_ "UserSigValidity" SG_ 859 L_ATCU_Lib_OptVRLED 0;
BA_REL_ "GenSigTimeoutTime" BU_SG_REL_ L_ATCU_vMON SG_ 859 L_ATCU_Lib_OptVRLED 5000;
BA_ "Version" SG_ 859 L_ATCU_Lib_OptVRLED "25.05.03";
BA_ "Description" SG_ 859 L_ATCU_Lib_OptRgn "This value only use for ATCU Library data monitoring (Only use before SOP)";
BA_ "GenSigSendType" SG_ 859 L_ATCU_Lib_OptRgn 4;
BA_ "UserSigValidity" SG_ 859 L_ATCU_Lib_OptRgn 0;
BA_REL_ "GenSigTimeoutTime" BU_SG_REL_ L_ATCU_vMON SG_ 859 L_ATCU_Lib_OptRgn 5000;
BA_ "Version" SG_ 859 L_ATCU_Lib_OptRgn "23.11.10";
BA_ "Description" SG_ 859 L_ATCU_Lib_OptSchdldVent "This value only use for ATCU Library data monitoring (Only use before SOP)";
BA_ "GenSigSendType" SG_ 859 L_ATCU_Lib_OptSchdldVent 4;
BA_ "UserSigValidity" SG_ 859 L_ATCU_Lib_OptSchdldVent 0;
BA_REL_ "GenSigTimeoutTime" BU_SG_REL_ L_ATCU_vMON SG_ 859 L_ATCU_Lib_OptSchdldVent 5000;
BA_ "Version" SG_ 859 L_ATCU_Lib_OptSchdldVent "23.11.10";
BA_ "Description" SG_ 859 L_ATCU_Lib_OptIntakeSwTyp "This value only use for ATCU Library data monitoring (Only use before SOP)";
BA_ "GenSigSendType" SG_ 859 L_ATCU_Lib_OptIntakeSwTyp 4;
BA_ "UserSigValidity" SG_ 859 L_ATCU_Lib_OptIntakeSwTyp 0;
BA_REL_ "GenSigTimeoutTime" BU_SG_REL_ L_ATCU_vMON SG_ 859 L_ATCU_Lib_OptIntakeSwTyp 5000;
BA_ "Version" SG_ 859 L_ATCU_Lib_OptIntakeSwTyp "23.11.10";
BA_ "Description" SG_ 859 L_ATCU_Lib_OptStrHeat "This value only use for ATCU Library data monitoring (Only use before SOP)";
BA_ "GenSigSendType" SG_ 859 L_ATCU_Lib_OptStrHeat 4;
BA_ "UserSigValidity" SG_ 859 L_ATCU_Lib_OptStrHeat 0;
BA_REL_ "GenSigTimeoutTime" BU_SG_REL_ L_ATCU_vMON SG_ 859 L_ATCU_Lib_OptStrHeat 5000;
BA_ "Version" SG_ 859 L_ATCU_Lib_OptStrHeat "23.11.10";
BA_ "Description" SG_ 859 L_ATCU_Lib_OptSync "This value only use for ATCU Library data monitoring (Only use before SOP)";
BA_ "GenSigSendType" SG_ 859 L_ATCU_Lib_OptSync 4;
BA_ "UserSigValidity" SG_ 859 L_ATCU_Lib_OptSync 0;
BA_REL_ "GenSigTimeoutTime" BU_SG_REL_ L_ATCU_vMON SG_ 859 L_ATCU_Lib_OptSync 5000;
BA_ "Version" SG_ 859 L_ATCU_Lib_OptSync "23.11.10";
BA_ "Description" SG_ 859 L_ATCU_Lib_OptTempSwKnob "This value only use for ATCU Library data monitoring (Only use before SOP)";
BA_ "GenSigSendType" SG_ 859 L_ATCU_Lib_OptTempSwKnob 4;
BA_ "UserSigValidity" SG_ 859 L_ATCU_Lib_OptTempSwKnob 0;
BA_REL_ "GenSigTimeoutTime" BU_SG_REL_ L_ATCU_vMON SG_ 859 L_ATCU_Lib_OptTempSwKnob 5000;
BA_ "Version" SG_ 859 L_ATCU_Lib_OptTempSwKnob "23.11.10";
BA_ "Description" SG_ 859 L_ATCU_Lib_OptThermostat "This value only use for ATCU Library data monitoring (Only use before SOP)";
BA_ "GenSigSendType" SG_ 859 L_ATCU_Lib_OptThermostat 4;
BA_ "UserSigValidity" SG_ 859 L_ATCU_Lib_OptThermostat 0;
BA_REL_ "GenSigTimeoutTime" BU_SG_REL_ L_ATCU_vMON SG_ 859 L_ATCU_Lib_OptThermostat 5000;
BA_ "Version" SG_ 859 L_ATCU_Lib_OptThermostat "23.11.10";
BA_ "Description" SG_ 859 L_ATCU_Lib_OptVehTyp "This value only use for ATCU Library data monitoring (Only use before SOP)";
BA_ "GenSigSendType" SG_ 859 L_ATCU_Lib_OptVehTyp 4;
BA_ "UserSigValidity" SG_ 859 L_ATCU_Lib_OptVehTyp 0;
BA_REL_ "GenSigTimeoutTime" BU_SG_REL_ L_ATCU_vMON SG_ 859 L_ATCU_Lib_OptVehTyp 5000;
BA_ "Version" SG_ 859 L_ATCU_Lib_OptVehTyp "23.11.10";
BA_ "Description" SG_ 859 L_ATCU_Lib_Opt2ndAutoSwTyp "This value only use for ATCU Library data monitoring (Only use before SOP)";
BA_ "GenSigSendType" SG_ 859 L_ATCU_Lib_Opt2ndAutoSwTyp 4;
BA_ "UserSigValidity" SG_ 859 L_ATCU_Lib_Opt2ndAutoSwTyp 0;
BA_REL_ "GenSigTimeoutTime" BU_SG_REL_ L_ATCU_vMON SG_ 859 L_ATCU_Lib_Opt2ndAutoSwTyp 5000;
BA_ "Version" SG_ 859 L_ATCU_Lib_Opt2ndAutoSwTyp "23.11.10";
BA_ "Description" SG_ 859 L_ATCU_Lib_OptWheelDrivePos "This value only use for ATCU Library data monitoring (Only use before SOP)";
BA_ "GenSigSendType" SG_ 859 L_ATCU_Lib_OptWheelDrivePos 4;
BA_ "UserSigValidity" SG_ 859 L_ATCU_Lib_OptWheelDrivePos 0;
BA_REL_ "GenSigTimeoutTime" BU_SG_REL_ L_ATCU_vMON SG_ 859 L_ATCU_Lib_OptWheelDrivePos 5000;
BA_ "Version" SG_ 859 L_ATCU_Lib_OptWheelDrivePos "23.11.10";
BA_ "Description" SG_ 859 L_ATCU_Lib_Opt2ndTempSwKnob "This value only use for ATCU Library data monitoring (Only use before SOP)";
BA_ "GenSigSendType" SG_ 859 L_ATCU_Lib_Opt2ndTempSwKnob 4;
BA_ "UserSigValidity" SG_ 859 L_ATCU_Lib_Opt2ndTempSwKnob 0;
BA_REL_ "GenSigTimeoutTime" BU_SG_REL_ L_ATCU_vMON SG_ 859 L_ATCU_Lib_Opt2ndTempSwKnob 5000;
BA_ "Version" SG_ 859 L_ATCU_Lib_Opt2ndTempSwKnob "23.11.10";
BA_ "Description" SG_ 859 L_ATCU_Lib_Opt2ndBlrBtn "This value only use for ATCU Library data monitoring (Only use before SOP)";
BA_ "GenSigSendType" SG_ 859 L_ATCU_Lib_Opt2ndBlrBtn 4;
BA_ "UserSigValidity" SG_ 859 L_ATCU_Lib_Opt2ndBlrBtn 0;
BA_REL_ "GenSigTimeoutTime" BU_SG_REL_ L_ATCU_vMON SG_ 859 L_ATCU_Lib_Opt2ndBlrBtn 5000;
BA_ "Version" SG_ 859 L_ATCU_Lib_Opt2ndBlrBtn "23.11.10";
BA_ "GenMsgSendType" BO_ 860 0;
BA_ "GenMsgCycleTime" BO_ 860 500;
BA_ "Description" SG_ 860 L_ATCU_Lib_MngrModBufCnt "This value only use for ATCU Library data monitoring (Only use before SOP)";
BA_ "GenSigSendType" SG_ 860 L_ATCU_Lib_MngrModBufCnt 4;
BA_ "UserSigValidity" SG_ 860 L_ATCU_Lib_MngrModBufCnt 0;
BA_REL_ "GenSigTimeoutTime" BU_SG_REL_ L_ATCU_vMON SG_ 860 L_ATCU_Lib_MngrModBufCnt 5000;
BA_ "Version" SG_ 860 L_ATCU_Lib_MngrModBufCnt "23.11.10";
BA_ "Description" SG_ 860 L_ATCU_Lib_MngrDEFBufCnt "This value only use for ATCU Library data monitoring (Only use before SOP)";
BA_ "GenSigSendType" SG_ 860 L_ATCU_Lib_MngrDEFBufCnt 4;
BA_ "UserSigValidity" SG_ 860 L_ATCU_Lib_MngrDEFBufCnt 0;
BA_REL_ "GenSigTimeoutTime" BU_SG_REL_ L_ATCU_vMON SG_ 860 L_ATCU_Lib_MngrDEFBufCnt 5000;
BA_ "Version" SG_ 860 L_ATCU_Lib_MngrDEFBufCnt "23.11.10";
BA_ "Description" SG_ 860 L_ATCU_Lib_MngrBlwBufCnt "This value only use for ATCU Library data monitoring (Only use before SOP)";
BA_ "GenSigSendType" SG_ 860 L_ATCU_Lib_MngrBlwBufCnt 4;
BA_ "UserSigValidity" SG_ 860 L_ATCU_Lib_MngrBlwBufCnt 0;
BA_REL_ "GenSigTimeoutTime" BU_SG_REL_ L_ATCU_vMON SG_ 860 L_ATCU_Lib_MngrBlwBufCnt 5000;
BA_ "Version" SG_ 860 L_ATCU_Lib_MngrBlwBufCnt "23.11.10";
BA_ "Description" SG_ 860 L_ATCU_Lib_MngrACBufCnt "This value only use for ATCU Library data monitoring (Only use before SOP)";
BA_ "GenSigSendType" SG_ 860 L_ATCU_Lib_MngrACBufCnt 4;
BA_ "UserSigValidity" SG_ 860 L_ATCU_Lib_MngrACBufCnt 0;
BA_REL_ "GenSigTimeoutTime" BU_SG_REL_ L_ATCU_vMON SG_ 860 L_ATCU_Lib_MngrACBufCnt 5000;
BA_ "Version" SG_ 860 L_ATCU_Lib_MngrACBufCnt "23.11.10";
BA_ "Description" SG_ 860 L_ATCU_Lib_2LHMngrBlwBufCnt "This value only use for ATCU Library data monitoring (Only use before SOP)";
BA_ "GenSigSendType" SG_ 860 L_ATCU_Lib_2LHMngrBlwBufCnt 4;
BA_ "UserSigValidity" SG_ 860 L_ATCU_Lib_2LHMngrBlwBufCnt 0;
BA_REL_ "GenSigTimeoutTime" BU_SG_REL_ L_ATCU_vMON SG_ 860 L_ATCU_Lib_2LHMngrBlwBufCnt 5000;
BA_ "Version" SG_ 860 L_ATCU_Lib_2LHMngrBlwBufCnt "23.11.10";
BA_ "Description" SG_ 860 L_ATCU_Lib_2LHMngrModBufCnt "This value only use for ATCU Library data monitoring (Only use before SOP)";
BA_ "GenSigSendType" SG_ 860 L_ATCU_Lib_2LHMngrModBufCnt 4;
BA_ "UserSigValidity" SG_ 860 L_ATCU_Lib_2LHMngrModBufCnt 0;
BA_REL_ "GenSigTimeoutTime" BU_SG_REL_ L_ATCU_vMON SG_ 860 L_ATCU_Lib_2LHMngrModBufCnt 5000;
BA_ "Version" SG_ 860 L_ATCU_Lib_2LHMngrModBufCnt "23.11.10";
BA_ "Description" SG_ 860 L_ATCU_Lib_2LHMngrTempBufCnt "This value only use for ATCU Library data monitoring (Only use before SOP)";
BA_ "GenSigSendType" SG_ 860 L_ATCU_Lib_2LHMngrTempBufCnt 4;
BA_ "UserSigValidity" SG_ 860 L_ATCU_Lib_2LHMngrTempBufCnt 0;
BA_REL_ "GenSigTimeoutTime" BU_SG_REL_ L_ATCU_vMON SG_ 860 L_ATCU_Lib_2LHMngrTempBufCnt 5000;
BA_ "Version" SG_ 860 L_ATCU_Lib_2LHMngrTempBufCnt "23.11.10";
BA_ "Description" SG_ 860 L_ATCU_Lib_2RHMngrTempBufCnt "This value only use for ATCU Library data monitoring (Only use before SOP)";
BA_ "GenSigSendType" SG_ 860 L_ATCU_Lib_2RHMngrTempBufCnt 4;
BA_ "UserSigValidity" SG_ 860 L_ATCU_Lib_2RHMngrTempBufCnt 0;
BA_REL_ "GenSigTimeoutTime" BU_SG_REL_ L_ATCU_vMON SG_ 860 L_ATCU_Lib_2RHMngrTempBufCnt 5000;
BA_ "Version" SG_ 860 L_ATCU_Lib_2RHMngrTempBufCnt "23.11.10";
BA_ "Description" SG_ 860 L_ATCU_Lib_MngrTempBufCnt "This value only use for ATCU Library data monitoring (Only use before SOP)";
BA_ "GenSigSendType" SG_ 860 L_ATCU_Lib_MngrTempBufCnt 4;
BA_ "UserSigValidity" SG_ 860 L_ATCU_Lib_MngrTempBufCnt 0;
BA_REL_ "GenSigTimeoutTime" BU_SG_REL_ L_ATCU_vMON SG_ 860 L_ATCU_Lib_MngrTempBufCnt 5000;
BA_ "Version" SG_ 860 L_ATCU_Lib_MngrTempBufCnt "23.11.10";
BA_ "Description" SG_ 860 L_ATCU_Lib_MngrIntakeBufCnt "This value only use for ATCU Library data monitoring (Only use before SOP)";
BA_ "GenSigSendType" SG_ 860 L_ATCU_Lib_MngrIntakeBufCnt 4;
BA_ "UserSigValidity" SG_ 860 L_ATCU_Lib_MngrIntakeBufCnt 0;
BA_REL_ "GenSigTimeoutTime" BU_SG_REL_ L_ATCU_vMON SG_ 860 L_ATCU_Lib_MngrIntakeBufCnt 5000;
BA_ "Version" SG_ 860 L_ATCU_Lib_MngrIntakeBufCnt "23.11.10";
BA_ "GenMsgSendType" BO_ 861 0;
BA_ "GenMsgCycleTime" BO_ 861 500;
BA_ "Description" SG_ 861 L_ATCU_Lib_MngrModBufOp "This value only use for ATCU Library data monitoring (Only use before SOP)";
BA_ "GenSigSendType" SG_ 861 L_ATCU_Lib_MngrModBufOp 4;
BA_ "UserSigValidity" SG_ 861 L_ATCU_Lib_MngrModBufOp 0;
BA_REL_ "GenSigTimeoutTime" BU_SG_REL_ L_ATCU_vMON SG_ 861 L_ATCU_Lib_MngrModBufOp 5000;
BA_ "Version" SG_ 861 L_ATCU_Lib_MngrModBufOp "23.11.10";
BA_ "Description" SG_ 861 L_ATCU_Lib_MngrDEFBufOp "This value only use for ATCU Library data monitoring (Only use before SOP)";
BA_ "GenSigSendType" SG_ 861 L_ATCU_Lib_MngrDEFBufOp 4;
BA_ "UserSigValidity" SG_ 861 L_ATCU_Lib_MngrDEFBufOp 0;
BA_REL_ "GenSigTimeoutTime" BU_SG_REL_ L_ATCU_vMON SG_ 861 L_ATCU_Lib_MngrDEFBufOp 5000;
BA_ "Version" SG_ 861 L_ATCU_Lib_MngrDEFBufOp "23.11.10";
BA_ "Description" SG_ 861 L_ATCU_Lib_MngrBlwBufOp "This value only use for ATCU Library data monitoring (Only use before SOP)";
BA_ "GenSigSendType" SG_ 861 L_ATCU_Lib_MngrBlwBufOp 4;
BA_ "UserSigValidity" SG_ 861 L_ATCU_Lib_MngrBlwBufOp 0;
BA_REL_ "GenSigTimeoutTime" BU_SG_REL_ L_ATCU_vMON SG_ 861 L_ATCU_Lib_MngrBlwBufOp 5000;
BA_ "Version" SG_ 861 L_ATCU_Lib_MngrBlwBufOp "24.06.02";
BA_ "Description" SG_ 861 L_ATCU_Lib_MngrACBufOp "This value only use for ATCU Library data monitoring (Only use before SOP)";
BA_ "GenSigSendType" SG_ 861 L_ATCU_Lib_MngrACBufOp 4;
BA_ "UserSigValidity" SG_ 861 L_ATCU_Lib_MngrACBufOp 0;
BA_REL_ "GenSigTimeoutTime" BU_SG_REL_ L_ATCU_vMON SG_ 861 L_ATCU_Lib_MngrACBufOp 5000;
BA_ "Version" SG_ 861 L_ATCU_Lib_MngrACBufOp "23.11.10";
BA_ "Description" SG_ 861 L_ATCU_Lib_2LHMngrBlwBufOp "This value only use for ATCU Library data monitoring (Only use before SOP)";
BA_ "GenSigSendType" SG_ 861 L_ATCU_Lib_2LHMngrBlwBufOp 4;
BA_ "UserSigValidity" SG_ 861 L_ATCU_Lib_2LHMngrBlwBufOp 0;
BA_REL_ "GenSigTimeoutTime" BU_SG_REL_ L_ATCU_vMON SG_ 861 L_ATCU_Lib_2LHMngrBlwBufOp 5000;
BA_ "Version" SG_ 861 L_ATCU_Lib_2LHMngrBlwBufOp "23.11.10";
BA_ "Description" SG_ 861 L_ATCU_Lib_2LHMngrModBufOp "This value only use for ATCU Library data monitoring (Only use before SOP)";
BA_ "GenSigSendType" SG_ 861 L_ATCU_Lib_2LHMngrModBufOp 4;
BA_ "UserSigValidity" SG_ 861 L_ATCU_Lib_2LHMngrModBufOp 0;
BA_REL_ "GenSigTimeoutTime" BU_SG_REL_ L_ATCU_vMON SG_ 861 L_ATCU_Lib_2LHMngrModBufOp 5000;
BA_ "Version" SG_ 861 L_ATCU_Lib_2LHMngrModBufOp "23.11.10";
BA_ "Description" SG_ 861 L_ATCU_Lib_2LHMngrTempBufOp "This value only use for ATCU Library data monitoring (Only use before SOP)";
BA_ "GenSigSendType" SG_ 861 L_ATCU_Lib_2LHMngrTempBufOp 4;
BA_ "UserSigValidity" SG_ 861 L_ATCU_Lib_2LHMngrTempBufOp 0;
BA_REL_ "GenSigTimeoutTime" BU_SG_REL_ L_ATCU_vMON SG_ 861 L_ATCU_Lib_2LHMngrTempBufOp 5000;
BA_ "Version" SG_ 861 L_ATCU_Lib_2LHMngrTempBufOp "23.11.10";
BA_ "Description" SG_ 861 L_ATCU_Lib_2RHMngrTempBufOp "This value only use for ATCU Library data monitoring (Only use before SOP)";
BA_ "GenSigSendType" SG_ 861 L_ATCU_Lib_2RHMngrTempBufOp 4;
BA_ "UserSigValidity" SG_ 861 L_ATCU_Lib_2RHMngrTempBufOp 0;
BA_REL_ "GenSigTimeoutTime" BU_SG_REL_ L_ATCU_vMON SG_ 861 L_ATCU_Lib_2RHMngrTempBufOp 5000;
BA_ "Version" SG_ 861 L_ATCU_Lib_2RHMngrTempBufOp "23.11.10";
BA_ "Description" SG_ 861 L_ATCU_Lib_MngrActvIncarMotPwr "This value only use for ATCU Library data monitoring (Only use before SOP)";
BA_ "GenSigSendType" SG_ 861 L_ATCU_Lib_MngrActvIncarMotPwr 4;
BA_ "UserSigValidity" SG_ 861 L_ATCU_Lib_MngrActvIncarMotPwr 0;
BA_REL_ "GenSigTimeoutTime" BU_SG_REL_ L_ATCU_vMON SG_ 861 L_ATCU_Lib_MngrActvIncarMotPwr 5000;
BA_ "Version" SG_ 861 L_ATCU_Lib_MngrActvIncarMotPwr "23.11.10";
BA_ "Description" SG_ 861 L_ATCU_Lib_MngrPDCWakeUpReq "This value only use for ATCU Library data monitoring (Only use before SOP)";
BA_ "GenSigSendType" SG_ 861 L_ATCU_Lib_MngrPDCWakeUpReq 4;
BA_ "UserSigValidity" SG_ 861 L_ATCU_Lib_MngrPDCWakeUpReq 0;
BA_REL_ "GenSigTimeoutTime" BU_SG_REL_ L_ATCU_vMON SG_ 861 L_ATCU_Lib_MngrPDCWakeUpReq 5000;
BA_ "Version" SG_ 861 L_ATCU_Lib_MngrPDCWakeUpReq "23.11.10";
BA_ "Description" SG_ 861 L_ATCU_Lib_MngrLVPTCRly1Sta "This value only use for ATCU Library data monitoring (Only use before SOP)";
BA_ "GenSigSendType" SG_ 861 L_ATCU_Lib_MngrLVPTCRly1Sta 4;
BA_ "UserSigValidity" SG_ 861 L_ATCU_Lib_MngrLVPTCRly1Sta 0;
BA_REL_ "GenSigTimeoutTime" BU_SG_REL_ L_ATCU_vMON SG_ 861 L_ATCU_Lib_MngrLVPTCRly1Sta 5000;
BA_ "Version" SG_ 861 L_ATCU_Lib_MngrLVPTCRly1Sta "23.11.10";
BA_ "Description" SG_ 861 L_ATCU_Lib_MngrLVPTCRly2Sta "This value only use for ATCU Library data monitoring (Only use before SOP)";
BA_ "GenSigSendType" SG_ 861 L_ATCU_Lib_MngrLVPTCRly2Sta 4;
BA_ "UserSigValidity" SG_ 861 L_ATCU_Lib_MngrLVPTCRly2Sta 0;
BA_REL_ "GenSigTimeoutTime" BU_SG_REL_ L_ATCU_vMON SG_ 861 L_ATCU_Lib_MngrLVPTCRly2Sta 5000;
BA_ "Version" SG_ 861 L_ATCU_Lib_MngrLVPTCRly2Sta "23.11.10";
BA_ "Description" SG_ 861 L_ATCU_Lib_MngrLVPTCRly3Sta "This value only use for ATCU Library data monitoring (Only use before SOP)";
BA_ "GenSigSendType" SG_ 861 L_ATCU_Lib_MngrLVPTCRly3Sta 4;
BA_ "UserSigValidity" SG_ 861 L_ATCU_Lib_MngrLVPTCRly3Sta 0;
BA_REL_ "GenSigTimeoutTime" BU_SG_REL_ L_ATCU_vMON SG_ 861 L_ATCU_Lib_MngrLVPTCRly3Sta 5000;
BA_ "Version" SG_ 861 L_ATCU_Lib_MngrLVPTCRly3Sta "23.11.10";
BA_ "Description" SG_ 861 L_ATCU_Lib_MngrTempBufOp "This value only use for ATCU Library data monitoring (Only use before SOP)";
BA_ "GenSigSendType" SG_ 861 L_ATCU_Lib_MngrTempBufOp 4;
BA_ "UserSigValidity" SG_ 861 L_ATCU_Lib_MngrTempBufOp 0;
BA_REL_ "GenSigTimeoutTime" BU_SG_REL_ L_ATCU_vMON SG_ 861 L_ATCU_Lib_MngrTempBufOp 5000;
BA_ "Version" SG_ 861 L_ATCU_Lib_MngrTempBufOp "23.11.10";
BA_ "Description" SG_ 861 L_ATCU_Lib_MngrIntakeBufOp "This value only use for ATCU Library data monitoring (Only use before SOP)";
BA_ "GenSigSendType" SG_ 861 L_ATCU_Lib_MngrIntakeBufOp 4;
BA_ "UserSigValidity" SG_ 861 L_ATCU_Lib_MngrIntakeBufOp 0;
BA_REL_ "GenSigTimeoutTime" BU_SG_REL_ L_ATCU_vMON SG_ 861 L_ATCU_Lib_MngrIntakeBufOp 5000;
BA_ "Version" SG_ 861 L_ATCU_Lib_MngrIntakeBufOp "24.09.00";
BA_ "GenMsgSendType" BO_ 862 0;
BA_ "GenMsgCycleTime" BO_ 862 500;
BA_ "Description" SG_ 862 L_ATCU_Lib_MngrModBuf0 "This value only use for ATCU Library data monitoring (Only use before SOP)";
BA_ "GenSigSendType" SG_ 862 L_ATCU_Lib_MngrModBuf0 4;
BA_ "UserSigValidity" SG_ 862 L_ATCU_Lib_MngrModBuf0 0;
BA_REL_ "GenSigTimeoutTime" BU_SG_REL_ L_ATCU_vMON SG_ 862 L_ATCU_Lib_MngrModBuf0 5000;
BA_ "Version" SG_ 862 L_ATCU_Lib_MngrModBuf0 "25.05.03";
BA_ "Description" SG_ 862 L_ATCU_Lib_MngrModBufLow1 "This value only use for ATCU Library data monitoring (Only use before SOP)";
BA_ "GenSigSendType" SG_ 862 L_ATCU_Lib_MngrModBufLow1 4;
BA_ "UserSigValidity" SG_ 862 L_ATCU_Lib_MngrModBufLow1 0;
BA_REL_ "GenSigTimeoutTime" BU_SG_REL_ L_ATCU_vMON SG_ 862 L_ATCU_Lib_MngrModBufLow1 5000;
BA_ "Version" SG_ 862 L_ATCU_Lib_MngrModBufLow1 "23.11.10";
BA_ "Description" SG_ 862 L_ATCU_Lib_MngrModBuf2 "This value only use for ATCU Library data monitoring (Only use before SOP)";
BA_ "GenSigSendType" SG_ 862 L_ATCU_Lib_MngrModBuf2 4;
BA_ "UserSigValidity" SG_ 862 L_ATCU_Lib_MngrModBuf2 0;
BA_REL_ "GenSigTimeoutTime" BU_SG_REL_ L_ATCU_vMON SG_ 862 L_ATCU_Lib_MngrModBuf2 5000;
BA_ "Version" SG_ 862 L_ATCU_Lib_MngrModBuf2 "25.05.03";
BA_ "Description" SG_ 862 L_ATCU_Lib_MngrModBufHi0 "This value only use for ATCU Library data monitoring (Only use before SOP)";
BA_ "GenSigSendType" SG_ 862 L_ATCU_Lib_MngrModBufHi0 4;
BA_ "UserSigValidity" SG_ 862 L_ATCU_Lib_MngrModBufHi0 0;
BA_REL_ "GenSigTimeoutTime" BU_SG_REL_ L_ATCU_vMON SG_ 862 L_ATCU_Lib_MngrModBufHi0 5000;
BA_ "Version" SG_ 862 L_ATCU_Lib_MngrModBufHi0 "23.11.10";
BA_ "Description" SG_ 862 L_ATCU_Lib_MngrModBuf3 "This value only use for ATCU Library data monitoring (Only use before SOP)";
BA_ "GenSigSendType" SG_ 862 L_ATCU_Lib_MngrModBuf3 4;
BA_ "UserSigValidity" SG_ 862 L_ATCU_Lib_MngrModBuf3 0;
BA_REL_ "GenSigTimeoutTime" BU_SG_REL_ L_ATCU_vMON SG_ 862 L_ATCU_Lib_MngrModBuf3 5000;
BA_ "Version" SG_ 862 L_ATCU_Lib_MngrModBuf3 "25.05.03";
BA_ "Description" SG_ 862 L_ATCU_Lib_MngrModBufHi1 "This value only use for ATCU Library data monitoring (Only use before SOP)";
BA_ "GenSigSendType" SG_ 862 L_ATCU_Lib_MngrModBufHi1 4;
BA_ "UserSigValidity" SG_ 862 L_ATCU_Lib_MngrModBufHi1 0;
BA_REL_ "GenSigTimeoutTime" BU_SG_REL_ L_ATCU_vMON SG_ 862 L_ATCU_Lib_MngrModBufHi1 5000;
BA_ "Version" SG_ 862 L_ATCU_Lib_MngrModBufHi1 "23.11.10";
BA_ "Description" SG_ 862 L_ATCU_Lib_MngrModBuf4 "This value only use for ATCU Library data monitoring (Only use before SOP)";
BA_ "GenSigSendType" SG_ 862 L_ATCU_Lib_MngrModBuf4 4;
BA_ "UserSigValidity" SG_ 862 L_ATCU_Lib_MngrModBuf4 0;
BA_REL_ "GenSigTimeoutTime" BU_SG_REL_ L_ATCU_vMON SG_ 862 L_ATCU_Lib_MngrModBuf4 5000;
BA_ "Version" SG_ 862 L_ATCU_Lib_MngrModBuf4 "25.05.03";
BA_ "Description" SG_ 862 L_ATCU_Lib_MngrModBuf5 "This value only use for ATCU Library data monitoring (Only use before SOP)";
BA_ "GenSigSendType" SG_ 862 L_ATCU_Lib_MngrModBuf5 4;
BA_ "UserSigValidity" SG_ 862 L_ATCU_Lib_MngrModBuf5 0;
BA_REL_ "GenSigTimeoutTime" BU_SG_REL_ L_ATCU_vMON SG_ 862 L_ATCU_Lib_MngrModBuf5 5000;
BA_ "Version" SG_ 862 L_ATCU_Lib_MngrModBuf5 "25.05.03";
BA_ "Description" SG_ 862 L_ATCU_Lib_MngrModBuf6 "This value only use for ATCU Library data monitoring (Only use before SOP)";
BA_ "GenSigSendType" SG_ 862 L_ATCU_Lib_MngrModBuf6 4;
BA_ "UserSigValidity" SG_ 862 L_ATCU_Lib_MngrModBuf6 0;
BA_REL_ "GenSigTimeoutTime" BU_SG_REL_ L_ATCU_vMON SG_ 862 L_ATCU_Lib_MngrModBuf6 5000;
BA_ "Version" SG_ 862 L_ATCU_Lib_MngrModBuf6 "25.05.03";
BA_ "Description" SG_ 862 L_ATCU_Lib_MngrModBufLow0 "This value only use for ATCU Library data monitoring (Only use before SOP)";
BA_ "GenSigSendType" SG_ 862 L_ATCU_Lib_MngrModBufLow0 4;
BA_ "UserSigValidity" SG_ 862 L_ATCU_Lib_MngrModBufLow0 0;
BA_REL_ "GenSigTimeoutTime" BU_SG_REL_ L_ATCU_vMON SG_ 862 L_ATCU_Lib_MngrModBufLow0 5000;
BA_ "Version" SG_ 862 L_ATCU_Lib_MngrModBufLow0 "23.11.10";
BA_ "Description" SG_ 862 L_ATCU_Lib_MngrModBuf7 "This value only use for ATCU Library data monitoring (Only use before SOP)";
BA_ "GenSigSendType" SG_ 862 L_ATCU_Lib_MngrModBuf7 4;
BA_ "UserSigValidity" SG_ 862 L_ATCU_Lib_MngrModBuf7 0;
BA_REL_ "GenSigTimeoutTime" BU_SG_REL_ L_ATCU_vMON SG_ 862 L_ATCU_Lib_MngrModBuf7 5000;
BA_ "Version" SG_ 862 L_ATCU_Lib_MngrModBuf7 "25.05.03";
BA_ "Description" SG_ 862 L_ATCU_Lib_MngrModBuf1 "This value only use for ATCU Library data monitoring (Only use before SOP)";
BA_ "GenSigSendType" SG_ 862 L_ATCU_Lib_MngrModBuf1 4;
BA_ "UserSigValidity" SG_ 862 L_ATCU_Lib_MngrModBuf1 0;
BA_REL_ "GenSigTimeoutTime" BU_SG_REL_ L_ATCU_vMON SG_ 862 L_ATCU_Lib_MngrModBuf1 5000;
BA_ "Version" SG_ 862 L_ATCU_Lib_MngrModBuf1 "25.05.03";
BA_ "GenMsgSendType" BO_ 863 0;
BA_ "GenMsgCycleTime" BO_ 863 500;
BA_ "Description" SG_ 863 L_ATCU_Lib_MngrBlwBuf0 "This value only use for ATCU Library data monitoring (Only use before SOP)";
BA_ "GenSigSendType" SG_ 863 L_ATCU_Lib_MngrBlwBuf0 4;
BA_ "UserSigValidity" SG_ 863 L_ATCU_Lib_MngrBlwBuf0 0;
BA_REL_ "GenSigTimeoutTime" BU_SG_REL_ L_ATCU_vMON SG_ 863 L_ATCU_Lib_MngrBlwBuf0 5000;
BA_ "Version" SG_ 863 L_ATCU_Lib_MngrBlwBuf0 "25.05.03";
BA_ "Description" SG_ 863 L_ATCU_Lib_MngrBlwBuf3 "This value only use for ATCU Library data monitoring (Only use before SOP)";
BA_ "GenSigSendType" SG_ 863 L_ATCU_Lib_MngrBlwBuf3 4;
BA_ "UserSigValidity" SG_ 863 L_ATCU_Lib_MngrBlwBuf3 0;
BA_REL_ "GenSigTimeoutTime" BU_SG_REL_ L_ATCU_vMON SG_ 863 L_ATCU_Lib_MngrBlwBuf3 5000;
BA_ "Version" SG_ 863 L_ATCU_Lib_MngrBlwBuf3 "25.05.03";
BA_ "Description" SG_ 863 L_ATCU_Lib_MngrBlwBuf4 "This value only use for ATCU Library data monitoring (Only use before SOP)";
BA_ "GenSigSendType" SG_ 863 L_ATCU_Lib_MngrBlwBuf4 4;
BA_ "UserSigValidity" SG_ 863 L_ATCU_Lib_MngrBlwBuf4 0;
BA_REL_ "GenSigTimeoutTime" BU_SG_REL_ L_ATCU_vMON SG_ 863 L_ATCU_Lib_MngrBlwBuf4 5000;
BA_ "Version" SG_ 863 L_ATCU_Lib_MngrBlwBuf4 "25.05.03";
BA_ "Description" SG_ 863 L_ATCU_Lib_MngrBlwBuf5 "This value only use for ATCU Library data monitoring (Only use before SOP)";
BA_ "GenSigSendType" SG_ 863 L_ATCU_Lib_MngrBlwBuf5 4;
BA_ "UserSigValidity" SG_ 863 L_ATCU_Lib_MngrBlwBuf5 0;
BA_REL_ "GenSigTimeoutTime" BU_SG_REL_ L_ATCU_vMON SG_ 863 L_ATCU_Lib_MngrBlwBuf5 5000;
BA_ "Version" SG_ 863 L_ATCU_Lib_MngrBlwBuf5 "25.05.03";
BA_ "Description" SG_ 863 L_ATCU_Lib_MngrBlwBuf6 "This value only use for ATCU Library data monitoring (Only use before SOP)";
BA_ "GenSigSendType" SG_ 863 L_ATCU_Lib_MngrBlwBuf6 4;
BA_ "UserSigValidity" SG_ 863 L_ATCU_Lib_MngrBlwBuf6 0;
BA_REL_ "GenSigTimeoutTime" BU_SG_REL_ L_ATCU_vMON SG_ 863 L_ATCU_Lib_MngrBlwBuf6 5000;
BA_ "Version" SG_ 863 L_ATCU_Lib_MngrBlwBuf6 "25.05.03";
BA_ "Description" SG_ 863 L_ATCU_Lib_MngrBlwBuf7 "This value only use for ATCU Library data monitoring (Only use before SOP)";
BA_ "GenSigSendType" SG_ 863 L_ATCU_Lib_MngrBlwBuf7 4;
BA_ "UserSigValidity" SG_ 863 L_ATCU_Lib_MngrBlwBuf7 0;
BA_REL_ "GenSigTimeoutTime" BU_SG_REL_ L_ATCU_vMON SG_ 863 L_ATCU_Lib_MngrBlwBuf7 5000;
BA_ "Version" SG_ 863 L_ATCU_Lib_MngrBlwBuf7 "25.05.03";
BA_ "Description" SG_ 863 L_ATCU_Lib_MngrBlwBufHi0 "This value only use for ATCU Library data monitoring (Only use before SOP)";
BA_ "GenSigSendType" SG_ 863 L_ATCU_Lib_MngrBlwBufHi0 4;
BA_ "UserSigValidity" SG_ 863 L_ATCU_Lib_MngrBlwBufHi0 0;
BA_REL_ "GenSigTimeoutTime" BU_SG_REL_ L_ATCU_vMON SG_ 863 L_ATCU_Lib_MngrBlwBufHi0 5000;
BA_ "Version" SG_ 863 L_ATCU_Lib_MngrBlwBufHi0 "23.11.10";
BA_ "Description" SG_ 863 L_ATCU_Lib_MngrBlwBufLow0 "This value only use for ATCU Library data monitoring (Only use before SOP)";
BA_ "GenSigSendType" SG_ 863 L_ATCU_Lib_MngrBlwBufLow0 4;
BA_ "UserSigValidity" SG_ 863 L_ATCU_Lib_MngrBlwBufLow0 0;
BA_REL_ "GenSigTimeoutTime" BU_SG_REL_ L_ATCU_vMON SG_ 863 L_ATCU_Lib_MngrBlwBufLow0 5000;
BA_ "Version" SG_ 863 L_ATCU_Lib_MngrBlwBufLow0 "23.11.10";
BA_ "Description" SG_ 863 L_ATCU_Lib_MngrBlwBufLow1 "This value only use for ATCU Library data monitoring (Only use before SOP)";
BA_ "GenSigSendType" SG_ 863 L_ATCU_Lib_MngrBlwBufLow1 4;
BA_ "UserSigValidity" SG_ 863 L_ATCU_Lib_MngrBlwBufLow1 0;
BA_REL_ "GenSigTimeoutTime" BU_SG_REL_ L_ATCU_vMON SG_ 863 L_ATCU_Lib_MngrBlwBufLow1 5000;
BA_ "Version" SG_ 863 L_ATCU_Lib_MngrBlwBufLow1 "23.11.10";
BA_ "Description" SG_ 863 L_ATCU_Lib_MngrBlwBuf1 "This value only use for ATCU Library data monitoring (Only use before SOP)";
BA_ "GenSigSendType" SG_ 863 L_ATCU_Lib_MngrBlwBuf1 4;
BA_ "UserSigValidity" SG_ 863 L_ATCU_Lib_MngrBlwBuf1 0;
BA_REL_ "GenSigTimeoutTime" BU_SG_REL_ L_ATCU_vMON SG_ 863 L_ATCU_Lib_MngrBlwBuf1 5000;
BA_ "Version" SG_ 863 L_ATCU_Lib_MngrBlwBuf1 "25.05.03";
BA_ "Description" SG_ 863 L_ATCU_Lib_MngrBlwBufHi1 "This value only use for ATCU Library data monitoring (Only use before SOP)";
BA_ "GenSigSendType" SG_ 863 L_ATCU_Lib_MngrBlwBufHi1 4;
BA_ "UserSigValidity" SG_ 863 L_ATCU_Lib_MngrBlwBufHi1 0;
BA_REL_ "GenSigTimeoutTime" BU_SG_REL_ L_ATCU_vMON SG_ 863 L_ATCU_Lib_MngrBlwBufHi1 5000;
BA_ "Version" SG_ 863 L_ATCU_Lib_MngrBlwBufHi1 "23.11.10";
BA_ "Description" SG_ 863 L_ATCU_Lib_MngrBlwBufLow2 "This value only use for ATCU Library data monitoring (Only use before SOP)";
BA_ "GenSigSendType" SG_ 863 L_ATCU_Lib_MngrBlwBufLow2 4;
BA_ "UserSigValidity" SG_ 863 L_ATCU_Lib_MngrBlwBufLow2 0;
BA_REL_ "GenSigTimeoutTime" BU_SG_REL_ L_ATCU_vMON SG_ 863 L_ATCU_Lib_MngrBlwBufLow2 5000;
BA_ "Version" SG_ 863 L_ATCU_Lib_MngrBlwBufLow2 "23.11.10";
BA_ "Description" SG_ 863 L_ATCU_Lib_MngrBlwBufLow3 "This value only use for ATCU Library data monitoring (Only use before SOP)";
BA_ "GenSigSendType" SG_ 863 L_ATCU_Lib_MngrBlwBufLow3 4;
BA_ "UserSigValidity" SG_ 863 L_ATCU_Lib_MngrBlwBufLow3 0;
BA_REL_ "GenSigTimeoutTime" BU_SG_REL_ L_ATCU_vMON SG_ 863 L_ATCU_Lib_MngrBlwBufLow3 5000;
BA_ "Version" SG_ 863 L_ATCU_Lib_MngrBlwBufLow3 "23.11.10";
BA_ "Description" SG_ 863 L_ATCU_Lib_MngrBlwBufHi2 "This value only use for ATCU Library data monitoring (Only use before SOP)";
BA_ "GenSigSendType" SG_ 863 L_ATCU_Lib_MngrBlwBufHi2 4;
BA_ "UserSigValidity" SG_ 863 L_ATCU_Lib_MngrBlwBufHi2 0;
BA_REL_ "GenSigTimeoutTime" BU_SG_REL_ L_ATCU_vMON SG_ 863 L_ATCU_Lib_MngrBlwBufHi2 5000;
BA_ "Version" SG_ 863 L_ATCU_Lib_MngrBlwBufHi2 "23.11.10";
BA_ "Description" SG_ 863 L_ATCU_Lib_MngrBlwBuf2 "This value only use for ATCU Library data monitoring (Only use before SOP)";
BA_ "GenSigSendType" SG_ 863 L_ATCU_Lib_MngrBlwBuf2 4;
BA_ "UserSigValidity" SG_ 863 L_ATCU_Lib_MngrBlwBuf2 0;
BA_REL_ "GenSigTimeoutTime" BU_SG_REL_ L_ATCU_vMON SG_ 863 L_ATCU_Lib_MngrBlwBuf2 5000;
BA_ "Version" SG_ 863 L_ATCU_Lib_MngrBlwBuf2 "25.05.03";
BA_ "GenMsgSendType" BO_ 913 0;
BA_ "GenMsgCycleTime" BO_ 913 500;
BA_ "Description" SG_ 913 L_ATCU_Lib_ADSBlrVtgVal "This value only use for ATCU Library data monitoring (Only use before SOP)";
BA_ "GenSigSendType" SG_ 913 L_ATCU_Lib_ADSBlrVtgVal 4;
BA_ "UserSigValidity" SG_ 913 L_ATCU_Lib_ADSBlrVtgVal 0;
BA_REL_ "GenSigTimeoutTime" BU_SG_REL_ L_ATCU_vMON SG_ 913 L_ATCU_Lib_ADSBlrVtgVal 5000;
BA_ "Version" SG_ 913 L_ATCU_Lib_ADSBlrVtgVal "23.11.10";
BA_ "Description" SG_ 913 L_ATCU_Lib_ADSDEFDrState "This value only use for ATCU Library data monitoring (Only use before SOP)";
BA_ "GenSigSendType" SG_ 913 L_ATCU_Lib_ADSDEFDrState 4;
BA_ "UserSigValidity" SG_ 913 L_ATCU_Lib_ADSDEFDrState 0;
BA_REL_ "GenSigTimeoutTime" BU_SG_REL_ L_ATCU_vMON SG_ 913 L_ATCU_Lib_ADSDEFDrState 5000;
BA_ "Version" SG_ 913 L_ATCU_Lib_ADSDEFDrState "23.11.10";
BA_ "Description" SG_ 913 L_ATCU_Lib_ADSACDispPreHoldReq "This value only use for ATCU Library data monitoring (Only use before SOP)";
BA_ "GenSigSendType" SG_ 913 L_ATCU_Lib_ADSACDispPreHoldReq 4;
BA_ "UserSigValidity" SG_ 913 L_ATCU_Lib_ADSACDispPreHoldReq 0;
BA_REL_ "GenSigTimeoutTime" BU_SG_REL_ L_ATCU_vMON SG_ 913 L_ATCU_Lib_ADSACDispPreHoldReq 5000;
BA_ "Version" SG_ 913 L_ATCU_Lib_ADSACDispPreHoldReq "23.11.10";
BA_ "Description" SG_ 913 L_ATCU_Lib_ADSACForcedOnReq "This value only use for ATCU Library data monitoring (Only use before SOP)";
BA_ "GenSigSendType" SG_ 913 L_ATCU_Lib_ADSACForcedOnReq 4;
BA_ "UserSigValidity" SG_ 913 L_ATCU_Lib_ADSACForcedOnReq 0;
BA_REL_ "GenSigTimeoutTime" BU_SG_REL_ L_ATCU_vMON SG_ 913 L_ATCU_Lib_ADSACForcedOnReq 5000;
BA_ "Version" SG_ 913 L_ATCU_Lib_ADSACForcedOnReq "23.11.10";
BA_ "Description" SG_ 913 L_ATCU_Lib_ADSACState "This value only use for ATCU Library data monitoring (Only use before SOP)";
BA_ "GenSigSendType" SG_ 913 L_ATCU_Lib_ADSACState 4;
BA_ "UserSigValidity" SG_ 913 L_ATCU_Lib_ADSACState 0;
BA_REL_ "GenSigTimeoutTime" BU_SG_REL_ L_ATCU_vMON SG_ 913 L_ATCU_Lib_ADSACState 5000;
BA_ "Version" SG_ 913 L_ATCU_Lib_ADSACState "23.11.10";
BA_ "Description" SG_ 913 L_ATCU_Lib_ADSInhibitPIReq "This value only use for ATCU Library data monitoring (Only use before SOP)";
BA_ "GenSigSendType" SG_ 913 L_ATCU_Lib_ADSInhibitPIReq 4;
BA_ "UserSigValidity" SG_ 913 L_ATCU_Lib_ADSInhibitPIReq 0;
BA_REL_ "GenSigTimeoutTime" BU_SG_REL_ L_ATCU_vMON SG_ 913 L_ATCU_Lib_ADSInhibitPIReq 5000;
BA_ "Version" SG_ 913 L_ATCU_Lib_ADSInhibitPIReq "23.11.10";
BA_ "Description" SG_ 913 L_ATCU_Lib_ADSModPrfleChgReq "This value only use for ATCU Library data monitoring (Only use before SOP)";
BA_ "GenSigSendType" SG_ 913 L_ATCU_Lib_ADSModPrfleChgReq 4;
BA_ "UserSigValidity" SG_ 913 L_ATCU_Lib_ADSModPrfleChgReq 0;
BA_REL_ "GenSigTimeoutTime" BU_SG_REL_ L_ATCU_vMON SG_ 913 L_ATCU_Lib_ADSModPrfleChgReq 5000;
BA_ "Version" SG_ 913 L_ATCU_Lib_ADSModPrfleChgReq "23.11.10";
BA_ "Description" SG_ 913 L_ATCU_Lib_ADSIntakeState "This value only use for ATCU Library data monitoring (Only use before SOP)";
BA_ "GenSigSendType" SG_ 913 L_ATCU_Lib_ADSIntakeState 4;
BA_ "UserSigValidity" SG_ 913 L_ATCU_Lib_ADSIntakeState 0;
BA_REL_ "GenSigTimeoutTime" BU_SG_REL_ L_ATCU_vMON SG_ 913 L_ATCU_Lib_ADSIntakeState 5000;
BA_ "Version" SG_ 913 L_ATCU_Lib_ADSIntakeState "23.11.10";
BA_ "Description" SG_ 913 L_ATCU_Lib_ADSTempDrLmtState "This value only use for ATCU Library data monitoring (Only use before SOP)";
BA_ "GenSigSendType" SG_ 913 L_ATCU_Lib_ADSTempDrLmtState 4;
BA_ "UserSigValidity" SG_ 913 L_ATCU_Lib_ADSTempDrLmtState 0;
BA_REL_ "GenSigTimeoutTime" BU_SG_REL_ L_ATCU_vMON SG_ 913 L_ATCU_Lib_ADSTempDrLmtState 5000;
BA_ "Version" SG_ 913 L_ATCU_Lib_ADSTempDrLmtState "23.11.10";
BA_ "Description" SG_ 913 L_ATCU_Lib_ADSOpState "This value only use for ATCU Library data monitoring (Only use before SOP)";
BA_ "GenSigSendType" SG_ 913 L_ATCU_Lib_ADSOpState 4;
BA_ "UserSigValidity" SG_ 913 L_ATCU_Lib_ADSOpState 0;
BA_REL_ "GenSigTimeoutTime" BU_SG_REL_ L_ATCU_vMON SG_ 913 L_ATCU_Lib_ADSOpState 5000;
BA_ "Version" SG_ 913 L_ATCU_Lib_ADSOpState "23.11.10";
BA_ "Description" SG_ 913 L_ATCU_Lib_ADSSymState "This value only use for ATCU Library data monitoring (Only use before SOP)";
BA_ "GenSigSendType" SG_ 913 L_ATCU_Lib_ADSSymState 4;
BA_ "UserSigValidity" SG_ 913 L_ATCU_Lib_ADSSymState 0;
BA_REL_ "GenSigTimeoutTime" BU_SG_REL_ L_ATCU_vMON SG_ 913 L_ATCU_Lib_ADSSymState 5000;
BA_ "Version" SG_ 913 L_ATCU_Lib_ADSSymState "23.11.10";
BA_ "GenMsgSendType" BO_ 914 0;
BA_ "GenMsgCycleTime" BO_ 914 500;
BA_ "Description" SG_ 914 L_ATCU_Lib_PIIntakeState "This value only use for ATCU Library data monitoring (Only use before SOP)";
BA_ "GenSigSendType" SG_ 914 L_ATCU_Lib_PIIntakeState 4;
BA_ "UserSigValidity" SG_ 914 L_ATCU_Lib_PIIntakeState 0;
BA_REL_ "GenSigTimeoutTime" BU_SG_REL_ L_ATCU_vMON SG_ 914 L_ATCU_Lib_PIIntakeState 5000;
BA_ "Version" SG_ 914 L_ATCU_Lib_PIIntakeState "23.11.10";
BA_ "Description" SG_ 914 L_ATCU_Lib_AEWPOnReq "This value only use for ATCU Library data monitoring (Only use before SOP)";
BA_ "GenSigSendType" SG_ 914 L_ATCU_Lib_AEWPOnReq 4;
BA_ "UserSigValidity" SG_ 914 L_ATCU_Lib_AEWPOnReq 0;
BA_REL_ "GenSigTimeoutTime" BU_SG_REL_ L_ATCU_vMON SG_ 914 L_ATCU_Lib_AEWPOnReq 5000;
BA_ "Version" SG_ 914 L_ATCU_Lib_AEWPOnReq "23.11.10";
BA_ "Description" SG_ 914 L_ATCU_Lib_AEWPRPMVal "This value only use for ATCU Library data monitoring (Only use before SOP)";
BA_ "GenSigSendType" SG_ 914 L_ATCU_Lib_AEWPRPMVal 4;
BA_ "UserSigValidity" SG_ 914 L_ATCU_Lib_AEWPRPMVal 0;
BA_REL_ "GenSigTimeoutTime" BU_SG_REL_ L_ATCU_vMON SG_ 914 L_ATCU_Lib_AEWPRPMVal 5000;
BA_ "Version" SG_ 914 L_ATCU_Lib_AEWPRPMVal "23.11.10";
BA_ "Description" SG_ 914 L_ATCULib_AmbFilterResetOpState "This value only use for ATCU Library data monitoring (Only use before SOP)";
BA_ "GenSigSendType" SG_ 914 L_ATCULib_AmbFilterResetOpState 4;
BA_ "UserSigValidity" SG_ 914 L_ATCULib_AmbFilterResetOpState 0;
BA_REL_ "GenSigTimeoutTime" BU_SG_REL_ L_ATCU_vMON SG_ 914 L_ATCULib_AmbFilterResetOpState 5000;
BA_ "Version" SG_ 914 L_ATCULib_AmbFilterResetOpState "24.06.02";
BA_ "Description" SG_ 914 L_ATCULib_HVACIntlckHVActOffReq "This value only use for ATCU Library data monitoring (Only use before SOP)";
BA_ "GenSigSendType" SG_ 914 L_ATCULib_HVACIntlckHVActOffReq 4;
BA_ "UserSigValidity" SG_ 914 L_ATCULib_HVACIntlckHVActOffReq 0;
BA_REL_ "GenSigTimeoutTime" BU_SG_REL_ L_ATCU_vMON SG_ 914 L_ATCULib_HVACIntlckHVActOffReq 5000;
BA_ "Version" SG_ 914 L_ATCULib_HVACIntlckHVActOffReq "24.06.02";
BA_ "Description" SG_ 914 L_ATCULib_MainRlyProtectOpState "This value only use for ATCU Library data monitoring (Only use before SOP)";
BA_ "GenSigSendType" SG_ 914 L_ATCULib_MainRlyProtectOpState 4;
BA_ "UserSigValidity" SG_ 914 L_ATCULib_MainRlyProtectOpState 0;
BA_REL_ "GenSigTimeoutTime" BU_SG_REL_ L_ATCU_vMON SG_ 914 L_ATCULib_MainRlyProtectOpState 5000;
BA_ "Version" SG_ 914 L_ATCULib_MainRlyProtectOpState "24.06.02";
BA_ "Description" SG_ 914 L_ATCULib_ETCIntlckHVActOffReq "This value only use for ATCU Library data monitoring (Only use before SOP)";
BA_ "GenSigSendType" SG_ 914 L_ATCULib_ETCIntlckHVActOffReq 4;
BA_ "UserSigValidity" SG_ 914 L_ATCULib_ETCIntlckHVActOffReq 0;
BA_REL_ "GenSigTimeoutTime" BU_SG_REL_ L_ATCU_vMON SG_ 914 L_ATCULib_ETCIntlckHVActOffReq 5000;
BA_ "Version" SG_ 914 L_ATCULib_ETCIntlckHVActOffReq "24.06.02";
BA_ "Description" SG_ 914 L_ATCULib_SyncSwSta "This value only use for ATCU Library data monitoring (Only use before SOP)";
BA_ "GenSigSendType" SG_ 914 L_ATCULib_SyncSwSta 4;
BA_ "UserSigValidity" SG_ 914 L_ATCULib_SyncSwSta 0;
BA_REL_ "GenSigTimeoutTime" BU_SG_REL_ L_ATCU_vMON SG_ 914 L_ATCULib_SyncSwSta 5000;
BA_ "Version" SG_ 914 L_ATCULib_SyncSwSta "24.06.02";
BA_ "GenMsgSendType" BO_ 833 0;
BA_ "GenMsgCycleTime" BO_ 833 500;
BA_ "Description" SG_ 833 MON_DiagAct_DrvModDrLck "This value only use for ATCU Library data monitoring (Only use before SOP)";
BA_ "GenSigSendType" SG_ 833 MON_DiagAct_DrvModDrLck 4;
BA_ "UserSigValidity" SG_ 833 MON_DiagAct_DrvModDrLck 0;
BA_REL_ "GenSigTimeoutTime" BU_SG_REL_ L_ATCU SG_ 833 MON_DiagAct_DrvModDrLck 5000;
BA_ "Version" SG_ 833 MON_DiagAct_DrvModDrLck "25.05.04";
BA_ "Description" SG_ 833 MON_DiagAct_AstModDrOpnSrt "This value only use for ATCU Library data monitoring (Only use before SOP)";
BA_ "GenSigSendType" SG_ 833 MON_DiagAct_AstModDrOpnSrt 4;
BA_ "UserSigValidity" SG_ 833 MON_DiagAct_AstModDrOpnSrt 0;
BA_REL_ "GenSigTimeoutTime" BU_SG_REL_ L_ATCU SG_ 833 MON_DiagAct_AstModDrOpnSrt 5000;
BA_ "Version" SG_ 833 MON_DiagAct_AstModDrOpnSrt "25.05.04";
BA_ "Description" SG_ 833 MON_DiagAct_AstTmpDrOpnSrt "This value only use for ATCU Library data monitoring (Only use before SOP)";
BA_ "GenSigSendType" SG_ 833 MON_DiagAct_AstTmpDrOpnSrt 4;
BA_ "UserSigValidity" SG_ 833 MON_DiagAct_AstTmpDrOpnSrt 0;
BA_REL_ "GenSigTimeoutTime" BU_SG_REL_ L_ATCU SG_ 833 MON_DiagAct_AstTmpDrOpnSrt 5000;
BA_ "Version" SG_ 833 MON_DiagAct_AstTmpDrOpnSrt "25.05.04";
BA_ "Description" SG_ 833 MON_DiagAct_DrvTmpDrLck "This value only use for ATCU Library data monitoring (Only use before SOP)";
BA_ "GenSigSendType" SG_ 833 MON_DiagAct_DrvTmpDrLck 4;
BA_ "UserSigValidity" SG_ 833 MON_DiagAct_DrvTmpDrLck 0;
BA_REL_ "GenSigTimeoutTime" BU_SG_REL_ L_ATCU SG_ 833 MON_DiagAct_DrvTmpDrLck 5000;
BA_ "Version" SG_ 833 MON_DiagAct_DrvTmpDrLck "25.05.04";
BA_ "Description" SG_ 833 MON_DiagAct_AstTmpDrLck "This value only use for ATCU Library data monitoring (Only use before SOP)";
BA_ "GenSigSendType" SG_ 833 MON_DiagAct_AstTmpDrLck 4;
BA_ "UserSigValidity" SG_ 833 MON_DiagAct_AstTmpDrLck 0;
BA_REL_ "GenSigTimeoutTime" BU_SG_REL_ L_ATCU SG_ 833 MON_DiagAct_AstTmpDrLck 5000;
BA_ "Version" SG_ 833 MON_DiagAct_AstTmpDrLck "25.05.04";
BA_ "Description" SG_ 833 MON_DiagAct_DrvModDrOpnSrt "This value only use for ATCU Library data monitoring (Only use before SOP)";
BA_ "GenSigSendType" SG_ 833 MON_DiagAct_DrvModDrOpnSrt 4;
BA_ "UserSigValidity" SG_ 833 MON_DiagAct_DrvModDrOpnSrt 0;
BA_REL_ "GenSigTimeoutTime" BU_SG_REL_ L_ATCU SG_ 833 MON_DiagAct_DrvModDrOpnSrt 5000;
BA_ "Version" SG_ 833 MON_DiagAct_DrvModDrOpnSrt "25.05.04";
BA_ "Description" SG_ 833 MON_DiagAct_DEFDrLck "This value only use for ATCU Library data monitoring (Only use before SOP)";
BA_ "GenSigSendType" SG_ 833 MON_DiagAct_DEFDrLck 4;
BA_ "UserSigValidity" SG_ 833 MON_DiagAct_DEFDrLck 0;
BA_REL_ "GenSigTimeoutTime" BU_SG_REL_ L_ATCU SG_ 833 MON_DiagAct_DEFDrLck 5000;
BA_ "Version" SG_ 833 MON_DiagAct_DEFDrLck "25.05.04";
BA_ "Description" SG_ 833 MON_DiagAct_IntakeDrLck "This value only use for ATCU Library data monitoring (Only use before SOP)";
BA_ "GenSigSendType" SG_ 833 MON_DiagAct_IntakeDrLck 4;
BA_ "UserSigValidity" SG_ 833 MON_DiagAct_IntakeDrLck 0;
BA_REL_ "GenSigTimeoutTime" BU_SG_REL_ L_ATCU SG_ 833 MON_DiagAct_IntakeDrLck 5000;
BA_ "Version" SG_ 833 MON_DiagAct_IntakeDrLck "25.05.04";
BA_ "Description" SG_ 833 MON_DiagAct_IntakeDrOpnSrt "This value only use for ATCU Library data monitoring (Only use before SOP)";
BA_ "GenSigSendType" SG_ 833 MON_DiagAct_IntakeDrOpnSrt 4;
BA_ "UserSigValidity" SG_ 833 MON_DiagAct_IntakeDrOpnSrt 0;
BA_REL_ "GenSigTimeoutTime" BU_SG_REL_ L_ATCU SG_ 833 MON_DiagAct_IntakeDrOpnSrt 5000;
BA_ "Version" SG_ 833 MON_DiagAct_IntakeDrOpnSrt "25.05.04";
BA_ "Description" SG_ 833 MON_DiagAct_DEFDrOpnSrt "This value only use for ATCU Library data monitoring (Only use before SOP)";
BA_ "GenSigSendType" SG_ 833 MON_DiagAct_DEFDrOpnSrt 4;
BA_ "UserSigValidity" SG_ 833 MON_DiagAct_DEFDrOpnSrt 0;
BA_REL_ "GenSigTimeoutTime" BU_SG_REL_ L_ATCU SG_ 833 MON_DiagAct_DEFDrOpnSrt 5000;
BA_ "Version" SG_ 833 MON_DiagAct_DEFDrOpnSrt "25.05.04";
BA_ "Description" SG_ 833 MON_DiagAct_ECompIntlck "This value only use for ATCU Library data monitoring (Only use before SOP)";
BA_ "GenSigSendType" SG_ 833 MON_DiagAct_ECompIntlck 4;
BA_ "UserSigValidity" SG_ 833 MON_DiagAct_ECompIntlck 0;
BA_REL_ "GenSigTimeoutTime" BU_SG_REL_ L_ATCU SG_ 833 MON_DiagAct_ECompIntlck 5000;
BA_ "Version" SG_ 833 MON_DiagAct_ECompIntlck "25.05.04";
BA_ "Description" SG_ 833 MON_DiagAct_HVPTCIntlck "This value only use for ATCU Library data monitoring (Only use before SOP)";
BA_ "GenSigSendType" SG_ 833 MON_DiagAct_HVPTCIntlck 4;
BA_ "UserSigValidity" SG_ 833 MON_DiagAct_HVPTCIntlck 0;
BA_REL_ "GenSigTimeoutTime" BU_SG_REL_ L_ATCU SG_ 833 MON_DiagAct_HVPTCIntlck 5000;
BA_ "Version" SG_ 833 MON_DiagAct_HVPTCIntlck "25.05.04";
BA_ "Description" SG_ 833 MON_DiagAct_BatChlrEXVOpnSrt "This value only use for ATCU Library data monitoring (Only use before SOP)";
BA_ "GenSigSendType" SG_ 833 MON_DiagAct_BatChlrEXVOpnSrt 4;
BA_ "UserSigValidity" SG_ 833 MON_DiagAct_BatChlrEXVOpnSrt 0;
BA_REL_ "GenSigTimeoutTime" BU_SG_REL_ L_ATCU SG_ 833 MON_DiagAct_BatChlrEXVOpnSrt 5000;
BA_ "Version" SG_ 833 MON_DiagAct_BatChlrEXVOpnSrt "25.05.04";
BA_ "Description" SG_ 833 MON_DiagAct_EvapTXVOpnSrt "This value only use for ATCU Library data monitoring (Only use before SOP)";
BA_ "GenSigSendType" SG_ 833 MON_DiagAct_EvapTXVOpnSrt 4;
BA_ "UserSigValidity" SG_ 833 MON_DiagAct_EvapTXVOpnSrt 0;
BA_REL_ "GenSigTimeoutTime" BU_SG_REL_ L_ATCU SG_ 833 MON_DiagAct_EvapTXVOpnSrt 5000;
BA_ "Version" SG_ 833 MON_DiagAct_EvapTXVOpnSrt "25.05.04";
BA_ "Description" SG_ 833 MON_DiagAct_FrtPWMBlr "This value only use for ATCU Library data monitoring (Only use before SOP)";
BA_ "GenSigSendType" SG_ 833 MON_DiagAct_FrtPWMBlr 4;
BA_ "UserSigValidity" SG_ 833 MON_DiagAct_FrtPWMBlr 0;
BA_REL_ "GenSigTimeoutTime" BU_SG_REL_ L_ATCU SG_ 833 MON_DiagAct_FrtPWMBlr 5000;
BA_ "Version" SG_ 833 MON_DiagAct_FrtPWMBlr "25.05.04";
BA_ "Description" SG_ 833 MON_DiagAct_ECV "This value only use for ATCU Library data monitoring (Only use before SOP)";
BA_ "GenSigSendType" SG_ 833 MON_DiagAct_ECV 4;
BA_ "UserSigValidity" SG_ 833 MON_DiagAct_ECV 0;
BA_REL_ "GenSigTimeoutTime" BU_SG_REL_ L_ATCU SG_ 833 MON_DiagAct_ECV 5000;
BA_ "Version" SG_ 833 MON_DiagAct_ECV "25.05.04";
BA_ "Description" SG_ 833 MON_DiagAct_Rfgrant "This value only use for ATCU Library data monitoring (Only use before SOP)";
BA_ "GenSigSendType" SG_ 833 MON_DiagAct_Rfgrant 4;
BA_ "UserSigValidity" SG_ 833 MON_DiagAct_Rfgrant 0;
BA_REL_ "GenSigTimeoutTime" BU_SG_REL_ L_ATCU SG_ 833 MON_DiagAct_Rfgrant 5000;
BA_ "Version" SG_ 833 MON_DiagAct_Rfgrant "25.05.04";
BA_ "Description" SG_ 833 MON_DiagAct_DrvTmpDrOpnSrt "This value only use for ATCU Library data monitoring (Only use before SOP)";
BA_ "GenSigSendType" SG_ 833 MON_DiagAct_DrvTmpDrOpnSrt 4;
BA_ "UserSigValidity" SG_ 833 MON_DiagAct_DrvTmpDrOpnSrt 0;
BA_REL_ "GenSigTimeoutTime" BU_SG_REL_ L_ATCU SG_ 833 MON_DiagAct_DrvTmpDrOpnSrt 5000;
BA_ "Version" SG_ 833 MON_DiagAct_DrvTmpDrOpnSrt "25.05.04";
BA_ "Description" SG_ 833 MON_DiagAct_VRLed "This value only use for ATCU Library data monitoring (Only use before SOP)";
BA_ "GenSigSendType" SG_ 833 MON_DiagAct_VRLed 4;
BA_ "UserSigValidity" SG_ 833 MON_DiagAct_VRLed 0;
BA_REL_ "GenSigTimeoutTime" BU_SG_REL_ L_ATCU SG_ 833 MON_DiagAct_VRLed 5000;
BA_ "Version" SG_ 833 MON_DiagAct_VRLed "25.05.04";
BA_ "Description" SG_ 833 MON_DiagAct_AstModDrLck "This value only use for ATCU Library data monitoring (Only use before SOP)";
BA_ "GenSigSendType" SG_ 833 MON_DiagAct_AstModDrLck 4;
BA_ "UserSigValidity" SG_ 833 MON_DiagAct_AstModDrLck 0;
BA_REL_ "GenSigTimeoutTime" BU_SG_REL_ L_ATCU SG_ 833 MON_DiagAct_AstModDrLck 5000;
BA_ "Version" SG_ 833 MON_DiagAct_AstModDrLck "25.05.04";
BA_ "GenMsgSendType" BO_ 834 0;
BA_ "GenMsgCycleTime" BO_ 834 500;
BA_ "Description" SG_ 834 MON_DiagCOM_AcnOpPerm "This value only use for ATCU Library data monitoring (Only use before SOP)";
BA_ "GenSigSendType" SG_ 834 MON_DiagCOM_AcnOpPerm 4;
BA_ "UserSigValidity" SG_ 834 MON_DiagCOM_AcnOpPerm 0;
BA_REL_ "GenSigTimeoutTime" BU_SG_REL_ L_ATCU SG_ 834 MON_DiagCOM_AcnOpPerm 5000;
BA_ "Version" SG_ 834 MON_DiagCOM_AcnOpPerm "25.05.04";
BA_ "Description" SG_ 834 MON_DiagCOM_BMSTmout "This value only use for ATCU Library data monitoring (Only use before SOP)";
BA_ "GenSigSendType" SG_ 834 MON_DiagCOM_BMSTmout 4;
BA_ "UserSigValidity" SG_ 834 MON_DiagCOM_BMSTmout 0;
BA_REL_ "GenSigTimeoutTime" BU_SG_REL_ L_ATCU SG_ 834 MON_DiagCOM_BMSTmout 5000;
BA_ "Version" SG_ 834 MON_DiagCOM_BMSTmout "25.05.04";
BA_ "Description" SG_ 834 MON_DiagCOM_DrvClHtStOpt "This value only use for ATCU Library data monitoring (Only use before SOP)";
BA_ "GenSigSendType" SG_ 834 MON_DiagCOM_DrvClHtStOpt 4;
BA_ "UserSigValidity" SG_ 834 MON_DiagCOM_DrvClHtStOpt 0;
BA_REL_ "GenSigTimeoutTime" BU_SG_REL_ L_ATCU SG_ 834 MON_DiagCOM_DrvClHtStOpt 5000;
BA_ "Version" SG_ 834 MON_DiagCOM_DrvClHtStOpt "25.05.04";
BA_ "Description" SG_ 834 MON_DiagCOM_AstClHtStOpt "This value only use for ATCU Library data monitoring (Only use before SOP)";
BA_ "GenSigSendType" SG_ 834 MON_DiagCOM_AstClHtStOpt 4;
BA_ "UserSigValidity" SG_ 834 MON_DiagCOM_AstClHtStOpt 0;
BA_REL_ "GenSigTimeoutTime" BU_SG_REL_ L_ATCU SG_ 834 MON_DiagCOM_AstClHtStOpt 5000;
BA_ "Version" SG_ 834 MON_DiagCOM_AstClHtStOpt "25.05.04";
BA_ "Description" SG_ 834 MON_DiagCOM_EcoModSw "This value only use for ATCU Library data monitoring (Only use before SOP)";
BA_ "GenSigSendType" SG_ 834 MON_DiagCOM_EcoModSw 4;
BA_ "UserSigValidity" SG_ 834 MON_DiagCOM_EcoModSw 0;
BA_REL_ "GenSigTimeoutTime" BU_SG_REL_ L_ATCU SG_ 834 MON_DiagCOM_EcoModSw 5000;
BA_ "Version" SG_ 834 MON_DiagCOM_EcoModSw "25.05.04";
BA_ "Description" SG_ 834 MON_DiagCOM_EcompTmout "This value only use for ATCU Library data monitoring (Only use before SOP)";
BA_ "GenSigSendType" SG_ 834 MON_DiagCOM_EcompTmout 4;
BA_ "UserSigValidity" SG_ 834 MON_DiagCOM_EcompTmout 0;
BA_REL_ "GenSigTimeoutTime" BU_SG_REL_ L_ATCU SG_ 834 MON_DiagCOM_EcompTmout 5000;
BA_ "Version" SG_ 834 MON_DiagCOM_EcompTmout "25.05.04";
BA_ "Description" SG_ 834 MON_DiagCOM_APT "This value only use for ATCU Library data monitoring (Only use before SOP)";
BA_ "GenSigSendType" SG_ 834 MON_DiagCOM_APT 4;
BA_ "UserSigValidity" SG_ 834 MON_DiagCOM_APT 0;
BA_REL_ "GenSigTimeoutTime" BU_SG_REL_ L_ATCU SG_ 834 MON_DiagCOM_APT 5000;
BA_ "Version" SG_ 834 MON_DiagCOM_APT "25.05.04";
BA_ "Description" SG_ 834 MON_DiagCOM_EMSVehSpd "This value only use for ATCU Library data monitoring (Only use before SOP)";
BA_ "GenSigSendType" SG_ 834 MON_DiagCOM_EMSVehSpd 4;
BA_ "UserSigValidity" SG_ 834 MON_DiagCOM_EMSVehSpd 0;
BA_REL_ "GenSigTimeoutTime" BU_SG_REL_ L_ATCU SG_ 834 MON_DiagCOM_EMSVehSpd 5000;
BA_ "Version" SG_ 834 MON_DiagCOM_EMSVehSpd "25.05.04";
BA_ "Description" SG_ 834 MON_DiagCOM_EngCool "This value only use for ATCU Library data monitoring (Only use before SOP)";
BA_ "GenSigSendType" SG_ 834 MON_DiagCOM_EngCool 4;
BA_ "UserSigValidity" SG_ 834 MON_DiagCOM_EngCool 0;
BA_REL_ "GenSigTimeoutTime" BU_SG_REL_ L_ATCU SG_ 834 MON_DiagCOM_EngCool 5000;
BA_ "Version" SG_ 834 MON_DiagCOM_EngCool "25.05.04";
BA_ "Description" SG_ 834 MON_DiagCOM_EngOpMod "This value only use for ATCU Library data monitoring (Only use before SOP)";
BA_ "GenSigSendType" SG_ 834 MON_DiagCOM_EngOpMod 4;
BA_ "UserSigValidity" SG_ 834 MON_DiagCOM_EngOpMod 0;
BA_REL_ "GenSigTimeoutTime" BU_SG_REL_ L_ATCU SG_ 834 MON_DiagCOM_EngOpMod 5000;
BA_ "Version" SG_ 834 MON_DiagCOM_EngOpMod "25.05.04";
BA_ "Description" SG_ 834 MON_DiagCOM_HEVRdy "This value only use for ATCU Library data monitoring (Only use before SOP)";
BA_ "GenSigSendType" SG_ 834 MON_DiagCOM_HEVRdy 4;
BA_ "UserSigValidity" SG_ 834 MON_DiagCOM_HEVRdy 0;
BA_REL_ "GenSigTimeoutTime" BU_SG_REL_ L_ATCU SG_ 834 MON_DiagCOM_HEVRdy 5000;
BA_ "Version" SG_ 834 MON_DiagCOM_HEVRdy "25.05.04";
BA_ "Description" SG_ 834 MON_DiagCOM_HVPTCTmout "This value only use for ATCU Library data monitoring (Only use before SOP)";
BA_ "GenSigSendType" SG_ 834 MON_DiagCOM_HVPTCTmout 4;
BA_ "UserSigValidity" SG_ 834 MON_DiagCOM_HVPTCTmout 0;
BA_REL_ "GenSigTimeoutTime" BU_SG_REL_ L_ATCU SG_ 834 MON_DiagCOM_HVPTCTmout 5000;
BA_ "Version" SG_ 834 MON_DiagCOM_HVPTCTmout "25.05.04";
BA_ "Description" SG_ 834 MON_DiagCOM_LDCWatt "This value only use for ATCU Library data monitoring (Only use before SOP)";
BA_ "GenSigSendType" SG_ 834 MON_DiagCOM_LDCWatt 4;
BA_ "UserSigValidity" SG_ 834 MON_DiagCOM_LDCWatt 0;
BA_REL_ "GenSigTimeoutTime" BU_SG_REL_ L_ATCU SG_ 834 MON_DiagCOM_LDCWatt 5000;
BA_ "Version" SG_ 834 MON_DiagCOM_LDCWatt "25.05.04";
BA_ "Description" SG_ 834 MON_DiagCOM_LHPhoto "This value only use for ATCU Library data monitoring (Only use before SOP)";
BA_ "GenSigSendType" SG_ 834 MON_DiagCOM_LHPhoto 4;
BA_ "UserSigValidity" SG_ 834 MON_DiagCOM_LHPhoto 0;
BA_REL_ "GenSigTimeoutTime" BU_SG_REL_ L_ATCU SG_ 834 MON_DiagCOM_LHPhoto 5000;
BA_ "Version" SG_ 834 MON_DiagCOM_LHPhoto "25.05.04";
BA_ "Description" SG_ 834 MON_DiagCOM_MainRlyOnSta "This value only use for ATCU Library data monitoring (Only use before SOP)";
BA_ "GenSigSendType" SG_ 834 MON_DiagCOM_MainRlyOnSta 4;
BA_ "UserSigValidity" SG_ 834 MON_DiagCOM_MainRlyOnSta 0;
BA_REL_ "GenSigTimeoutTime" BU_SG_REL_ L_ATCU SG_ 834 MON_DiagCOM_MainRlyOnSta 5000;
BA_ "Version" SG_ 834 MON_DiagCOM_MainRlyOnSta "25.05.04";
BA_ "Description" SG_ 834 MON_DiagCOM_MCUTmout "This value only use for ATCU Library data monitoring (Only use before SOP)";
BA_ "GenSigSendType" SG_ 834 MON_DiagCOM_MCUTmout 4;
BA_ "UserSigValidity" SG_ 834 MON_DiagCOM_MCUTmout 0;
BA_REL_ "GenSigTimeoutTime" BU_SG_REL_ L_ATCU SG_ 834 MON_DiagCOM_MCUTmout 5000;
BA_ "Version" SG_ 834 MON_DiagCOM_MCUTmout "25.05.04";
BA_ "Description" SG_ 834 MON_DiagCOM_PMSnsr "This value only use for ATCU Library data monitoring (Only use before SOP)";
BA_ "GenSigSendType" SG_ 834 MON_DiagCOM_PMSnsr 4;
BA_ "UserSigValidity" SG_ 834 MON_DiagCOM_PMSnsr 0;
BA_REL_ "GenSigTimeoutTime" BU_SG_REL_ L_ATCU SG_ 834 MON_DiagCOM_PMSnsr 5000;
BA_ "Version" SG_ 834 MON_DiagCOM_PMSnsr "25.05.04";
BA_ "Description" SG_ 834 MON_DiagCOM_BatChlrEXVDiag "This value only use for ATCU Library data monitoring (Only use before SOP)";
BA_ "GenSigSendType" SG_ 834 MON_DiagCOM_BatChlrEXVDiag 4;
BA_ "UserSigValidity" SG_ 834 MON_DiagCOM_BatChlrEXVDiag 0;
BA_REL_ "GenSigTimeoutTime" BU_SG_REL_ L_ATCU SG_ 834 MON_DiagCOM_BatChlrEXVDiag 5000;
BA_ "Version" SG_ 834 MON_DiagCOM_BatChlrEXVDiag "25.05.04";
BA_ "Description" SG_ 834 MON_DiagCOM_PnlBusOff "This value only use for ATCU Library data monitoring (Only use before SOP)";
BA_ "GenSigSendType" SG_ 834 MON_DiagCOM_PnlBusOff 4;
BA_ "UserSigValidity" SG_ 834 MON_DiagCOM_PnlBusOff 0;
BA_REL_ "GenSigTimeoutTime" BU_SG_REL_ L_ATCU SG_ 834 MON_DiagCOM_PnlBusOff 5000;
BA_ "Version" SG_ 834 MON_DiagCOM_PnlBusOff "25.05.04";
BA_ "Description" SG_ 834 MON_DiagCOM_PTGOpt "This value only use for ATCU Library data monitoring (Only use before SOP)";
BA_ "GenSigSendType" SG_ 834 MON_DiagCOM_PTGOpt 4;
BA_ "UserSigValidity" SG_ 834 MON_DiagCOM_PTGOpt 0;
BA_REL_ "GenSigTimeoutTime" BU_SG_REL_ L_ATCU SG_ 834 MON_DiagCOM_PTGOpt 5000;
BA_ "Version" SG_ 834 MON_DiagCOM_PTGOpt "25.05.04";
BA_ "Description" SG_ 834 MON_DiagCOM_RHPhoto "This value only use for ATCU Library data monitoring (Only use before SOP)";
BA_ "GenSigSendType" SG_ 834 MON_DiagCOM_RHPhoto 4;
BA_ "UserSigValidity" SG_ 834 MON_DiagCOM_RHPhoto 0;
BA_REL_ "GenSigTimeoutTime" BU_SG_REL_ L_ATCU SG_ 834 MON_DiagCOM_RHPhoto 5000;
BA_ "Version" SG_ 834 MON_DiagCOM_RHPhoto "25.05.04";
BA_ "Description" SG_ 834 MON_DiagCOM_RPM "This value only use for ATCU Library data monitoring (Only use before SOP)";
BA_ "GenSigSendType" SG_ 834 MON_DiagCOM_RPM 4;
BA_ "UserSigValidity" SG_ 834 MON_DiagCOM_RPM 0;
BA_REL_ "GenSigTimeoutTime" BU_SG_REL_ L_ATCU SG_ 834 MON_DiagCOM_RPM 5000;
BA_ "Version" SG_ 834 MON_DiagCOM_RPM "25.05.04";
BA_ "Description" SG_ 834 MON_DiagCOM_SideMirAmb "This value only use for ATCU Library data monitoring (Only use before SOP)";
BA_ "GenSigSendType" SG_ 834 MON_DiagCOM_SideMirAmb 4;
BA_ "UserSigValidity" SG_ 834 MON_DiagCOM_SideMirAmb 0;
BA_REL_ "GenSigTimeoutTime" BU_SG_REL_ L_ATCU SG_ 834 MON_DiagCOM_SideMirAmb 5000;
BA_ "Version" SG_ 834 MON_DiagCOM_SideMirAmb "25.05.04";
BA_ "Description" SG_ 834 MON_DiagCOM_ServiceMod "This value only use for ATCU Library data monitoring (Only use before SOP)";
BA_ "GenSigSendType" SG_ 834 MON_DiagCOM_ServiceMod 4;
BA_ "UserSigValidity" SG_ 834 MON_DiagCOM_ServiceMod 0;
BA_REL_ "GenSigTimeoutTime" BU_SG_REL_ L_ATCU SG_ 834 MON_DiagCOM_ServiceMod 5000;
BA_ "Version" SG_ 834 MON_DiagCOM_ServiceMod "25.05.04";
BA_ "Description" SG_ 834 MON_DiagCOM_StrHtOpt "This value only use for ATCU Library data monitoring (Only use before SOP)";
BA_ "GenSigSendType" SG_ 834 MON_DiagCOM_StrHtOpt 4;
BA_ "UserSigValidity" SG_ 834 MON_DiagCOM_StrHtOpt 0;
BA_REL_ "GenSigTimeoutTime" BU_SG_REL_ L_ATCU SG_ 834 MON_DiagCOM_StrHtOpt 5000;
BA_ "Version" SG_ 834 MON_DiagCOM_StrHtOpt "25.05.04";
BA_ "Description" SG_ 834 MON_DiagCOM_TCUVehSpd "This value only use for ATCU Library data monitoring (Only use before SOP)";
BA_ "GenSigSendType" SG_ 834 MON_DiagCOM_TCUVehSpd 4;
BA_ "UserSigValidity" SG_ 834 MON_DiagCOM_TCUVehSpd 0;
BA_REL_ "GenSigTimeoutTime" BU_SG_REL_ L_ATCU SG_ 834 MON_DiagCOM_TCUVehSpd 5000;
BA_ "Version" SG_ 834 MON_DiagCOM_TCUVehSpd "25.05.04";
BA_ "Description" SG_ 834 MON_DiagCOM_Torque "This value only use for ATCU Library data monitoring (Only use before SOP)";
BA_ "GenSigSendType" SG_ 834 MON_DiagCOM_Torque 4;
BA_ "UserSigValidity" SG_ 834 MON_DiagCOM_Torque 0;
BA_REL_ "GenSigTimeoutTime" BU_SG_REL_ L_ATCU SG_ 834 MON_DiagCOM_Torque 5000;
BA_ "Version" SG_ 834 MON_DiagCOM_Torque "25.05.04";
BA_ "Description" SG_ 834 MON_DiagCOM_VehBusOff "This value only use for ATCU Library data monitoring (Only use before SOP)";
BA_ "GenSigSendType" SG_ 834 MON_DiagCOM_VehBusOff 4;
BA_ "UserSigValidity" SG_ 834 MON_DiagCOM_VehBusOff 0;
BA_REL_ "GenSigTimeoutTime" BU_SG_REL_ L_ATCU SG_ 834 MON_DiagCOM_VehBusOff 5000;
BA_ "Version" SG_ 834 MON_DiagCOM_VehBusOff "25.05.04";
BA_ "Description" SG_ 834 MON_DiagCOM_BATSoc "This value only use for ATCU Library data monitoring (Only use before SOP)";
BA_ "GenSigSendType" SG_ 834 MON_DiagCOM_BATSoc 4;
BA_ "UserSigValidity" SG_ 834 MON_DiagCOM_BATSoc 0;
BA_REL_ "GenSigTimeoutTime" BU_SG_REL_ L_ATCU SG_ 834 MON_DiagCOM_BATSoc 5000;
BA_ "Version" SG_ 834 MON_DiagCOM_BATSoc "25.05.04";
BA_ "Description" SG_ 834 MON_DiagCOM_WhlSpd "This value only use for ATCU Library data monitoring (Only use before SOP)";
BA_ "GenSigSendType" SG_ 834 MON_DiagCOM_WhlSpd 4;
BA_ "UserSigValidity" SG_ 834 MON_DiagCOM_WhlSpd 0;
BA_REL_ "GenSigTimeoutTime" BU_SG_REL_ L_ATCU SG_ 834 MON_DiagCOM_WhlSpd 5000;
BA_ "Version" SG_ 834 MON_DiagCOM_WhlSpd "25.05.04";
BA_ "Description" SG_ 834 MON_DiagCOM_ClmtBusOff "This value only use for ATCU Library data monitoring (Only use before SOP)";
BA_ "GenSigSendType" SG_ 834 MON_DiagCOM_ClmtBusOff 4;
BA_ "UserSigValidity" SG_ 834 MON_DiagCOM_ClmtBusOff 0;
BA_REL_ "GenSigTimeoutTime" BU_SG_REL_ L_ATCU SG_ 834 MON_DiagCOM_ClmtBusOff 5000;
BA_ "Version" SG_ 834 MON_DiagCOM_ClmtBusOff "25.05.04";
BA_ "Description" SG_ 834 MON_DiagCOM_BMSIntakeReq "This value only use for ATCU Library data monitoring (Only use before SOP)";
BA_ "GenSigSendType" SG_ 834 MON_DiagCOM_BMSIntakeReq 4;
BA_ "UserSigValidity" SG_ 834 MON_DiagCOM_BMSIntakeReq 0;
BA_REL_ "GenSigTimeoutTime" BU_SG_REL_ L_ATCU SG_ 834 MON_DiagCOM_BMSIntakeReq 5000;
BA_ "Version" SG_ 834 MON_DiagCOM_BMSIntakeReq "25.05.04";
BA_ "GenMsgSendType" BO_ 835 0;
BA_ "GenMsgCycleTime" BO_ 835 500;
BA_ "Description" SG_ 835 MON_DiagSnsr_AMBTmp "This value only use for ATCU Library data monitoring (Only use before SOP)";
BA_ "GenSigSendType" SG_ 835 MON_DiagSnsr_AMBTmp 4;
BA_ "UserSigValidity" SG_ 835 MON_DiagSnsr_AMBTmp 0;
BA_REL_ "GenSigTimeoutTime" BU_SG_REL_ L_ATCU SG_ 835 MON_DiagSnsr_AMBTmp 5000;
BA_ "Version" SG_ 835 MON_DiagSnsr_AMBTmp "25.05.04";
BA_ "Description" SG_ 835 MON_DiagSnsr_DEFDuctTmp "This value only use for ATCU Library data monitoring (Only use before SOP)";
BA_ "GenSigSendType" SG_ 835 MON_DiagSnsr_DEFDuctTmp 4;
BA_ "UserSigValidity" SG_ 835 MON_DiagSnsr_DEFDuctTmp 0;
BA_REL_ "GenSigTimeoutTime" BU_SG_REL_ L_ATCU SG_ 835 MON_DiagSnsr_DEFDuctTmp 5000;
BA_ "Version" SG_ 835 MON_DiagSnsr_DEFDuctTmp "25.05.04";
BA_ "Description" SG_ 835 MON_DiagSnsr_DOH "This value only use for ATCU Library data monitoring (Only use before SOP)";
BA_ "GenSigSendType" SG_ 835 MON_DiagSnsr_DOH 4;
BA_ "UserSigValidity" SG_ 835 MON_DiagSnsr_DOH 0;
BA_REL_ "GenSigTimeoutTime" BU_SG_REL_ L_ATCU SG_ 835 MON_DiagSnsr_DOH 5000;
BA_ "Version" SG_ 835 MON_DiagSnsr_DOH "25.05.04";
BA_ "Description" SG_ 835 MON_DiagSnsr_DrvFlrDuctTmp "This value only use for ATCU Library data monitoring (Only use before SOP)";
BA_ "GenSigSendType" SG_ 835 MON_DiagSnsr_DrvFlrDuctTmp 4;
BA_ "UserSigValidity" SG_ 835 MON_DiagSnsr_DrvFlrDuctTmp 0;
BA_REL_ "GenSigTimeoutTime" BU_SG_REL_ L_ATCU SG_ 835 MON_DiagSnsr_DrvFlrDuctTmp 5000;
BA_ "Version" SG_ 835 MON_DiagSnsr_DrvFlrDuctTmp "25.05.04";
BA_ "Description" SG_ 835 MON_DiagSnsr_DrvVntDuctTmp "This value only use for ATCU Library data monitoring (Only use before SOP)";
BA_ "GenSigSendType" SG_ 835 MON_DiagSnsr_DrvVntDuctTmp 4;
BA_ "UserSigValidity" SG_ 835 MON_DiagSnsr_DrvVntDuctTmp 0;
BA_REL_ "GenSigTimeoutTime" BU_SG_REL_ L_ATCU SG_ 835 MON_DiagSnsr_DrvVntDuctTmp 5000;
BA_ "Version" SG_ 835 MON_DiagSnsr_DrvVntDuctTmp "25.05.04";
BA_ "Description" SG_ 835 MON_DiagSnsr_EvapTmp "This value only use for ATCU Library data monitoring (Only use before SOP)";
BA_ "GenSigSendType" SG_ 835 MON_DiagSnsr_EvapTmp 4;
BA_ "UserSigValidity" SG_ 835 MON_DiagSnsr_EvapTmp 0;
BA_REL_ "GenSigTimeoutTime" BU_SG_REL_ L_ATCU SG_ 835 MON_DiagSnsr_EvapTmp 5000;
BA_ "Version" SG_ 835 MON_DiagSnsr_EvapTmp "25.05.04";
BA_ "Description" SG_ 835 MON_DiagSnsr_AstFlrDuctTmp "This value only use for ATCU Library data monitoring (Only use before SOP)";
BA_ "GenSigSendType" SG_ 835 MON_DiagSnsr_AstFlrDuctTmp 4;
BA_ "UserSigValidity" SG_ 835 MON_DiagSnsr_AstFlrDuctTmp 0;
BA_REL_ "GenSigTimeoutTime" BU_SG_REL_ L_ATCU SG_ 835 MON_DiagSnsr_AstFlrDuctTmp 5000;
BA_ "Version" SG_ 835 MON_DiagSnsr_AstFlrDuctTmp "25.05.04";
BA_ "Description" SG_ 835 MON_DiagSnsr_FDust "This value only use for ATCU Library data monitoring (Only use before SOP)";
BA_ "GenSigSendType" SG_ 835 MON_DiagSnsr_FDust 4;
BA_ "UserSigValidity" SG_ 835 MON_DiagSnsr_FDust 0;
BA_REL_ "GenSigTimeoutTime" BU_SG_REL_ L_ATCU SG_ 835 MON_DiagSnsr_FDust 5000;
BA_ "Version" SG_ 835 MON_DiagSnsr_FDust "25.05.04";
BA_ "Description" SG_ 835 MON_DiagSnsr_HghPrsrRfgPT "This value only use for ATCU Library data monitoring (Only use before SOP)";
BA_ "GenSigSendType" SG_ 835 MON_DiagSnsr_HghPrsrRfgPT 4;
BA_ "UserSigValidity" SG_ 835 MON_DiagSnsr_HghPrsrRfgPT 0;
BA_REL_ "GenSigTimeoutTime" BU_SG_REL_ L_ATCU SG_ 835 MON_DiagSnsr_HghPrsrRfgPT 5000;
BA_ "Version" SG_ 835 MON_DiagSnsr_HghPrsrRfgPT "25.05.04";
BA_ "Description" SG_ 835 MON_DiagSnsr_InCarTmp "This value only use for ATCU Library data monitoring (Only use before SOP)";
BA_ "GenSigSendType" SG_ 835 MON_DiagSnsr_InCarTmp 4;
BA_ "UserSigValidity" SG_ 835 MON_DiagSnsr_InCarTmp 0;
BA_REL_ "GenSigTimeoutTime" BU_SG_REL_ L_ATCU SG_ 835 MON_DiagSnsr_InCarTmp 5000;
BA_ "Version" SG_ 835 MON_DiagSnsr_InCarTmp "25.05.04";
BA_ "Description" SG_ 835 MON_DiagSnsr_LHPhoto "This value only use for ATCU Library data monitoring (Only use before SOP)";
BA_ "GenSigSendType" SG_ 835 MON_DiagSnsr_LHPhoto 4;
BA_ "UserSigValidity" SG_ 835 MON_DiagSnsr_LHPhoto 0;
BA_REL_ "GenSigTimeoutTime" BU_SG_REL_ L_ATCU SG_ 835 MON_DiagSnsr_LHPhoto 5000;
BA_ "Version" SG_ 835 MON_DiagSnsr_LHPhoto "25.05.04";
BA_ "Description" SG_ 835 MON_DiagSnsr_LowPrsrRfgPT "This value only use for ATCU Library data monitoring (Only use before SOP)";
BA_ "GenSigSendType" SG_ 835 MON_DiagSnsr_LowPrsrRfgPT 4;
BA_ "UserSigValidity" SG_ 835 MON_DiagSnsr_LowPrsrRfgPT 0;
BA_REL_ "GenSigTimeoutTime" BU_SG_REL_ L_ATCU SG_ 835 MON_DiagSnsr_LowPrsrRfgPT 5000;
BA_ "Version" SG_ 835 MON_DiagSnsr_LowPrsrRfgPT "25.05.04";
BA_ "Description" SG_ 835 MON_DiagSnsr_RHPhoto "This value only use for ATCU Library data monitoring (Only use before SOP)";
BA_ "GenSigSendType" SG_ 835 MON_DiagSnsr_RHPhoto 4;
BA_ "UserSigValidity" SG_ 835 MON_DiagSnsr_RHPhoto 0;
BA_REL_ "GenSigTimeoutTime" BU_SG_REL_ L_ATCU SG_ 835 MON_DiagSnsr_RHPhoto 5000;
BA_ "Version" SG_ 835 MON_DiagSnsr_RHPhoto "25.05.04";
BA_ "Description" SG_ 835 MON_DiagSnsr_AstVntDuctTmp "This value only use for ATCU Library data monitoring (Only use before SOP)";
BA_ "GenSigSendType" SG_ 835 MON_DiagSnsr_AstVntDuctTmp 4;
BA_ "UserSigValidity" SG_ 835 MON_DiagSnsr_AstVntDuctTmp 0;
BA_REL_ "GenSigTimeoutTime" BU_SG_REL_ L_ATCU SG_ 835 MON_DiagSnsr_AstVntDuctTmp 5000;
BA_ "Version" SG_ 835 MON_DiagSnsr_AstVntDuctTmp "25.05.04";
VAL_ 129 L_3HKBD_SW_Ver1 0 "0x00~0x7E:ASCII value" 126 "0x00~0x7E:ASCII value" 127 "Invalid" ;
VAL_ 129 L_3HKBD_SW_Ver2 0 "0x00~0x7E:ASCII value" 126 "0x00~0x7E:ASCII value" 127 "Invalid" ;
VAL_ 129 L_3HKBD_SW_Ver3 0 "0x00~0x7E:ASCII value" 126 "0x00~0x7E:ASCII value" 127 "Invalid" ;
VAL_ 130 L_3HKBD_Rr_TempActrFB 1023 "Error Indicator" ;
VAL_ 130 L_3HKBD_Rr_TempActrSt 0 "Normal" 1 "Open" 2 "Short" 3 "Stuck" ;
VAL_ 130 L_3HKBD_Rr_TempAsstActrFB 1023 "Error Indicator" ;
VAL_ 130 L_3HKBD_Rr_TempAsstActrSt 0 "Normal" 1 "Open" 2 "Short" 3 "Stuck" ;
VAL_ 130 L_3HKBD_RrDrModeActrFB 1023 "Error Indicator" ;
VAL_ 130 L_3HKBD_RrDrModeActrSt 0 "Normal" 1 "Open" 2 "Short" 3 "Stuck" ;
VAL_ 130 L_3HKBD_Rr_BLDCError 0 "No error" 1 "Over Current" 2 "Under Voltage" 3 "Over Voltage" 4 "Stall" 5 "Over Temperature" 6 "Controller Shutdown (Internal Error)" 7 "Current Limit" 8 "Limp mode" 9 "LIN Fail" 10 "RESERVED" 11 "RESERVED" 12 "RESERVED" 13 "RESERVED" 14 "RESERVED" 15 "RESERVED" ;
VAL_ 130 L_3HKBD_Rr_EvapVolVal 0 "0x0~0xFA:0~5V" 250 "0x0~0xFA:0~5V" 255 "Error Indicator" ;
VAL_ 131 L_3HKBD_ResetOpSta 0 "Normal" 1 "Reset Complete" 2 "Reset Fail" 3 "RESERVED" ;
VAL_ 132 L_3HKBD_RrTempDnSw 0 "Off" 1 "On" ;
VAL_ 132 L_3HKBD_RrTempUpSw 0 "Off" 1 "On" ;
VAL_ 132 L_3HKBD_RrAutoSw 0 "Off" 1 "On" ;
VAL_ 132 L_3HKBD_RrOffSw 0 "Off" 1 "On" ;
VAL_ 132 L_3HKBD_RrSyncSw 0 "Off" 1 "On" ;
VAL_ 132 L_3HKBD_RLStHtrSwReq 0 "Off" 1 "On" ;
VAL_ 132 L_3HKBD_RLStVentSwReq 0 "Off" 1 "On" ;
VAL_ 132 L_3HKBD_RRStHtrSwReq 0 "Off" 1 "On" ;
VAL_ 132 L_3HKBD_RRStVentSwReq 0 "Off" 1 "On" ;
VAL_ 132 L_3HKBD_RrBlwDnOffSw 0 "Off" 1 "On" ;
VAL_ 132 L_3HKBD_RrOnOffSet 0 "Default" 1 "On" 2 "Off" 3 "Invalid" ;
VAL_ 132 L_3HKBD_RrBlwDnSw 0 "Off" 1 "On" ;
VAL_ 132 L_3HKBD_RrblwUpMaxSw 0 "Off" 1 "On" ;
VAL_ 132 L_3HKBD_RrBlwUpSw 0 "Off" 1 "On" ;
VAL_ 132 L_3HKBD_RrModeDnSw 0 "Off" 1 "On" ;
VAL_ 132 L_3HKBD_RrModeUpSw 0 "Off" 1 "On" ;
VAL_ 132 L_3HKBD_RrModeSw 0 "Off" 1 "On" ;
VAL_ 132 L_3HKBD_RrModeVentSw 0 "Off" 1 "On" ;
VAL_ 132 L_3HKBD_RrModeFloorSw 0 "Off" 1 "On" ;
VAL_ 132 L_3HKBD_RrModeBiLvlSw 0 "Off" 1 "On" ;
VAL_ 133 L_3HKBD_RrDrFlrDuctSnsr 0 "0x0~0xFA:0~5V" 250 "0x0~0xFA:0~5V" 255 "Error Indicator" ;
VAL_ 133 L_3HKBD_RrPsFlrDuctSnsr 0 "0x0~0xFA:0 ~ 5V" 250 "0x0~0xFA:0 ~ 5V" 255 "Error Indicator" ;
VAL_ 133 L_3HKBD_RrPsVntDuctSnsr 0 "0x0~0xFA:0 ~ 5V" 250 "0x0~0xFA:0 ~ 5V" 255 "Error Indicator" ;
VAL_ 133 L_3HKBD_RrPsModeActrFB 1023 "Error Indicator" ;
VAL_ 133 L_3HKBD_RrDrVntDuctSnsr 0 "0x0~0xFA:0~5V" 250 "0x0~0xFA:0~5V" 255 "Error Indicator" ;
VAL_ 134 L_3HKBD_RrTempClickCnt 0 "RESERVED" 1 "01~0x7F:Clockwise" 127 "01~0x7F:Clockwise" 128 "80~0xFE:Counter Clockwise" 254 "80~0xFE:Counter Clockwise" 255 "Invalid" ;
VAL_ 134 L_3HKBD_TempKnobCnt 0 "0" 1 "1" 2 "2" 3 "invalid" ;
VAL_ 134 L_3HKBD_BlwKnobCnt 0 "0" 1 "1" 2 "2" 3 "invalid" ;
VAL_ 134 L_3HKBD_HVACPnlBckLight_Res 0 "Invalid(Default)" 1 "On" 2 "Off" 3 "RESERVED" ;
VAL_ 134 L_3HKBD_RrBlwrClickCnt 0 "RESERVED" 1 "01~0x7F:Clockwise" 127 "01~0x7F:Clockwise" 128 "80~0xFE:Counter Clockwise" 254 "80~0xFE:Counter Clockwise" 255 "Invalid" ;
VAL_ 136 L_3HKBD_Rr_HVACBLDCMtrVolt 0 "0x00~0xFE:Voltage = HEX * 0.1 + 0" 254 "0x00~0xFE:Voltage = HEX * 0.1 + 0" 255 "Invalid" ;
VAL_ 136 L_3HKBD_Rr_HVACBLDCOverCurrent 0 "Normal (Default)" 1 "Error" ;
VAL_ 136 L_3HKBD_Rr_HVACBLDMotFltUnderVtg 0 "Normal (Default)" 1 "Error" ;
VAL_ 136 L_3HKBD_Rr_HVACBLDMotFltOverVtg 0 "Normal (Default)" 1 "Error" ;
VAL_ 136 L_3HKBD_Rr_HVACBLDCMotFltStall 0 "Normal (Default)" 1 "Error" ;
VAL_ 136 L_3HKBD_Rr_HVACBLDCMotOverTemp 0 "Normal (Default)" 1 "Error" ;
VAL_ 136 L_3HKBD_Rr_HVACBLDCMotCurrentLmt 0 "Normal (Default)" 1 "Error" ;
VAL_ 136 L_3HKBD_Rr_HVACBLDCMotCtrlShtdwn 0 "Normal (Default)" 1 "Error" ;
VAL_ 136 L_3HKBD_Rr_HVACBLDCMotLimpMod 0 "Normal (Default)" 1 "Error" ;
VAL_ 136 L_3HKBD_RrPsModeActrSt 0 "Normal" 1 "Open" 2 "Short" 3 "Stuck" ;
VAL_ 136 L_3HKBD_Rr_HVACBLDCMotLINFail 0 "Normal (Default)" 1 "Error" ;
VAL_ 136 L_3HKBD_Rr_HVACBLDCMtrA 0 "0x00~0xFE:Voltage = HEX * 0.1 + 0" 254 "0x00~0xFE:Voltage = HEX * 0.1 + 0" 255 "Invalid" ;
VAL_ 353 L_ATCU_HU_FrDrEVntModeSet 0 "Default" 1 "FOCUS Mode" 2 "SPREAD Mode" 3 "CYCLE Mode" 4 "FREE Mode" 5 "OFF" 6 "RESERVED" 7 "RESERVED" 8 "RESERVED" 9 "RESERVED" 10 "RESERVED" 11 "RESERVED" 12 "RESERVED" 13 "RESERVED" 14 "RESERVED" 15 "Invalid" ;
VAL_ 353 L_ATCU_HU_FrDrEVntCtrOpnCls 0 "Default" 1 "OPEN" 2 "CLOSE" 3 "Invalid" ;
VAL_ 353 L_ATCU_HU_FrPsEVntSideOpnCls 0 "Default" 1 "OPEN" 2 "CLOSE" 3 "Invalid" ;
VAL_ 353 L_ATCU_HU_FrPsEVntCtrOpnCls 0 "Default" 1 "OPEN" 2 "CLOSE" 3 "Invalid" ;
VAL_ 353 L_ATCU_HU_FrtEvntFocusLvlSet 0 "Default" 1 "1 Level" 2 "2 Level" 3 "3 Level" 4 "4 Level" 5 "5 Level" 6 "RESERVED" 7 "Invalid" ;
VAL_ 353 L_ATCU_HU_FrPsEVntModeSet 0 "Default" 1 "FOCUS Mode" 2 "SPREAD Mode" 3 "CYCLE Mode" 4 "FREE Mode" 5 "OFF" 6 "RESERVED" 7 "RESERVED" 8 "RESERVED" 9 "RESERVED" 10 "RESERVED" 11 "RESERVED" 12 "RESERVED" 13 "RESERVED" 14 "RESERVED" 15 "Invalid" ;
VAL_ 353 L_ATCU_HU_FrDrEVntSideOpnCls 0 "Default" 1 "OPEN" 2 "CLOSE" 3 "Invalid" ;
VAL_ 354 L_ATCU_CTS_FrtDrEVntModeSet 0 "Default" 1 "FOCUS Mode" 2 "SPREAD Mode" 3 "CYCLE Mode" 4 "FREE Mode" 5 "OFF" 6 "RESERVED" 7 "RESERVED" 8 "RESERVED" 9 "RESERVED" 10 "RESERVED" 11 "RESERVED" 12 "RESERVED" 13 "RESERVED" 14 "RESERVED" 15 "Invalid" ;
VAL_ 354 L_ATCU_CTS_FrDrEVntCtrOpnCls 0 "Default" 1 "OPEN" 2 "CLOSE" 3 "Invalid" ;
VAL_ 354 L_ATCU_CTS_FrPsEVntSideOpnCls 0 "Default" 1 "OPEN" 2 "CLOSE" 3 "Invalid" ;
VAL_ 354 L_ATCU_CTS_FrPsEVntCtrOpnCls 0 "Default" 1 "OPEN" 2 "CLOSE" 3 "Invalid" ;
VAL_ 354 L_ATCU_CTS_RrEvntFocusLvlSet 0 "Default" 1 "1 Level" 2 "2 Level" 3 "3 Level" 4 "4 Level" 5 "5 Level" 6 "RESERVED" 7 "Invalid" ;
VAL_ 354 L_ATCU_CTS_FrtPsEVntModeSet 0 "Default" 1 "FOCUS Mode" 2 "SPREAD Mode" 3 "CYCLE Mode" 4 "FREE Mode" 5 "OFF" 6 "RESERVED" 7 "RESERVED" 8 "RESERVED" 9 "RESERVED" 10 "RESERVED" 11 "RESERVED" 12 "RESERVED" 13 "RESERVED" 14 "RESERVED" 15 "Invalid" ;
VAL_ 354 L_ATCU_CTS_FrDrEVntSideOpnCls 0 "Default" 1 "OPEN" 2 "CLOSE" 3 "Invalid" ;
VAL_ 856 L_ATCU_Lib_AutoStepInd 0 "Off" 1 "1Step" 2 "2Step" 3 "3Step" ;
VAL_ 856 L_ATCU_Lib_BlrSym 0 "Off" 1 "On" ;
VAL_ 856 L_ATCU_Lib_BlrStepSym 0 "Off" 1 "1Step" 2 "2Step" 3 "3Step" 4 "4Step" 5 "5Step" 6 "6Step" 7 "7Step" 8 "8Step" 9 "RESERVED" 10 "RESERVED" 11 "RESERVED" 12 "RESERVED" 13 "RESERVED" 14 "RESERVED" 15 "RESERVED" ;
VAL_ 856 L_ATCU_Lib_IntakeRECInd 0 "Off" 1 "On" ;
VAL_ 856 L_ATCU_Lib_IntakeFREInd 0 "Off" 1 "On" ;
VAL_ 856 L_ATCU_Lib_ACInd 0 "Off" 1 "On" ;
VAL_ 856 L_ATCU_Lib_DEFInd 0 "Off" 1 "On" ;
VAL_ 856 L_ATCU_Lib_SyncInd 0 "Off" 1 "On" ;
VAL_ 856 L_ATCU_Lib_AutoBlrStepSym 0 "Off" 1 "Low" 2 "Mid" 3 "High" ;
VAL_ 856 L_ATCU_Lib_DrvOnly 0 "Off" 1 "On" ;
VAL_ 856 L_ATCU_Lib_ADSSym 0 "Off" 1 "On" ;
VAL_ 856 L_ATCU_Lib_ModVentInd 0 "Off" 1 "On" ;
VAL_ 856 L_ATCU_Lib_DrvTempSym 0 "Off" 1 "01~0xA4:RESERVED" 164 "01~0xA4:RESERVED" 165 "A5~0x10E:16.5~27.0¡É" 270 "A5~0x10E:16.5~27.0¡É" 271 "10F~0x261:RESERVED" 609 "10F~0x261:RESERVED" 610 "262~0x334:61~82£Æ" 820 "262~0x334:61~82£Æ" 821 "335~0xFFFF:RESERVED" 65535 "335~0xFFFF:RESERVED" ;
VAL_ 856 L_ATCU_Lib_ModSym 0 "Off" 1 "Floor" 2 "Vent" 3 "BL" 4 "Def_EU" 5 "Mix" 6 "Def_Vent" 7 "All" 8 "RESERVED" 9 "RESERVED" 10 "RESERVED" 11 "RESERVED" 12 "Def" 13 "RESERVED" 14 "RESERVED" 15 "None" ;
VAL_ 856 L_ATCU_Lib_AstTempSym 0 "Off" 1 "01~0xA4:RESERVED" 164 "01~0xA4:RESERVED" 165 "A5~0x10E:16.5~27.0¡É" 270 "A5~0x10E:16.5~27.0¡É" 271 "10F~0x261:RESERVED" 609 "10F~0x261:RESERVED" 610 "262~0x334:61~82£Æ" 820 "262~0x334:61~82£Æ" 821 "335~0xFFFF:RESERVED" 65535 "335~0xFFFF:RESERVED" ;
VAL_ 856 L_ATCU_Lib_DrvTempUnitSym 0 "Off" 1 "Celsius" 2 "Fahrenheit" 3 "RESERVED" ;
VAL_ 856 L_ATCU_Lib_ModFloorInd 0 "Off" 1 "On" ;
VAL_ 856 L_ATCU_Lib_ModDEFInd 0 "Off" 1 "On" ;
VAL_ 857 L_ATCU_Lib_2LHAutoStepInd 0 "Off" 1 "1Step" 2 "2Step" 3 "3Step" ;
VAL_ 857 L_ATCU_Lib_2ndACInd 0 "Off" 1 "On" ;
VAL_ 857 L_ATCU_Lib_2ndSyncInd 0 "Off" 1 "On" ;
VAL_ 857 L_ATCU_Lib_2ndLockInd 0 "Off" 1 "On" ;
VAL_ 857 L_ATCU_Lib_2LHBlrSym 0 "Off" 1 "On" ;
VAL_ 857 L_ATCU_Lib_2LHTempSym 0 "Off" 1 "01~0xA4:RESERVED" 164 "01~0xA4:RESERVED" 165 "A5~0x10E:16.5~27.0¡É" 270 "A5~0x10E:16.5~27.0¡É" 271 "10F~0x261:RESERVED" 609 "10F~0x261:RESERVED" 610 "262~0x334:61~82£Æ" 820 "262~0x334:61~82£Æ" 821 "335~0xFFFF:RESERVED" 65535 "335~0xFFFF:RESERVED" ;
VAL_ 857 L_ATCU_Lib_2LHAutoBlrStepSym 0 "Off" 1 "Low" 2 "Mid" 3 "High" ;
VAL_ 857 L_ATCU_Lib_2LHTempUnit 0 "Off" 1 "Celsius" 2 "Fahrenheit" ;
VAL_ 857 L_ATCU_Lib_2LHModSym 0 "Off" 1 "Floor" 2 "Vent" 3 "BL" 4 "Def_EU" 5 "Mix" 6 "Def_Vent" 7 "All" 8 "RESERVED" 9 "RESERVED" 10 "RESERVED" 11 "RESERVED" 12 "Def" 13 "RESERVED" 14 "RESERVED" 15 "None" ;
VAL_ 857 L_ATCU_Lib_FineDustTreeSym 0 "Off" 1 "Wood" ;
VAL_ 857 L_ATCU_Lib_FineDustTreeColor 0 "Off" 1 "Mono" 2 "Blue" 3 "Green" 4 "Orange" 5 "Red" 6 "Yellow" 7 "White" 8 "RESERVED" 9 "RESERVED" 10 "RESERVED" 11 "RESERVED" 12 "RESERVED" 13 "RESERVED" 14 "Gray" 15 "RESERVED" ;
VAL_ 857 L_ATCU_Lib_FineDustBarStepSym 0 "Off" 1 "Blank" 2 "Good" 3 "Normal" 4 "Poor" 5 "VeryPoor" 6 "RESERVED" 7 "RESERVED" ;
VAL_ 857 L_ATCU_Lib_2LHBlrStepSym 0 "Off" 1 "1Step" 2 "2Step" 3 "3Step" 4 "4Step" 5 "5Step" 6 "6Step" 7 "7Step" 8 "8Step" 9 "RESERVED" 10 "RESERVED" 11 "RESERVED" 12 "RESERVED" 13 "RESERVED" 14 "RESERVED" 15 "RESERVED" ;
VAL_ 858 L_ATCU_Lib_USMDEFState 0 "NotApply" 1 "Off" 2 "On" 3 "Invalid" ;
VAL_ 858 L_ATCU_Lib_USMSmrtVentState 0 "NotApply" 1 "Off" 2 "On" 3 "Invalid" ;
VAL_ 858 L_ATCU_Lib_USMCoolHeatSeat 0 "NotApply" 1 "Off" 2 "On" 3 "Invalid" ;
VAL_ 858 L_ATCU_Lib_USMStrWhlHeater 0 "NotApply" 1 "Off" 2 "On" 3 "Invalid" ;
VAL_ 858 L_ATCU_Lib_USMUsrPrfleState 0 "Default" 1 "Guest" 2 "Profile1" 3 "Profile2" 4 "RESERVED" 5 "RESERVED" 6 "RESERVED" 7 "RESERVED" 8 "RESERVED" 9 "RESERVED" 10 "RESERVED" 11 "RESERVED" 12 "RESERVED" 13 "RESERVED" 14 "RESERVED" 15 "Invalid" ;
VAL_ 858 L_ATCU_Lib_USMAutoFreshState 0 "NotApply" 1 "Off" 2 "On" 3 "Invalid" ;
VAL_ 858 L_ATCU_Lib_USM2ndAutoOffState 0 "NotApply" 1 "Off" 2 "On" 3 "Invalid" ;
VAL_ 858 L_ATCU_Lib_USMRearLock 0 "NotApply" 1 "Off" 2 "On" 3 "Invalid" ;
VAL_ 858 L_ATCU_Lib_USMWshState 0 "NotApply" 1 "Off" 2 "On" 3 "Invalid" ;
VAL_ 858 L_ATCU_Lib_USMADSState 0 "NotApply" 1 "Off" 2 "On" 3 "Invalid" ;
VAL_ 858 L_ATCU_Lib_USMTempUnitState 0 "Off" 1 "Celsius" 2 "Fahrenheit" 3 "Invalid" ;
VAL_ 858 L_ATCU_Lib_USMAfterBlowState 0 "NotApply" 1 "Off" 2 "On" 3 "Invalid" ;
VAL_ 858 L_ATCU_Lib_USMSchdldVent 0 "NotApply" 1 "Off" 2 "On" 3 "Invalid" ;
VAL_ 859 L_ATCU_Lib_Opt2LHModSwTyp 0 "Mode1Btn" 1 "Mode2Btn" 2 "Mode3Btn" 3 "RESERVED" ;
VAL_ 859 L_ATCU_Lib_Opt2ndModBtn 0 "Single" 1 "Dual" 2 "Off" 3 "RESERVED" ;
VAL_ 859 L_ATCU_Lib_Opt2ndOffSwTyp 0 "OffSw" 1 "OnOffSw" 2 "BlrDnOff" 3 "RESERVED" ;
VAL_ 859 L_ATCU_Lib_Opt2ndTmpBtn 0 "Single" 1 "Dual" 2 "Off" 3 "RESERVED" ;
VAL_ 859 L_ATCU_Lib_OptADS 0 "NotApply" 1 "Apply" ;
VAL_ 859 L_ATCU_Lib_OptAfterBlow 0 "NotApply" 1 "Apply" ;
VAL_ 859 L_ATCU_Lib_OptAutoStep 0 "NotApply" 1 "1Step" 2 "2Step" 3 "3Step" ;
VAL_ 859 L_ATCU_Lib_Opt2ndAutoBtn 0 "Single" 1 "Dual" 2 "Off" 3 "RESERVED" ;
VAL_ 859 L_ATCU_Lib_OptAutoSwTyp 0 "Auto1Btn" 1 "Auto2Btn" ;
VAL_ 859 L_ATCU_Lib_OptBATCoolingTyp 0 "AirCooling" 1 "WaterCooling" 2 "NotApply" 3 "RESERVED" ;
VAL_ 859 L_ATCU_Lib_OptBlrSwKnob 0 "ButtonType" 1 "KnobType" ;
VAL_ 859 L_ATCU_Lib_OptComp 0 "Internal_Comp" 1 "External_Comp_withClutch" 2 "External_Comp_withoutClutch" 3 "Fixed_Comp" 4 "Electric_Comp" 5 "RESERVED" 6 "RESERVED" 7 "RESERVED" ;
VAL_ 859 L_ATCU_Lib_OptDrvHndSide 0 "LHD" 1 "RHD" ;
VAL_ 859 L_ATCU_Lib_OptDrvOnly 0 "NotApply" 1 "Apply" ;
VAL_ 859 L_ATCU_Lib_OptFineDust 0 "NotApply" 1 "Apply" ;
VAL_ 859 L_ATCU_Lib_OptCoolHeatSeat 0 "NotApply" 1 "1Step" 2 "2Step" 3 "3Step" ;
VAL_ 859 L_ATCU_Lib_OptPTCTyp 0 "High_Vtg" 1 "Low_Vtg" 2 "NotApply" 3 "RESERVED" ;
VAL_ 859 L_ATCU_Lib_OptLCDDisp 0 "NotApply" 1 "MonoSeg" 2 "ColorSeg" 3 "TFT" ;
VAL_ 859 L_ATCU_Lib_OptModSwTyp 0 "Mode1Btn" 1 "Mode2Btn" 2 "Mode3Btn" 3 "RESERVED" ;
VAL_ 859 L_ATCU_Lib_OptOffSwTyp 0 "OffSw" 1 "OnOffSw" 2 "BlrDnOff" 3 "RESERVED" ;
VAL_ 859 L_ATCU_Lib_Opt2ndAutoStep 0 "NotApply" 1 "1Step" 2 "2Step" 3 "3Step" ;
VAL_ 859 L_ATCU_Lib_OptNetworkTyp 0 "CAN_Master" 1 "3Gen" 2 "2Gen" 3 "RESERVED" 4 "RESERVED" 5 "RESERVED" 6 "RESERVED" 7 "RESERVED" ;
VAL_ 859 L_ATCU_Lib_OptPTCStep 0 "PTC1Step" 1 "PTC2Step" 2 "RESERVED" 3 "RESERVED" ;
VAL_ 859 L_ATCU_Lib_OptPTG 0 "NotApply" 1 "Apply" ;
VAL_ 859 L_ATCU_Lib_OptROATyp 0 "NotApply" 1 "Apply" ;
VAL_ 859 L_ATCU_Lib_OptVRLED 0 "NotApply" 1 "Apply" ;
VAL_ 859 L_ATCU_Lib_OptRgn 0 "DOM" 1 "GEN" 2 "MID" 3 "EU" 4 "AUS" 5 "CAN" 6 "NA" 7 "CHN" 8 "RUS" 9 "IND" 10 "BZL" 11 "MEX" 12 "RESERVED" 13 "RESERVED" 14 "RESERVED" 15 "RESERVED" ;
VAL_ 859 L_ATCU_Lib_OptSchdldVent 0 "NotApply" 1 "Apply" ;
VAL_ 859 L_ATCU_Lib_OptIntakeSwTyp 0 "Intake1Btn" 1 "Intake2Btn" ;
VAL_ 859 L_ATCU_Lib_OptStrHeat 0 "NotApply" 1 "1Step" 2 "2Step" 3 "RESERVED" ;
VAL_ 859 L_ATCU_Lib_OptSync 0 "NotApply" 1 "Apply" ;
VAL_ 859 L_ATCU_Lib_OptTempSwKnob 0 "ButtonType" 1 "KnobType" ;
VAL_ 859 L_ATCU_Lib_OptThermostat 0 "NotApply" 1 "Apply" ;
VAL_ 859 L_ATCU_Lib_OptVehTyp 0 "Gasoline" 1 "Diesel" 2 "LPI" 3 "HEV" 4 "PHEV" 5 "EV" 6 "FCEV" 7 "RESERVED" ;
VAL_ 859 L_ATCU_Lib_Opt2ndAutoSwTyp 0 "Auto1Btn" 1 "Auto2Btn" ;
VAL_ 859 L_ATCU_Lib_OptWheelDrivePos 0 "Front" 1 "Rear" 2 "4WD" 3 "RESERVED" ;
VAL_ 859 L_ATCU_Lib_Opt2ndTempSwKnob 0 "ButtonType" 1 "KnobType" ;
VAL_ 859 L_ATCU_Lib_Opt2ndBlrBtn 0 "Single" 1 "Dual" 2 "Off" 3 "RESERVED" ;
VAL_ 860 L_ATCU_Lib_MngrModBufCnt 0 "BufferCnt" 1 "BufferCnt" 2 "BufferCnt" 3 "BufferCnt" 4 "BufferCnt" 5 "BufferCnt" 6 "BufferCnt" 7 "BufferCnt" 8 "BufferCnt" 9 "BufferCnt" 10 "BufferCnt" 11 "BufferCnt" 12 "BufferCnt" 13 "BufferCnt" 14 "BufferCnt" 15 "BufferCnt" 16 "RESERVED" 17 "RESERVED" 18 "RESERVED" 19 "RESERVED" 20 "RESERVED" 21 "RESERVED" 22 "RESERVED" 23 "RESERVED" 24 "RESERVED" 25 "RESERVED" 26 "RESERVED" 27 "RESERVED" 28 "RESERVED" 29 "RESERVED" 30 "RESERVED" 31 "RESERVED" ;
VAL_ 860 L_ATCU_Lib_MngrDEFBufCnt 0 "BufferCnt" 1 "BufferCnt" 2 "BufferCnt" 3 "BufferCnt" 4 "RESERVED" 5 "RESERVED" 6 "RESERVED" 7 "RESERVED" ;
VAL_ 860 L_ATCU_Lib_MngrBlwBufCnt 0 "BufferCnt" 1 "BufferCnt" 2 "BufferCnt" 3 "BufferCnt" 4 "BufferCnt" 5 "BufferCnt" 6 "BufferCnt" 7 "BufferCnt" 8 "BufferCnt" 9 "BufferCnt" 10 "RESERVED" 11 "RESERVED" 12 "RESERVED" 13 "RESERVED" 14 "RESERVED" 15 "RESERVED" ;
VAL_ 860 L_ATCU_Lib_MngrACBufCnt 0 "BufferCnt" 1 "BufferCnt" 2 "BufferCnt" 3 "BufferCnt" 4 "BufferCnt" 5 "BufferCnt" 6 "BufferCnt" 7 "BufferCnt" 8 "BufferCnt" 9 "BufferCnt" 10 "BufferCnt" 11 "RESERVED" 12 "RESERVED" 13 "RESERVED" 14 "RESERVED" 15 "RESERVED" ;
VAL_ 860 L_ATCU_Lib_2LHMngrBlwBufCnt 0 "BufferCnt" 1 "BufferCnt" 2 "BufferCnt" 3 "BufferCnt" 4 "BufferCnt" 5 "BufferCnt" 6 "BufferCnt" 7 "RESERVED" 8 "RESERVED" 9 "RESERVED" 10 "RESERVED" 11 "RESERVED" 12 "RESERVED" 13 "RESERVED" 14 "RESERVED" 15 "RESERVED" ;
VAL_ 860 L_ATCU_Lib_2LHMngrModBufCnt 0 "BufferCnt" 1 "BufferCnt" 2 "BufferCnt" 3 "BufferCnt" 4 "BufferCnt" 5 "BufferCnt" 6 "BufferCnt" 7 "BufferCnt" 8 "BufferCnt" 9 "RESERVED" 10 "RESERVED" 11 "RESERVED" 12 "RESERVED" 13 "RESERVED" 14 "RESERVED" 15 "RESERVED" ;
VAL_ 860 L_ATCU_Lib_2LHMngrTempBufCnt 0 "BufferCnt" 1 "BufferCnt" 2 "BufferCnt" 3 "BufferCnt" 4 "RESERVED" 5 "RESERVED" 6 "RESERVED" 7 "RESERVED" ;
VAL_ 860 L_ATCU_Lib_2RHMngrTempBufCnt 0 "BufferCnt" 1 "BufferCnt" 2 "BufferCnt" 3 "BufferCnt" 4 "RESERVED" 5 "RESERVED" 6 "RESERVED" 7 "RESERVED" ;
VAL_ 860 L_ATCU_Lib_MngrTempBufCnt 0 "BufferCnt" 1 "BufferCnt" 2 "BufferCnt" 3 "BufferCnt" 4 "BufferCnt" 5 "BufferCnt" 6 "RESERVED" 7 "RESERVED" ;
VAL_ 860 L_ATCU_Lib_MngrIntakeBufCnt 0 "BufferCnt" 1 "BufferCnt" 2 "BufferCnt" 3 "BufferCnt" 4 "BufferCnt" 5 "BufferCnt" 6 "BufferCnt" 7 "BufferCnt" 8 "BufferCnt" 9 "BufferCnt" 10 "BufferCnt" 11 "BufferCnt" 12 "BufferCnt" 13 "BufferCnt" 14 "BufferCnt" 15 "BufferCnt" 16 "BufferCnt" 17 "BufferCnt" 18 "BufferCnt" 19 "BufferCnt" 20 "BufferCnt" 21 "BufferCnt" 22 "BufferCnt" 23 "BufferCnt" 24 "BufferCnt" 25 "BufferCnt" 26 "BufferCnt" 27 "RESERVED" 28 "RESERVED" 29 "RESERVED" 30 "RESERVED" 31 "RESERVED" ;
VAL_ 861 L_ATCU_Lib_MngrModBufOp 0 "KeyOff" 1 "FloorPurge" 2 "RemoteFATC" 3 "RemoteFATC_DEF" 4 "SMKRemoteFATC" 5 "ManualSw_DEF" 6 "ManualSw" 7 "MaxCool" 8 "HotStart" 9 "ADS" 10 "FootZone" 11 "MaxHot" 12 "SchdldVent" 13 "AfterBlow" 14 "Auto" 15 "Num" 16 "RESERVED" 17 "RESERVED" 18 "RESERVED" 19 "RESERVED" 20 "RESERVED" 21 "RESERVED" 22 "RESERVED" 23 "RESERVED" 24 "RESERVED" 25 "RESERVED" 26 "RESERVED" 27 "RESERVED" 28 "RESERVED" 29 "RESERVED" 30 "RESERVED" 31 "RESERVED" ;
VAL_ 861 L_ATCU_Lib_MngrDEFBufOp 0 "KeyOff" 1 "FloorPuge" 2 "Mode" 3 "Num" 4 "RESERVED" 5 "RESERVED" 6 "RESERVED" 7 "RESERVED" ;
VAL_ 861 L_ATCU_Lib_MngrBlwBufOp 0 "StartBlower" 1 "SmartVentForcedOn" 2 "SmartVent" 3 "MaxCool" 4 "HotStart" 5 "MaxHot" 6 "ManualSw" 7 "SchdldVent" 8 "AfterBlow" 9 "Auto" 10 "Num" 11 "RESERVED" 12 "RESERVED" 13 "RESERVED" 14 "RESERVED" 15 "RESERVED" ;
VAL_ 861 L_ATCU_Lib_MngrACBufOp 0 "DEF" 1 "RemoteFATC_DEF" 2 "SMKRemoteFATC" 3 "Washer" 4 "MIX" 5 "AirPurify" 6 "ADS" 7 "ManualSw" 8 "MAXCool" 9 "Auto" 10 "Num" 11 "RESERVED" 12 "RESERVED" 13 "RESERVED" 14 "RESERVED" 15 "RESERVED" ;
VAL_ 861 L_ATCU_Lib_2LHMngrBlwBufOp 0 "StartBlower" 1 "MaxCool" 2 "HotStart" 3 "MaxHot" 4 "ManualSw" 5 "Auto" 6 "Num" 7 "RESERVED" 8 "RESERVED" 9 "RESERVED" 10 "RESERVED" 11 "RESERVED" 12 "RESERVED" 13 "RESERVED" 14 "RESERVED" 15 "RESERVED" ;
VAL_ 861 L_ATCU_Lib_2LHMngrModBufOp 0 "KeyOff" 1 "FloorPurge" 2 "ManualSw" 3 "MaxCool" 4 "HotStart" 5 "FootZone" 6 "MaxHot" 7 "Auto" 8 "Num" 9 "RESERVED" 10 "RESERVED" 11 "RESERVED" 12 "RESERVED" 13 "RESERVED" 14 "RESERVED" 15 "RESERVED" ;
VAL_ 861 L_ATCU_Lib_2LHMngrTempBufOp 0 "MaxCool" 1 "MaxHot" 2 "Auto" 3 "Num" 4 "RESERVED" 5 "RESERVED" 6 "RESERVED" 7 "RESERVED" ;
VAL_ 861 L_ATCU_Lib_2RHMngrTempBufOp 0 "MaxCool" 1 "MaxHot" 2 "Auto" 3 "Num" 4 "RESERVED" 5 "RESERVED" 6 "RESERVED" 7 "RESERVED" ;
VAL_ 861 L_ATCU_Lib_MngrActvIncarMotPwr 0 "Off" 1 "On" ;
VAL_ 861 L_ATCU_Lib_MngrPDCWakeUpReq 0 "Off" 1 "On" ;
VAL_ 861 L_ATCU_Lib_MngrLVPTCRly1Sta 0 "Off" 1 "On" ;
VAL_ 861 L_ATCU_Lib_MngrLVPTCRly2Sta 0 "Off" 1 "On" ;
VAL_ 861 L_ATCU_Lib_MngrLVPTCRly3Sta 0 "Off" 1 "On" ;
VAL_ 861 L_ATCU_Lib_MngrTempBufOp 0 "MaxCool" 1 "MaxHot" 2 "Last" 3 "AfterBlow" 4 "Auto" 5 "Num" 6 "RESERVED" 7 "RESERVED" ;
VAL_ 861 L_ATCU_Lib_MngrIntakeBufOp 0 "KeyOff" 1 "SmartVencForcedOn" 2 "RemoteFATC" 3 "RemoteFATC_DEF" 4 "AutoWash" 5 "Washer" 6 "ADS" 7 "Sunroof" 8 "Tunnel" 9 "AirPurify" 10 "DEF" 11 "MIX" 12 "FloorPurge" 13 "AQS_REC" 14 "AQS_FRE" 15 "FREbyTime" 16 "protectEvapRust" 17 "ManualSw_FRE" 18 "ManualSw_REC" 19 "SmrtVent" 20 "SysOff" 21 "MaxHot" 22 "MaxCool" 23 "StayMod" 24 "SchdldVent" 25 "AfterBlow" 26 "Auto_REC" 27 "Auto_FRE" 28 "Num" 29 "RESERVED" 30 "RESERVED" 31 "RESERVED" ;
VAL_ 862 L_ATCU_Lib_MngrModBuf0 0 "KeyOff" 1 "RemoteFATC" 2 "RemoteFATC_DEF" 3 "SMKRemoteFATC" 4 "ManualSw_DEF" 5 "ManualSw" 6 "MaxCool" 7 "HotStart" 8 "ADS" 9 "FootZone" 10 "MaxHot" 11 "SchdldVent" 12 "AfterBlow" 13 "Auto" 14 "Num" 16 "RESERVED" 17 "RESERVED" 18 "RESERVED" 19 "RESERVED" 20 "RESERVED" 21 "RESERVED" 22 "RESERVED" 23 "RESERVED" 24 "RESERVED" 25 "RESERVED" 26 "RESERVED" 27 "RESERVED" 28 "RESERVED" 29 "RESERVED" 30 "RESERVED" 31 "RESERVED" ;
VAL_ 862 L_ATCU_Lib_MngrModBufLow1 0 "PECbyFLR" 1 "QuickFog" 2 "Num" 3 "RESERVED" ;
VAL_ 862 L_ATCU_Lib_MngrModBuf2 0 "KeyOff" 1 "RemoteFATC" 2 "RemoteFATC_DEF" 3 "SMKRemoteFATC" 4 "ManualSw_DEF" 5 "ManualSw" 6 "MaxCool" 7 "HotStart" 8 "ADS" 9 "FootZone" 10 "MaxHot" 11 "SchdldVent" 12 "AfterBlow" 13 "Auto" 14 "Num" 16 "RESERVED" 17 "RESERVED" 18 "RESERVED" 19 "RESERVED" 20 "RESERVED" 21 "RESERVED" 22 "RESERVED" 23 "RESERVED" 24 "RESERVED" 25 "RESERVED" 26 "RESERVED" 27 "RESERVED" 28 "RESERVED" 29 "RESERVED" 30 "RESERVED" 31 "RESERVED" ;
VAL_ 862 L_ATCU_Lib_MngrModBufHi0 0 "PECbyFLR" 1 "QuickFog" 2 "Num" 3 "RESERVED" ;
VAL_ 862 L_ATCU_Lib_MngrModBuf3 0 "KeyOff" 1 "RemoteFATC" 2 "RemoteFATC_DEF" 3 "SMKRemoteFATC" 4 "ManualSw_DEF" 5 "ManualSw" 6 "MaxCool" 7 "HotStart" 8 "ADS" 9 "FootZone" 10 "MaxHot" 11 "SchdldVent" 12 "AfterBlow" 13 "Auto" 14 "Num" 16 "RESERVED" 17 "RESERVED" 18 "RESERVED" 19 "RESERVED" 20 "RESERVED" 21 "RESERVED" 22 "RESERVED" 23 "RESERVED" 24 "RESERVED" 25 "RESERVED" 26 "RESERVED" 27 "RESERVED" 28 "RESERVED" 29 "RESERVED" 30 "RESERVED" 31 "RESERVED" ;
VAL_ 862 L_ATCU_Lib_MngrModBufHi1 0 "PECbyFLR" 1 "QuickFog" 2 "Num" 3 "RESERVED" ;
VAL_ 862 L_ATCU_Lib_MngrModBuf4 0 "KeyOff" 1 "RemoteFATC" 2 "RemoteFATC_DEF" 3 "SMKRemoteFATC" 4 "ManualSw_DEF" 5 "ManualSw" 6 "MaxCool" 7 "HotStart" 8 "ADS" 9 "FootZone" 10 "MaxHot" 11 "SchdldVent" 12 "AfterBlow" 13 "Auto" 14 "Num" 16 "RESERVED" 17 "RESERVED" 18 "RESERVED" 19 "RESERVED" 20 "RESERVED" 21 "RESERVED" 22 "RESERVED" 23 "RESERVED" 24 "RESERVED" 25 "RESERVED" 26 "RESERVED" 27 "RESERVED" 28 "RESERVED" 29 "RESERVED" 30 "RESERVED" 31 "RESERVED" ;
VAL_ 862 L_ATCU_Lib_MngrModBuf5 0 "KeyOff" 1 "RemoteFATC" 2 "RemoteFATC_DEF" 3 "SMKRemoteFATC" 4 "ManualSw_DEF" 5 "ManualSw" 6 "MaxCool" 7 "HotStart" 8 "ADS" 9 "FootZone" 10 "MaxHot" 11 "SchdldVent" 12 "AfterBlow" 13 "Auto" 14 "Num" 16 "RESERVED" 17 "RESERVED" 18 "RESERVED" 19 "RESERVED" 20 "RESERVED" 21 "RESERVED" 22 "RESERVED" 23 "RESERVED" 24 "RESERVED" 25 "RESERVED" 26 "RESERVED" 27 "RESERVED" 28 "RESERVED" 29 "RESERVED" 30 "RESERVED" 31 "RESERVED" ;
VAL_ 862 L_ATCU_Lib_MngrModBuf6 0 "KeyOff" 1 "RemoteFATC" 2 "RemoteFATC_DEF" 3 "SMKRemoteFATC" 4 "ManualSw_DEF" 5 "ManualSw" 6 "MaxCool" 7 "HotStart" 8 "ADS" 9 "FootZone" 10 "MaxHot" 11 "SchdldVent" 12 "AfterBlow" 13 "Auto" 14 "Num" 16 "RESERVED" 17 "RESERVED" 18 "RESERVED" 19 "RESERVED" 20 "RESERVED" 21 "RESERVED" 22 "RESERVED" 23 "RESERVED" 24 "RESERVED" 25 "RESERVED" 26 "RESERVED" 27 "RESERVED" 28 "RESERVED" 29 "RESERVED" 30 "RESERVED" 31 "RESERVED" ;
VAL_ 862 L_ATCU_Lib_MngrModBufLow0 0 "PECbyFLR" 1 "QuickFog" 2 "Num" 3 "RESERVED" ;
VAL_ 862 L_ATCU_Lib_MngrModBuf7 0 "KeyOff" 1 "RemoteFATC" 2 "RemoteFATC_DEF" 3 "SMKRemoteFATC" 4 "ManualSw_DEF" 5 "ManualSw" 6 "MaxCool" 7 "HotStart" 8 "ADS" 9 "FootZone" 10 "MaxHot" 11 "SchdldVent" 12 "AfterBlow" 13 "Auto" 14 "Num" 16 "RESERVED" 17 "RESERVED" 18 "RESERVED" 19 "RESERVED" 20 "RESERVED" 21 "RESERVED" 22 "RESERVED" 23 "RESERVED" 24 "RESERVED" 25 "RESERVED" 26 "RESERVED" 27 "RESERVED" 28 "RESERVED" 29 "RESERVED" 30 "RESERVED" 31 "RESERVED" ;
VAL_ 862 L_ATCU_Lib_MngrModBuf1 0 "KeyOff" 1 "RemoteFATC" 2 "RemoteFATC_DEF" 3 "SMKRemoteFATC" 4 "ManualSw_DEF" 5 "ManualSw" 6 "MaxCool" 7 "HotStart" 8 "ADS" 9 "FootZone" 10 "MaxHot" 11 "SchdldVent" 12 "AfterBlow" 13 "Auto" 14 "Num" 16 "RESERVED" 17 "RESERVED" 18 "RESERVED" 19 "RESERVED" 20 "RESERVED" 21 "RESERVED" 22 "RESERVED" 23 "RESERVED" 24 "RESERVED" 25 "RESERVED" 26 "RESERVED" 27 "RESERVED" 28 "RESERVED" 29 "RESERVED" 30 "RESERVED" 31 "RESERVED" ;
VAL_ 863 L_ATCU_Lib_MngrBlwBuf0 0 "SmartVentForcedOn" 1 "SmartVent" 2 "MaxCool" 3 "HotStart" 4 "MaxHot" 5 "ManualSw" 6 "SchdldVent" 7 "AfterBlow" 8 "Auto" 9 "Num" 11 "RESERVED" 12 "RESERVED" 13 "RESERVED" 14 "RESERVED" 15 "RESERVED" ;
VAL_ 863 L_ATCU_Lib_MngrBlwBuf3 0 "SmartVentForcedOn" 1 "SmartVent" 2 "MaxCool" 3 "HotStart" 4 "MaxHot" 5 "ManualSw" 6 "SchdldVent" 7 "AfterBlow" 8 "Auto" 9 "Num" 11 "RESERVED" 12 "RESERVED" 13 "RESERVED" 14 "RESERVED" 15 "RESERVED" ;
VAL_ 863 L_ATCU_Lib_MngrBlwBuf4 0 "SmartVentForcedOn" 1 "SmartVent" 2 "MaxCool" 3 "HotStart" 4 "MaxHot" 5 "ManualSw" 6 "SchdldVent" 7 "AfterBlow" 8 "Auto" 9 "Num" 11 "RESERVED" 12 "RESERVED" 13 "RESERVED" 14 "RESERVED" 15 "RESERVED" ;
VAL_ 863 L_ATCU_Lib_MngrBlwBuf5 0 "SmartVentForcedOn" 1 "SmartVent" 2 "MaxCool" 3 "HotStart" 4 "MaxHot" 5 "ManualSw" 6 "SchdldVent" 7 "AfterBlow" 8 "Auto" 9 "Num" 11 "RESERVED" 12 "RESERVED" 13 "RESERVED" 14 "RESERVED" 15 "RESERVED" ;
VAL_ 863 L_ATCU_Lib_MngrBlwBuf6 0 "SmartVentForcedOn" 1 "SmartVent" 2 "MaxCool" 3 "HotStart" 4 "MaxHot" 5 "ManualSw" 6 "SchdldVent" 7 "AfterBlow" 8 "Auto" 9 "Num" 11 "RESERVED" 12 "RESERVED" 13 "RESERVED" 14 "RESERVED" 15 "RESERVED" ;
VAL_ 863 L_ATCU_Lib_MngrBlwBuf7 0 "SmartVentForcedOn" 1 "SmartVent" 2 "MaxCool" 3 "HotStart" 4 "MaxHot" 5 "ManualSw" 6 "SchdldVent" 7 "AfterBlow" 8 "Auto" 9 "Num" 11 "RESERVED" 12 "RESERVED" 13 "RESERVED" 14 "RESERVED" 15 "RESERVED" ;
VAL_ 863 L_ATCU_Lib_MngrBlwBufHi0 0 "AirFlowLinkage" 1 "ISG" 2 "SSC" 3 "Num" ;
VAL_ 863 L_ATCU_Lib_MngrBlwBufLow0 0 "RemoteFATC" 1 "DEF" 2 "AirPurify" 3 "ADS" 4 "Num" 5 "RESERVED" 6 "RESERVED" 7 "RESERVED" ;
VAL_ 863 L_ATCU_Lib_MngrBlwBufLow1 0 "RemoteFATC" 1 "DEF" 2 "AirPurify" 3 "ADS" 4 "Num" 5 "RESERVED" 6 "RESERVED" 7 "RESERVED" ;
VAL_ 863 L_ATCU_Lib_MngrBlwBuf1 0 "SmartVentForcedOn" 1 "SmartVent" 2 "MaxCool" 3 "HotStart" 4 "MaxHot" 5 "ManualSw" 6 "SchdldVent" 7 "AfterBlow" 8 "Auto" 9 "Num" 11 "RESERVED" 12 "RESERVED" 13 "RESERVED" 14 "RESERVED" 15 "RESERVED" ;
VAL_ 863 L_ATCU_Lib_MngrBlwBufHi1 0 "AirFlowLinkage" 1 "ISG" 2 "SSC" 3 "Num" ;
VAL_ 863 L_ATCU_Lib_MngrBlwBufLow2 0 "RemoteFATC" 1 "DEF" 2 "AirPurify" 3 "ADS" 4 "Num" 5 "RESERVED" 6 "RESERVED" 7 "RESERVED" ;
VAL_ 863 L_ATCU_Lib_MngrBlwBufLow3 0 "RemoteFATC" 1 "DEF" 2 "AirPurify" 3 "ADS" 4 "Num" 5 "RESERVED" 6 "RESERVED" 7 "RESERVED" ;
VAL_ 863 L_ATCU_Lib_MngrBlwBufHi2 0 "AirFlowLinkage" 1 "ISG" 2 "SSC" 3 "Num" ;
VAL_ 863 L_ATCU_Lib_MngrBlwBuf2 0 "SmartVentForcedOn" 1 "SmartVent" 2 "MaxCool" 3 "HotStart" 4 "MaxHot" 5 "ManualSw" 6 "SchdldVent" 7 "AfterBlow" 8 "Auto" 9 "Num" 11 "RESERVED" 12 "RESERVED" 13 "RESERVED" 14 "RESERVED" 15 "RESERVED" ;
VAL_ 913 L_ATCU_Lib_ADSBlrVtgVal 0 "0x0~0x34BC:0~13.500V" 13500 "0x0~0x34BC:0~13.500V" 13501 "34BD~0xFFFE:RESERVED" 65534 "34BD~0xFFFE:RESERVED" 65535 "None" ;
VAL_ 913 L_ATCU_Lib_ADSDEFDrState 0 "0x0~0x3E8:0~100.0%" 1000 "0x0~0x3E8:0~100.0%" 1001 "RESERVED" 1002 "RESERVED" 1003 "RESERVED" 1004 "RESERVED" 1005 "RESERVED" 1006 "RESERVED" 1007 "RESERVED" 1008 "RESERVED" 1009 "RESERVED" 1010 "RESERVED" 1011 "RESERVED" 1012 "RESERVED" 1013 "RESERVED" 1014 "RESERVED" 1015 "RESERVED" 1016 "RESERVED" 1017 "RESERVED" 1018 "RESERVED" 1019 "RESERVED" 1020 "RESERVED" 1021 "RESERVED" 1022 "RESERVED" 1023 "None" ;
VAL_ 913 L_ATCU_Lib_ADSACDispPreHoldReq 0 "Off" 1 "On" ;
VAL_ 913 L_ATCU_Lib_ADSACForcedOnReq 0 "Off" 1 "On" ;
VAL_ 913 L_ATCU_Lib_ADSACState 0 "Off" 1 "On" ;
VAL_ 913 L_ATCU_Lib_ADSInhibitPIReq 0 "Off" 1 "On" ;
VAL_ 913 L_ATCU_Lib_ADSModPrfleChgReq 0 "Off" 1 "On" ;
VAL_ 913 L_ATCU_Lib_ADSIntakeState 0 "FRE(0.0%)" 1 "1~0x3E7:Intake(0.1~99.9%)" 999 "1~0x3E7:Intake(0.1~99.9%)" 1000 "REC(100.0%)" 1001 "RESERVED" 1002 "RESERVED" 1003 "RESERVED" 1004 "RESERVED" 1005 "RESERVED" 1006 "RESERVED" 1007 "RESERVED" 1008 "RESERVED" 1009 "RESERVED" 1010 "RESERVED" 1011 "RESERVED" 1012 "RESERVED" 1013 "RESERVED" 1014 "RESERVED" 1015 "RESERVED" 1016 "RESERVED" 1017 "RESERVED" 1018 "RESERVED" 1019 "RESERVED" 1020 "RESERVED" 1021 "RESERVED" 1022 "RESERVED" 1023 "None" ;
VAL_ 913 L_ATCU_Lib_ADSTempDrLmtState 0 "0x0~0x3E8:0~100.0%" 1000 "0x0~0x3E8:0~100.0%" 1001 "RESERVED" 1002 "RESERVED" 1003 "RESERVED" 1004 "RESERVED" 1005 "RESERVED" 1006 "RESERVED" 1007 "RESERVED" 1008 "RESERVED" 1009 "RESERVED" 1010 "RESERVED" 1011 "RESERVED" 1012 "RESERVED" 1013 "RESERVED" 1014 "RESERVED" 1015 "RESERVED" 1016 "RESERVED" 1017 "RESERVED" 1018 "RESERVED" 1019 "RESERVED" 1020 "RESERVED" 1021 "RESERVED" 1022 "RESERVED" 1023 "None" ;
VAL_ 913 L_ATCU_Lib_ADSOpState 0 "Off" 1 "On" ;
VAL_ 913 L_ATCU_Lib_ADSSymState 0 "Off" 1 "On" ;
VAL_ 914 L_ATCU_Lib_PIIntakeState 0 "FRE(0.0%)" 1 "1~0x3E7:Intake(0.1~99.9%)" 999 "1~0x3E7:Intake(0.1~99.9%)" 1000 "REC(100.0%)" 1001 "RESERVED" 1002 "RESERVED" 1003 "RESERVED" 1004 "RESERVED" 1005 "RESERVED" 1006 "RESERVED" 1007 "RESERVED" 1008 "RESERVED" 1009 "RESERVED" 1010 "RESERVED" 1011 "RESERVED" 1012 "RESERVED" 1013 "RESERVED" 1014 "RESERVED" 1015 "RESERVED" 1016 "RESERVED" 1017 "RESERVED" 1018 "RESERVED" 1019 "RESERVED" 1020 "RESERVED" 1021 "RESERVED" 1022 "RESERVED" 1023 "None" ;
VAL_ 914 L_ATCU_Lib_AEWPOnReq 0 "Off" 1 "On" ;
VAL_ 914 L_ATCU_Lib_AEWPRPMVal 0 "0x0~0x2710:0~10000RPM" 10000 "0x0~0x2710:0~10000RPM" 10001 "2711~0xFFFE:RESERVED" 65534 "2711~0xFFFE:RESERVED" 65535 "None" ;
VAL_ 914 L_ATCULib_AmbFilterResetOpState 0 "Default (*)" 1 "Timer Request" 2 "Operation Request" 3 "RESERVED" ;
VAL_ 914 L_ATCULib_HVACIntlckHVActOffReq 0 "Off" 1 "On" ;
VAL_ 914 L_ATCULib_MainRlyProtectOpState 0 "Off" 1 "On" ;
VAL_ 914 L_ATCULib_ETCIntlckHVActOffReq 0 "Off" 1 "On" ;
VAL_ 914 L_ATCULib_SyncSwSta 0 "Off" 1 "SyncFrt" 2 "SyncRr" 3 "RESERVED" ;
